VERSION ""

NS_ :

BS_:

BU_: WCM VPM VLM VKM UVM TIM TEST_TOOL_2 TEST_TOOL_1 TCP TCM TCCM3 TCCM STC SRR_SRR SRR_SLR SRR_RR SRR_RF SRR_LR_CR SRR_LF SIB SDM SCL SBZA_R SBZA_L SBM SADS RadioLow RSC RDCM PTM PDR PA NVM MTCM_R MTCM_L MSM_RR MSM_P MSM_LR MSM_D MSB2 MSB1 MRCM_R MRCM_L MFC LRR_HC LRR LIB1 IPC ICS_Info ICCM HVAC_FP_R HVAC_FP_F HUD_CAN HDLM FCM_LC FCM EPS EOCM_HCP2 EOCM_HCP1 EOCM ELM ECP_X1 ECP_MC ECP_E ECM EBCM DMS DEFC DCM CSM CMMb CMMa CGM BSM_MH BSM BCM ARS ARB APA AOS AMP ALC AHS AHL_AFL AGC

BO_ 1208 GWCGM_31_PDU: 8 CGM
 SG_ TkModeDrvlineVisDispVal : 1|3@0+ (1,0) [0|7] "" CSM,RadioLow
 SG_ TkModeBrkPedVisDispVal : 4|3@0+ (1,0) [0|7] "" CSM,RadioLow
 SG_ TkModeActvAeroVisDispVal : 7|3@0+ (1,0) [0|7] "" CSM,RadioLow
 SG_ TkModeRideHghtVisDispVal : 8|3@0+ (1,0) [0|7] "" CSM,RadioLow
 SG_ TkModePwrtrnVisDispVal : 11|3@0+ (1,0) [0|7] "" CSM,RadioLow
 SG_ TkModeESCVisDispVal : 14|3@0+ (1,0) [0|7] "" CSM,RadioLow
 SG_ TkModeSpnsnVisDispVal : 18|3@0+ (1,0) [0|7] "" CSM,RadioLow
 SG_ TkModeSndVisDispVal : 21|3@0+ (1,0) [0|7] "" CSM,RadioLow
 SG_ WthrSnwModeBrkPedVisDispVal : 25|3@0+ (1,0) [0|7] "" CSM,RadioLow
 SG_ WthrSnwModeActvAeroVisDispVal : 28|3@0+ (1,0) [0|7] "" CSM,RadioLow
 SG_ TkModeStrgVisDispVal : 31|3@0+ (1,0) [0|7] "" CSM,RadioLow
 SG_ WthrSnwModePwrtrnVisDispVal : 32|3@0+ (1,0) [0|7] "" CSM,RadioLow
 SG_ WthrSnwModeESCVisDispVal : 35|3@0+ (1,0) [0|7] "" CSM,RadioLow
 SG_ WthrSnwModeDrvlineVisDispVal : 38|3@0+ (1,0) [0|7] "" CSM,RadioLow
 SG_ WthrSnwModeSndVisDispVal : 42|3@0+ (1,0) [0|7] "" CSM,RadioLow
 SG_ WthrSnwModeRideHghtVisDispVal : 45|3@0+ (1,0) [0|7] "" CSM,RadioLow
 SG_ TrcStbScrConfig : 49|2@0+ (1,0) [0|3] "" IPC
 SG_ WthrSnwModeStrgVisDispVal : 52|3@0+ (1,0) [0|7] "" CSM,RadioLow
 SG_ WthrSnwModeSpnsnVisDispVal : 55|3@0+ (1,0) [0|7] "" CSM,RadioLow
 SG_ TrcCntrlSysTmpDisReqIO : 59|1@0+ (1,0) [0|1] "" IPC
 SG_ TrcCntrlOnIO : 60|1@0+ (1,0) [0|1] "" CSM,IPC,TCP
 SG_ TrcCntrlOffIO : 61|1@0+ (1,0) [0|1] "" CSM,IPC,TCP
 SG_ TCSCustAv : 62|1@0+ (1,0) [0|1] "" IPC
 SG_ TCSCurStat : 63|1@0+ (1,0) [0|1] "" CSM,IPC,PDR,TCP

BO_ 1209 GWCGM_32_PDU: 8 CGM
 SG_ SprtModeBrkPedVisDispVal : 1|3@0+ (1,0) [0|7] "" CSM,RadioLow
 SG_ SprtModeActvAeroVisDispVal : 4|3@0+ (1,0) [0|7] "" CSM,RadioLow
 SG_ PerfTracMgmtMode : 7|3@0+ (1,0) [0|6] "" IPC,PDR
 SG_ SprtModePwrtrnVisDispVal : 8|3@0+ (1,0) [0|7] "" CSM,RadioLow
 SG_ SprtModeESCVisDispVal : 11|3@0+ (1,0) [0|7] "" CSM,RadioLow
 SG_ SprtModeDrvlineVisDispVal : 14|3@0+ (1,0) [0|7] "" CSM,RadioLow
 SG_ SprtModeSndVisDispVal : 18|3@0+ (1,0) [0|7] "" CSM,RadioLow
 SG_ SprtModeRideHghtVisDispVal : 21|3@0+ (1,0) [0|7] "" CSM,RadioLow
 SG_ TireTrdTempSts : 25|3@0+ (1,0) [0|5] "" CSM,IPC
 SG_ SprtModeStrgVisDispVal : 28|3@0+ (1,0) [0|7] "" CSM,RadioLow
 SG_ SprtModeSpnsnVisDispVal : 31|3@0+ (1,0) [0|7] "" CSM,RadioLow
 SG_ TourModeDrvlineVisDispVal : 32|3@0+ (1,0) [0|7] "" CSM,RadioLow
 SG_ TourModeBrkPedVisDispVal : 35|3@0+ (1,0) [0|7] "" CSM,RadioLow
 SG_ TourModeActvAeroVisDispVal : 38|3@0+ (1,0) [0|7] "" CSM,RadioLow
 SG_ TourModePwrtrnVisDispVal : 42|3@0+ (1,0) [0|7] "" CSM,RadioLow
 SG_ TourModeESCVisDispVal : 45|3@0+ (1,0) [0|7] "" CSM,RadioLow
 SG_ TourModeSpnsnVisDispVal : 49|3@0+ (1,0) [0|7] "" CSM,RadioLow
 SG_ TourModeSndVisDispVal : 52|3@0+ (1,0) [0|7] "" CSM,RadioLow
 SG_ TourModeRideHghtVisDispVal : 55|3@0+ (1,0) [0|7] "" CSM,RadioLow
 SG_ TnDrvTrCtrlOffUnvIndOn : 57|1@0+ (1,0) [0|1] "" IPC
 SG_ SrBkLwBkFlDrVisMsgRqOn : 58|1@0+ (1,0) [0|1] "" IPC,TCP
 SG_ ShfToPrkBfrExtIndOn : 59|1@0+ (1,0) [0|1] "" IPC
 SG_ TourModeStrgVisDispVal : 62|3@0+ (1,0) [0|7] "" CSM,RadioLow

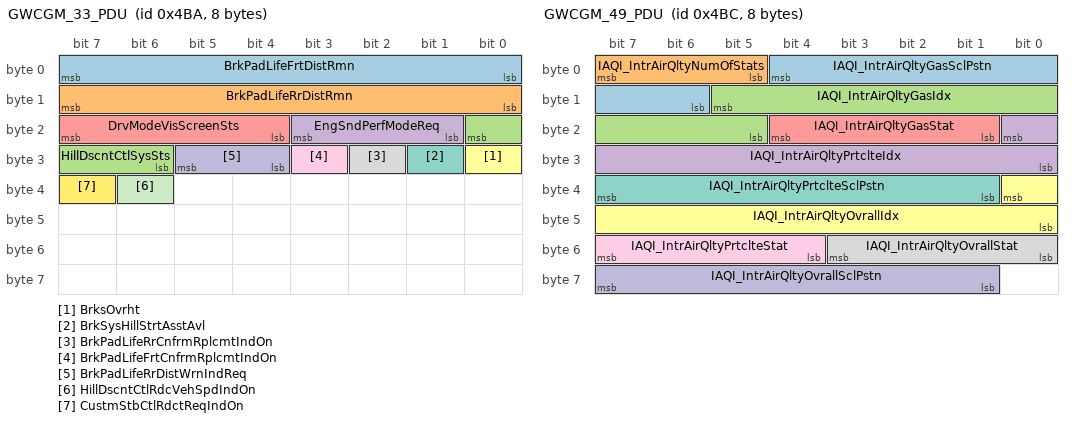
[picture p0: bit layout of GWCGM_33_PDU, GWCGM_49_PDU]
BO_ 1210 GWCGM_33_PDU: 8 CGM
 SG_ BrkPadLifeFrtDistRmn : 7|8@0+ (100,0) [0|25500] "counts" CSM,IPC
 SG_ BrkPadLifeRrDistRmn : 15|8@0+ (100,0) [0|25500] "counts" CSM,IPC
 SG_ HillDscntCtlSysSts : 16|3@0+ (1,0) [0|4] "" CSM,IPC
 SG_ EngSndPerfModeReq : 19|3@0+ (1,0) [0|7] "" AMP
 SG_ DrvModeVisScreenSts : 23|4@0+ (1,0) [0|10] "" CSM,RadioLow
 SG_ BrksOvrht : 24|1@0+ (1,0) [0|1] "" CSM,TCP
 SG_ BrkSysHillStrtAsstAvl : 25|1@0+ (1,0) [0|1] "" CSM
 SG_ BrkPadLifeRrCnfrmRplcmtIndOn : 26|1@0+ (1,0) [0|1] "" IPC
 SG_ BrkPadLifeFrtCnfrmRplcmtIndOn : 27|1@0+ (1,0) [0|1] "" IPC
 SG_ BrkPadLifeRrDistWrnIndReq : 29|2@0+ (1,0) [0|2] "" IPC
 SG_ HillDscntCtlRdcVehSpdIndOn : 38|1@0+ (1,0) [0|1] "" IPC
 SG_ CustmStbCtlRdctReqIndOn : 39|1@0+ (1,0) [0|1] "" IPC

BO_ 1236 GWCGM_34_PDU: 8 CGM
 SG_ AutMirFldCstCurSetVal : 1|3@0+ (1,0) [0|7] "" CSM,RadioLow
 SG_ AutDrvLckCstCurSetVal : 4|3@0+ (1,0) [0|7] "" CSM,RadioLow
 SG_ AirQltySnsCstCrStVal : 7|3@0+ (1,0) [0|7] "" CSM,RadioLow
 SG_ AutoCoolStCstCrStVal : 8|3@0+ (1,0) [0|7] "" CSM,RadioLow
 SG_ AutoAirDstCstCrStVal : 11|3@0+ (1,0) [0|7] "" CSM,RadioLow
 SG_ AutUnlckCstCurSetVal : 14|3@0+ (1,0) [0|7] "" CSM,RadioLow
 SG_ AutoFanCstCrStVal : 18|3@0+ (1,0) [0|7] "" CSM,RadioLow
 SG_ AutoDfgCstCrStVal : 21|3@0+ (1,0) [0|7] "" CSM,RadioLow
 SG_ DaytimeTlLghtsCstCurSetVal : 25|3@0+ (1,0) [0|7] "" CSM,RadioLow
 SG_ AutoRrWpCstCurSetVal : 28|3@0+ (1,0) [0|7] "" CSM,RadioLow
 SG_ AutoHtdStCstCrStVal : 31|3@0+ (1,0) [0|7] "" CSM,RadioLow
 SG_ AutoAirDstCstStAvl : 32|1@0+ (1,0) [0|1] "" CSM,RadioLow
 SG_ AutUnlckCstStAvl : 33|1@0+ (1,0) [0|1] "" CSM,RadioLow
 SG_ AutMirFldCstStAvl : 34|1@0+ (1,0) [0|1] "" CSM,RadioLow
 SG_ AutDrvLckCstStAvl : 35|1@0+ (1,0) [0|1] "" CSM,RadioLow
 SG_ AirQltySnsCstStAvl : 36|1@0+ (1,0) [0|1] "" CSM,RadioLow
 SG_ CurbVwFtrActvReq : 38|2@0+ (1,0) [0|2] "" CSM
 SG_ DM1Unavailable : 40|1@0+ (1,0) [0|1] "" CSM,IPC
 SG_ DM1Pending : 41|1@0+ (1,0) [0|1] "" CSM,IPC
 SG_ CrsCntCncRq : 42|1@0+ (1,0) [0|1] "" CSM
 SG_ AutoRrWpCstStAvl : 43|1@0+ (1,0) [0|1] "" CSM,RadioLow
 SG_ AutoHtdStCstStAvl : 44|1@0+ (1,0) [0|1] "" CSM,RadioLow
 SG_ AutoFanCstStAvl : 45|1@0+ (1,0) [0|1] "" CSM,RadioLow
 SG_ AutoDfgCstStAvl : 46|1@0+ (1,0) [0|1] "" CSM,RadioLow
 SG_ AutoCoolStCstStAvl : 47|1@0+ (1,0) [0|1] "" CSM,RadioLow
 SG_ DM5Unavailable : 48|1@0+ (1,0) [0|1] "" CSM,IPC
 SG_ DM5Pending : 49|1@0+ (1,0) [0|1] "" CSM,IPC
 SG_ DM4Unavailable : 50|1@0+ (1,0) [0|1] "" CSM,IPC
 SG_ DM4Pending : 51|1@0+ (1,0) [0|1] "" CSM,IPC
 SG_ DM3Unavailable : 52|1@0+ (1,0) [0|1] "" CSM,IPC
 SG_ DM3Pending : 53|1@0+ (1,0) [0|1] "" CSM,IPC
 SG_ DM2Unavailable : 54|1@0+ (1,0) [0|1] "" CSM,IPC
 SG_ DM2Pending : 55|1@0+ (1,0) [0|1] "" CSM,IPC
 SG_ DaytimeTlLghtsCstStAvl : 57|1@0+ (1,0) [0|1] "" CSM,RadioLow
 SG_ DM8Unavailable : 58|1@0+ (1,0) [0|1] "" CSM,IPC
 SG_ DM8Pending : 59|1@0+ (1,0) [0|1] "" CSM,IPC
 SG_ DM7Unavailable : 60|1@0+ (1,0) [0|1] "" CSM,IPC
 SG_ DM7Pending : 61|1@0+ (1,0) [0|1] "" CSM,IPC
 SG_ DM6Unavailable : 62|1@0+ (1,0) [0|1] "" CSM,IPC
 SG_ DM6Pending : 63|1@0+ (1,0) [0|1] "" CSM,IPC

BO_ 1237 GWCGM_35_PDU: 8 CGM
 SG_ IntDimSeldAnmTypStVal : 2|4@0+ (1,0) [0|15] "" CSM,RadioLow
 SG_ IntDimSeldClrTypStVal : 7|5@0+ (1,0) [0|31] "" CSM,RadioLow
 SG_ IonzrCtrlCstCrStVal : 8|3@0+ (1,0) [0|7] "" CSM,RadioLow
 SG_ HFRCCstCurSetVal : 11|3@0+ (1,0) [0|7] "" CSM,RadioLow
 SG_ ExtLghtCstCurSetVal : 14|3@0+ (1,0) [0|7] "" CSM,RadioLow
 SG_ OpDrAtLOCstCurSetVal : 18|3@0+ (1,0) [0|7] "" CSM,RadioLow
 SG_ LDCLCstCurSetVal : 21|3@0+ (1,0) [0|7] "" CSM,RadioLow
 SG_ RlkRtUlkDrCstCrSetVal : 25|3@0+ (1,0) [0|7] "" CSM,RadioLow
 SG_ PsvUnlckCstCurSetVal : 28|3@0+ (1,0) [0|7] "" CSM,RadioLow
 SG_ PlltnCtrlCstCrStVal : 31|3@0+ (1,0) [0|7] "" CSM,RadioLow
 SG_ RrStRmndrEnblDsblCstCurrSetVal : 32|3@0+ (1,0) [0|7] "" CSM,RadioLow
 SG_ RrDfgStUpCstCrStVal : 35|3@0+ (1,0) [0|7] "" CSM,RadioLow
 SG_ RnSnsCstCurSetVal : 38|3@0+ (1,0) [0|7] "" CSM,RadioLow
 SG_ ExtLghtCstStAvl : 40|1@0+ (1,0) [0|1] "" CSM,RadioLow
 SG_ RrAirHandlingDrActrPwrReq : 42|2@0+ (1,0) [0|2] "" HVAC_FP_R
 SG_ RrZnStUpCstCrStVal : 45|3@0+ (1,0) [0|7] "" CSM,RadioLow
 SG_ RnSnsCstStAvl : 48|1@0+ (1,0) [0|1] "" CSM,RadioLow
 SG_ RlkRtUlkDrCstStAvl : 49|1@0+ (1,0) [0|1] "" CSM,RadioLow
 SG_ PsvUnlckCstStAvl : 50|1@0+ (1,0) [0|1] "" CSM,RadioLow
 SG_ PlltnCtrlCstStAvl : 51|1@0+ (1,0) [0|1] "" CSM,RadioLow
 SG_ OpDrAtLOCstStAvl : 52|1@0+ (1,0) [0|1] "" CSM,RadioLow
 SG_ LDCLCstStAvl : 53|1@0+ (1,0) [0|1] "" CSM,RadioLow
 SG_ IonzrCtrlCstStAvl : 54|1@0+ (1,0) [0|1] "" CSM,RadioLow
 SG_ HFRCCstStAvl : 55|1@0+ (1,0) [0|1] "" CSM,RadioLow
 SG_ RrZnStUpCstStAvl : 61|1@0+ (1,0) [0|1] "" CSM,RadioLow
 SG_ RrStRmndrEnblDsblCstSetAval : 62|1@0+ (1,0) [0|1] "" CSM,RadioLow
 SG_ RrDfgStUpCstStAvl : 63|1@0+ (1,0) [0|1] "" CSM,RadioLow

BO_ 1238 GWCGM_36_PDU: 8 CGM
 SG_ RmtReFlshElecPwrRdnes : 7|8@0+ (0.025,0) [0|6.375] "AmpHr" CSM,RadioLow,TCP
 SG_ RevTltMirCstCurSetVal : 9|3@0+ (1,0) [0|7] "" CSM,RadioLow
 SG_ RemLftVehRmndrCstCurSetVal : 12|3@0+ (1,0) [0|7] "" CSM,RadioLow
 SG_ RemInVehRmndrCstCurSetVal : 15|3@0+ (1,0) [0|7] "" CSM,RadioLow
 SG_ RmtStrtHtdStCstCrStVal : 16|3@0+ (1,0) [0|7] "" CSM,RadioLow
 SG_ RmtStrtCoolStCstCrStVal : 19|3@0+ (1,0) [0|7] "" CSM,RadioLow
 SG_ RmtSnrfOpCstCurrSetVal : 22|3@0+ (1,0) [0|7] "" CSM,RadioLow
 SG_ RtLkFdbkCstCurSetVal : 26|3@0+ (1,0) [0|7] "" CSM,RadioLow
 SG_ RmtWndOpCstCurSetVal : 29|3@0+ (1,0) [0|7] "" CSM,RadioLow
 SG_ VehLctrLghtsCstCurSetVal : 33|3@0+ (1,0) [0|7] "" CSM,RadioLow
 SG_ SelUlkCstCurSetVal : 36|3@0+ (1,0) [0|7] "" CSM,RadioLow
 SG_ RtUlkLtFbCstCurSetVal : 39|3@0+ (1,0) [0|7] "" CSM,RadioLow
 SG_ RemLftVehRmndrCstStAvl : 40|1@0+ (1,0) [0|1] "" CSM,RadioLow
 SG_ RemInVehRmndrCstStAvl : 41|1@0+ (1,0) [0|1] "" CSM,RadioLow
 SG_ TrnSwAct : 43|2@0+ (1,0) [0|2] "" CSM,IPC
 SG_ WlkAwyLckCstCurSetVal : 46|3@0+ (1,0) [0|7] "" CSM,RadioLow
 SG_ SelUlkCstStAvl : 48|1@0+ (1,0) [0|1] "" CSM,RadioLow
 SG_ RtUlkLtFbCstStAvl : 49|1@0+ (1,0) [0|1] "" CSM,RadioLow
 SG_ RtLkFdbkCstStAvl : 50|1@0+ (1,0) [0|1] "" CSM,RadioLow
 SG_ RmtWndOpCstStAvl : 51|1@0+ (1,0) [0|1] "" CSM,RadioLow
 SG_ RmtStrtHtdStCstStAvl : 52|1@0+ (1,0) [0|1] "" CSM,RadioLow
 SG_ RmtStrtCoolStCstStAvl : 53|1@0+ (1,0) [0|1] "" CSM,RadioLow
 SG_ RmtSnrfOpCstSetAval : 54|1@0+ (1,0) [0|1] "" CSM,RadioLow
 SG_ RevTltMirCstStAvl : 55|1@0+ (1,0) [0|1] "" CSM,RadioLow
 SG_ WprFrActFltdStat : 59|1@0+ (1,0) [0|1] "" CSM,TCP
 SG_ WlkAwyLckCstStAvl : 60|1@0+ (1,0) [0|1] "" CSM,RadioLow
 SG_ VehLctrLghtsCstStAvl : 61|1@0+ (1,0) [0|1] "" CSM,RadioLow
 SG_ TnDrvSpdLmtCstStAvl : 62|1@0+ (1,0) [0|1] "" CSM,RadioLow,TCP
 SG_ TnDrvOvSpdWrnCstStAvl : 63|1@0+ (1,0) [0|1] "" CSM,RadioLow,TCP

BO_ 1239 GWCGM_37_PDU: 8 CGM
 SG_ IHVSLF_HtdBckLvl1 : 0|1@0+ (1,0) [0|1] "" HVAC_FP_F,IPC
 SG_ IHVSLF_HtdCushBckMd : 1|1@0+ (1,0) [0|1] "" HVAC_FP_F,IPC
 SG_ IHVSLF_HtdBckLvl3 : 2|1@0+ (1,0) [0|1] "" HVAC_FP_F,IPC
 SG_ IHVSLF_HtdCushBckLvl3 : 3|1@0+ (1,0) [0|1] "" HVAC_FP_F,IPC
 SG_ IHVSLF_HtdCushBckAuto : 4|1@0+ (1,0) [0|1] "" HVAC_FP_F,IPC
 SG_ IHVSLF_VntLvl1 : 5|1@0+ (1,0) [0|1] "" HVAC_FP_F,IPC
 SG_ IHVSLF_HtdBckAuto : 6|1@0+ (1,0) [0|1] "" HVAC_FP_F,IPC
 SG_ IHVSLF_VntLvl2 : 7|1@0+ (1,0) [0|1] "" HVAC_FP_F,IPC
 SG_ IHVSRF_HtdBckMd : 8|1@0+ (1,0) [0|1] "" HVAC_FP_F,IPC
 SG_ IHVSLF_VntLvl3 : 9|1@0+ (1,0) [0|1] "" HVAC_FP_F,IPC
 SG_ IHVSLF_HtdBckLvl2 : 10|1@0+ (1,0) [0|1] "" HVAC_FP_F,IPC
 SG_ IHVSLF_HtdBckMd : 11|1@0+ (1,0) [0|1] "" HVAC_FP_F,IPC
 SG_ IHVSLF_HtdCushBckLvl1 : 12|1@0+ (1,0) [0|1] "" HVAC_FP_F,IPC
 SG_ IHVSLF_VntAuto : 13|1@0+ (1,0) [0|1] "" HVAC_FP_F,IPC
 SG_ IHVSLF_HtdCushBckLvl2 : 14|1@0+ (1,0) [0|1] "" HVAC_FP_F,IPC
 SG_ IHVSLF_VntMd : 15|1@0+ (1,0) [0|1] "" HVAC_FP_F,IPC
 SG_ IHVSRF_VntLvl2 : 16|1@0+ (1,0) [0|1] "" HVAC_FP_F,IPC
 SG_ IHVSRF_HtdCushBckMd : 17|1@0+ (1,0) [0|1] "" HVAC_FP_F,IPC
 SG_ IHVSRF_HtdBckLvl3 : 18|1@0+ (1,0) [0|1] "" HVAC_FP_F,IPC
 SG_ IHVSRF_HtdCushBckAuto : 19|1@0+ (1,0) [0|1] "" HVAC_FP_F,IPC
 SG_ IHVSRF_HtdCushBckLvl3 : 20|1@0+ (1,0) [0|1] "" HVAC_FP_F,IPC
 SG_ IHVSRF_HtdBckAuto : 21|1@0+ (1,0) [0|1] "" HVAC_FP_F,IPC
 SG_ IHVSRF_HtdCushBckLvl1 : 22|1@0+ (1,0) [0|1] "" HVAC_FP_F,IPC
 SG_ IHVSRF_VntLvl1 : 23|1@0+ (1,0) [0|1] "" HVAC_FP_F,IPC
 SG_ TDOSWCCSV_CrSetVal : 25|3@0+ (1,0) [0|7] "" CSM,IPC,RadioLow,TCP
 SG_ IHVSRF_VntAuto : 26|1@0+ (1,0) [0|1] "" HVAC_FP_F,IPC
 SG_ IHVSRF_HtdBckLvl1 : 27|1@0+ (1,0) [0|1] "" HVAC_FP_F,IPC
 SG_ IHVSRF_HtdBckLvl2 : 28|1@0+ (1,0) [0|1] "" HVAC_FP_F,IPC
 SG_ IHVSRF_VntLvl3 : 29|1@0+ (1,0) [0|1] "" HVAC_FP_F,IPC
 SG_ IHVSRF_HtdCushBckLvl2 : 30|1@0+ (1,0) [0|1] "" HVAC_FP_F,IPC
 SG_ IHVSRF_VntMd : 31|1@0+ (1,0) [0|1] "" HVAC_FP_F,IPC
 SG_ TDOSWCCSV_DspVal : 38|12@0+ (0.0625,0) [0|255.938] "km/h" CSM,RadioLow,TCP
 SG_ TDSLCCSV_DspVal : 42|8@0+ (2,0) [0|510] "km/h" CSM,RadioLow,TCP
 SG_ TDSLCCSV_CrSetVal : 50|3@0+ (1,0) [0|7] "" CSM,RadioLow,TCP

BO_ 1211 GWCGM_46_PDU: 8 CGM
 SG_ ClmCtlFrtBlwFanSpdFdbkRtlzd : 6|8@0+ (0.392157,0) [0|100] "%" CSM,IPC
 SG_ AmbtLgtMnMenuTyp : 9|3@0+ (1,0) [0|7] "" CSM,RadioLow
 SG_ ConThftAlrmTrg : 14|5@0+ (1,0) [0|19] "" TCP,VKM
 SG_ BattVltIRq : 17|2@0+ (1,0) [0|3] "" CSM,IPC,TCP
 SG_ AlrmClckMgrAlrmCmdFtr6 : 19|2@0+ (1,0) [0|2] "" CSM,RadioLow
 SG_ BdyCtlTopSpdLimSrc : 22|3@0+ (1,0) [0|7] "" IPC
 SG_ BdyCtlTopSpdLimIndOn : 24|1@0+ (1,0) [0|1] "" IPC
 SG_ BdyCtlAccelLimIndOn : 25|1@0+ (1,0) [0|1] "" IPC
 SG_ BatLoStrtVehIndOn : 26|1@0+ (1,0) [0|1] "" IPC,TCP
 SG_ AutoLgtsInActvIndOn : 27|1@0+ (1,0) [0|1] "" CSM,IPC
 SG_ AutoLgtsActvIndOn : 28|1@0+ (1,0) [0|1] "" CSM,IPC
 SG_ ACCmpsrOprtng : 29|1@0+ (1,0) [0|1] "" TCP
 SG_ HtdFrntWSSt : 31|2@0+ (1,0) [0|2] "" IPC
 SG_ ConThftAttmpdIO : 32|1@0+ (1,0) [0|1] "" CSM,IPC,TCP
 SG_ CnvtBkWndNotNormzIO : 33|1@0+ (1,0) [0|1] "" IPC
 SG_ CmpSftTopMotBfrOpTrnkIO : 34|1@0+ (1,0) [0|1] "" CSM,IPC
 SG_ CmbdDrHndlActvRF : 35|1@0+ (1,0) [0|1] "" CSM
 SG_ CmbdDrHndlActvLF : 36|1@0+ (1,0) [0|1] "" CSM
 SG_ ClmSysDfgRdcdIndOn : 37|1@0+ (1,0) [0|1] "" IPC
 SG_ ClmSysDfgActvIndOn : 38|1@0+ (1,0) [0|1] "" IPC
 SG_ ClmCtlBatSvrIndOn : 39|1@0+ (1,0) [0|1] "" IPC
 SG_ FobProgMdStatCmplt : 40|1@0+ (1,0) [0|1] "" IPC
 SG_ FobPrevLrndIndOn : 41|1@0+ (1,0) [0|1] "" IPC
 SG_ FobPogLimRchdIndOn : 42|1@0+ (1,0) [0|1] "" IPC
 SG_ EntrFobProgIndOn : 43|1@0+ (1,0) [0|1] "" IPC
 SG_ DlydAccTmrActv : 44|1@0+ (1,0) [0|1] "" WCM
 SG_ CrgLghtEnbldIO : 45|1@0+ (1,0) [0|1] "" IPC
 SG_ CrgLghtDsbldIO : 46|1@0+ (1,0) [0|1] "" IPC
 SG_ ConThftSrvcIO : 47|1@0+ (1,0) [0|1] "" CSM,IPC,TCP
 SG_ HiVltgHtrFaildIndOn : 48|1@0+ (1,0) [0|1] "" IPC
 SG_ HiBmIO : 49|1@0+ (1,0) [0|1] "" CSM,IPC
 SG_ HazSwAtvIO : 50|1@0+ (1,0) [0|1] "" CSM,IPC
 SG_ HVAC_StngsCtrlAvlbl : 51|1@0+ (1,0) [0|1] "" CSM,HVAC_FP_F,HVAC_FP_R,RadioLow
 SG_ FrtSnshdNormzRqrdIO : 52|1@0+ (1,0) [0|1] "" IPC
 SG_ FrtCmptServIndOn : 53|1@0+ (1,0) [0|1] "" IPC
 SG_ FrtClmAppFltDtnActv : 54|1@0+ (1,0) [0|1] "" CSM,RadioLow
 SG_ FuelOprtdHtrOprtgMode : 61|3@0+ (1,0) [0|4] "" VKM
 SG_ HtdFrtWshldUnvIndOn : 62|1@0+ (1,0) [0|1] "" IPC
 SG_ HiVltgHtrOvrTempIndOn : 63|1@0+ (1,0) [0|1] "" IPC

BO_ 1212 GWCGM_49_PDU: 8 CGM
 SG_ IAQI_IntrAirQltyGasSclPstn : 4|7@0+ (1,0) [0|127] "" CSM,RadioLow
 SG_ IAQI_IntrAirQltyNumOfStats : 7|3@0+ (1,2) [2|9] "" CSM,RadioLow
 SG_ IAQI_IntrAirQltyGasIdx : 13|9@0+ (1,0) [0|511] "" CSM,RadioLow
 SG_ IAQI_IntrAirQltyPrtclteIdx : 16|9@0+ (1,0) [0|511] "" CSM,RadioLow
 SG_ IAQI_IntrAirQltyGasStat : 20|4@0+ (1,0) [0|9] "" CSM,RadioLow
 SG_ IAQI_IntrAirQltyOvrallIdx : 32|9@0+ (1,0) [0|511] "" CSM,RadioLow
 SG_ IAQI_IntrAirQltyPrtclteSclPstn : 39|7@0+ (1,0) [0|127] "" CSM,RadioLow
 SG_ IAQI_IntrAirQltyOvrallStat : 51|4@0+ (1,0) [0|9] "" CSM,RadioLow
 SG_ IAQI_IntrAirQltyPrtclteStat : 55|4@0+ (1,0) [0|9] "" CSM,RadioLow
 SG_ IAQI_IntrAirQltyOvrallSclPstn : 63|7@0+ (1,0) [0|127] "" CSM,RadioLow

BO_ 1213 GWCGM_50_PDU: 6 CGM
 SG_ TDRCADD_WOTEvnts : 0|1@0+ (1,0) [0|1] "" CSM,RadioLow,TCP
 SG_ TDRCADD_StCtrlEvnts : 1|1@0+ (1,0) [0|1] "" CSM,RadioLow,TCP
 SG_ TDRCADD_OvrSpdDistDrvn : 2|1@0+ (1,0) [0|1] "" CSM,RadioLow,TCP
 SG_ TDRCADD_ABSAtvEvt : 3|1@0+ (1,0) [0|1] "" CSM,RadioLow,TCP
 SG_ TDRCADD_DistDrvn : 4|1@0+ (1,0) [0|1] "" CSM,RadioLow,TCP
 SG_ TDRCADD_FCHdwyAlrt : 5|1@0+ (1,0) [0|1] "" CSM,RadioLow,TCP
 SG_ TDRCADD_LKAstAlrtsEvnts : 6|1@0+ (1,0) [0|1] "" CSM,RadioLow,TCP
 SG_ TDRCADD_MaxSpd : 7|1@0+ (1,0) [0|1] "" CSM,RadioLow,TCP
 SG_ TDRCADD_TrCtrlEvnts : 8|1@0+ (1,0) [0|1] "" CSM,RadioLow,TCP
 SG_ TDRCADD_FCMBrEvts : 9|1@0+ (1,0) [0|1] "" CSM,RadioLow,TCP
 SG_ TDRCADD_LDWEvnts : 10|1@0+ (1,0) [0|1] "" CSM,RadioLow,TCP
 SG_ TDRCADD_RCMBrEvts : 11|1@0+ (1,0) [0|1] "" CSM,RadioLow,TCP
 SG_ TDRCADD_OvSpdEvnt : 12|1@0+ (1,0) [0|1] "" CSM,RadioLow,TCP
 SG_ TDRCADD_DrwDrvAlrt : 13|1@0+ (1,0) [0|1] "" CSM,RadioLow,TCP
 SG_ TDRCADD_FCImntAlrts : 14|1@0+ (1,0) [0|1] "" CSM,RadioLow,TCP
 SG_ TDRCADD_UnbckldDistDrvn : 15|1@0+ (1,0) [0|1] "" CSM,RadioLow,TCP
 SG_ WndNormzRR : 16|1@0+ (1,0) [0|1] "" CSM
 SG_ WndNormzRF : 17|1@0+ (1,0) [0|1] "" CSM
 SG_ WndNormzLR : 18|1@0+ (1,0) [0|1] "" CSM
 SG_ WndNormzLF : 19|1@0+ (1,0) [0|1] "" CSM
 SG_ VTDDrvMsgIO : 20|1@0+ (1,0) [0|1] "" IPC
 SG_ VTDDrvIndReq : 23|3@0+ (1,0) [0|6] "" IPC
 SG_ WndNtNrmzdIORR : 28|1@0+ (1,0) [0|1] "" IPC
 SG_ WndNtNrmzdIOLR : 29|1@0+ (1,0) [0|1] "" IPC
 SG_ WndNtNrmzdIODrv : 30|1@0+ (1,0) [0|1] "" IPC
 SG_ WndNtNrmzdIOCoDrv : 31|1@0+ (1,0) [0|1] "" IPC

BO_ 1214 GWCGM_51_PDU: 8 CGM
 SG_ TnDrvUnbckldDistDrvn : 7|16@0+ (1,0) [0|65535] "km" CSM,RadioLow,TCP
 SG_ TeenDrvWOTEvntsRpt : 23|10@0+ (1,0) [0|1023] "Counts" CSM,RadioLow,TCP
 SG_ TirePrsStatLR : 24|3@0+ (1,0) [0|5] "" CSM,IPC,PDR,RadioLow,TCP,VKM
 SG_ TirePrsStatLR_Inv : 25|1@0+ (1,0) [0|1] "" IPC,RadioLow,VKM
 SG_ TirePrsStatLF : 28|3@0+ (1,0) [0|5] "" CSM,IPC,PDR,RadioLow,TCP,VKM
 SG_ TirePrsStatLF_Inv : 29|1@0+ (1,0) [0|1] "" IPC,RadioLow,VKM
 SG_ TirePrsStatRR : 32|3@0+ (1,0) [0|5] "" CSM,IPC,PDR,RadioLow,TCP,VKM
 SG_ TirePrsStatRR_Inv : 33|1@0+ (1,0) [0|1] "" IPC,RadioLow,VKM
 SG_ TirePrsStatRF : 36|3@0+ (1,0) [0|5] "" CSM,IPC,PDR,RadioLow,TCP,VKM
 SG_ TirePrsStatRF_Inv : 37|1@0+ (1,0) [0|1] "" IPC,RadioLow,VKM
 SG_ TrPrsMntrTrLdStat : 43|2@0+ (1,0) [0|3] "" CSM,IPC,RadioLow
 SG_ TrlrLtngSeqStat : 48|1@0+ (1,0) [0|1] "" CSM,RadioLow,TCP
 SG_ TrPrsMntrSysFld : 49|1@0+ (1,0) [0|1] "" CSM,IPC,RadioLow
 SG_ TlmtcsImmbAtv : 50|1@0+ (1,0) [0|1] "" TCP
 SG_ TirePrsLrnActIO : 51|1@0+ (1,0) [0|1] "" CSM,IPC
 SG_ TireLocatnWarnEn : 52|1@0+ (1,0) [0|1] "" CSM,IPC,RadioLow
 SG_ TPMTrLrnMdCmplt : 53|1@0+ (1,0) [0|1] "" CSM,IPC,RadioLow
 SG_ ValetMdResponse : 55|2@0+ (1,0) [0|3] "" CSM,RadioLow,TCP
 SG_ XmtrSecurConfRqrdIO : 57|1@0+ (1,0) [0|1] "" CSM,IPC
 SG_ VehLoBatIndOn : 58|1@0+ (1,0) [0|1] "" IPC
 SG_ UIDInStatusSD : 59|1@0+ (1,0) [0|1] "" CSM,RadioLow,TCP
 SG_ TxLrnFldIO : 60|1@0+ (1,0) [0|1] "" IPC
 SG_ TxBkUpLctIO : 61|1@0+ (1,0) [0|1] "" IPC
 SG_ TurnWprIntIO : 62|1@0+ (1,0) [0|1] "" CSM,IPC
 SG_ TrnstStrgLogisticsMdActivation : 63|1@0+ (1,0) [0|1] "" CSM,RadioLow

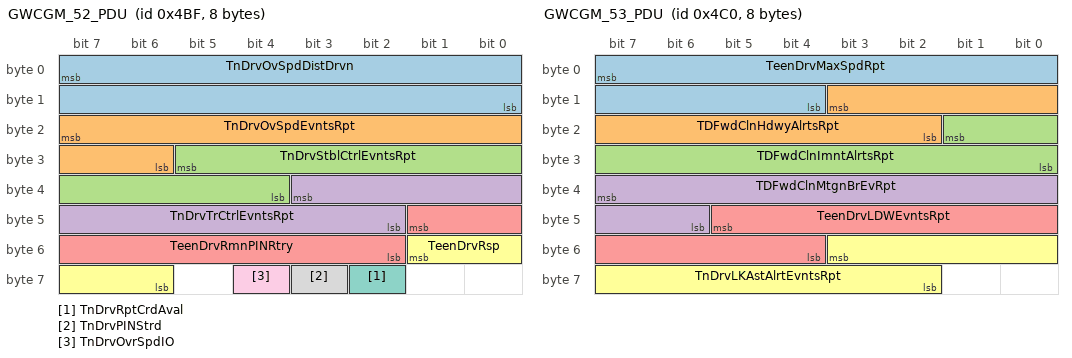
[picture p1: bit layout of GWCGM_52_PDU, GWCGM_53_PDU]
BO_ 1215 GWCGM_52_PDU: 8 CGM
 SG_ TnDrvOvSpdDistDrvn : 7|16@0+ (1,0) [0|65535] "km" CSM,RadioLow,TCP
 SG_ TnDrvOvSpdEvntsRpt : 23|10@0+ (1,0) [0|1023] "Counts" CSM,RadioLow,TCP
 SG_ TnDrvStblCtrlEvntsRpt : 29|10@0+ (1,0) [0|1023] "Counts" CSM,RadioLow,TCP
 SG_ TnDrvTrCtrlEvntsRpt : 35|10@0+ (1,0) [0|1023] "Counts" CSM,RadioLow,TCP
 SG_ TeenDrvRmnPINRtry : 41|8@0+ (1,0) [0|255] "msec" CSM,RadioLow
 SG_ TeenDrvRsp : 49|4@0+ (1,0) [0|9] "" CSM,RadioLow,TCP
 SG_ TnDrvRptCrdAval : 58|1@0+ (1,0) [0|1] "" CSM,RadioLow
 SG_ TnDrvPINStrd : 59|1@0+ (1,0) [0|1] "" CSM,RadioLow,TCP
 SG_ TnDrvOvrSpdIO : 60|1@0+ (1,0) [0|1] "" IPC,TCP

BO_ 1216 GWCGM_53_PDU: 8 CGM
 SG_ TeenDrvMaxSpdRpt : 7|12@0+ (0.0625,0) [0|255.938] "km/h" CSM,RadioLow,TCP
 SG_ TDFwdClnHdwyAlrtsRpt : 11|10@0+ (1,0) [0|1023] "Counts" CSM,RadioLow,TCP
 SG_ TDFwdClnImntAlrtsRpt : 17|10@0+ (1,0) [0|1023] "Counts" CSM,RadioLow,TCP
 SG_ TDFwdClnMtgnBrEvRpt : 39|10@0+ (1,0) [0|1023] "Counts" CSM,RadioLow,TCP
 SG_ TeenDrvLDWEvntsRpt : 45|10@0+ (1,0) [0|1023] "Counts" CSM,RadioLow,TCP
 SG_ TnDrvLKAstAlrtEvntsRpt : 51|10@0+ (1,0) [0|1023] "" CSM,RadioLow,TCP

BO_ 1217 GWCGM_54_PDU: 8 CGM
 SG_ TnDrvDistDrvnRpt : 7|16@0+ (1,0) [0|65535] "km" CSM,RadioLow,TCP
 SG_ TnDrvABSAtvEvntsRpt : 23|10@0+ (1,0) [0|1023] "Counts" CSM,RadioLow,TCP
 SG_ TnDrvDrowDrvAlrtsRpt : 29|10@0+ (1,0) [0|1023] "Counts" CSM,RadioLow,TCP
 SG_ RemCtrlFobNumForProg : 35|4@0+ (1,0) [0|15] "" CSM,IPC
 SG_ DrExtHndlActnStatRR : 40|1@0+ (1,0) [0|1] "" CSM,RadioLow
 SG_ DrExtHndlActnStatRF : 41|1@0+ (1,0) [0|1] "" CSM,RadioLow
 SG_ SnrfPstnSts : 44|3@0+ (1,0) [0|4] "" AMP,TCP,VKM
 SG_ ServPwrLftgtIndOn : 48|1@0+ (1,0) [0|1] "" IPC
 SG_ ServKylsStSysIO : 49|1@0+ (1,0) [0|1] "" IPC,TCP
 SG_ ServHtdStrgWhlIndOn : 50|1@0+ (1,0) [0|1] "" IPC
 SG_ ServDrLtchSysIO : 51|1@0+ (1,0) [0|1] "" IPC
 SG_ ServBatChrgSysIndOn : 52|1@0+ (1,0) [0|1] "" IPC,TCP
 SG_ RmtCtlFobBatLoIndOn : 53|1@0+ (1,0) [0|1] "" IPC,VKM
 SG_ DrIntHndlActnStatRR : 54|1@0+ (1,0) [0|1] "" CSM,RadioLow
 SG_ DrIntHndlActnStatRF : 55|1@0+ (1,0) [0|1] "" CSM,RadioLow
 SG_ TnDrvDRLOffUnbIO : 57|1@0+ (1,0) [0|1] "" IPC,TCP
 SG_ TnDrvALCOffUnbIO : 58|1@0+ (1,0) [0|1] "" IPC,TCP
 SG_ TeenDrvFtrAvl : 59|1@0+ (1,0) [0|1] "" CSM,RadioLow,TCP
 SG_ StlthModeActv : 60|1@0+ (1,0) [0|1] "" IPC
 SG_ StNtLtchdThrdRowIO : 61|1@0+ (1,0) [0|1] "" IPC
 SG_ SnrfNormzRqrdIO : 62|1@0+ (1,0) [0|1] "" IPC,TCP
 SG_ ShftoNeutIndOn : 63|1@0+ (1,0) [0|1] "" IPC

BO_ 1218 GWCGM_55_PDU: 8 CGM
 SG_ RrBlwCmd : 7|10@0+ (0.09765,0) [0|99.8959] "%" HVAC_FP_R
 SG_ DrExtHndlActnStatLF : 8|1@0+ (1,0) [0|1] "" CSM,RadioLow
 SG_ LstKyFbFnctnReq : 13|5@0+ (1,0) [0|20] "" CSM,RadioLow
 SG_ IndLowSpdPlltnTkngRecircActMsg : 16|1@0+ (1,0) [0|1] "" CSM,RadioLow
 SG_ IndIntrAirQltyDispActv : 17|1@0+ (1,0) [0|1] "" CSM,RadioLow
 SG_ IndFogPrtcTkngFrshAirActMsg : 18|1@0+ (1,0) [0|1] "" CSM,RadioLow
 SG_ IndAirQltSysTkngRecircActMsg : 19|1@0+ (1,0) [0|1] "" CSM,RadioLow
 SG_ IndAC_OnBatCoolMsg : 20|1@0+ (1,0) [0|1] "" CSM,RadioLow,TCP
 SG_ DrIntHndlActnStatLR : 21|1@0+ (1,0) [0|1] "" CSM,RadioLow
 SG_ DrIntHndlActnStatLF : 22|1@0+ (1,0) [0|1] "" CSM,RadioLow
 SG_ DrExtHndlActnStatLR : 23|1@0+ (1,0) [0|1] "" CSM,RadioLow
 SG_ PwrLftgtOffIndOn : 24|1@0+ (1,0) [0|1] "" IPC
 SG_ PrkLmpIO : 25|1@0+ (1,0) [0|1] "" CSM,IPC
 SG_ NghtSchmAtv : 26|1@0+ (1,0) [0|1] "" CSM,IPC,MFC,RadioLow,TCP
 SG_ LdShedRdcdFtrsIndOn : 27|1@0+ (1,0) [0|1] "" IPC
 SG_ KyIdDevNotPrIO : 28|1@0+ (1,0) [0|1] "" IPC
 SG_ KeyInWrnIO : 29|1@0+ (1,0) [0|1] "" IPC
 SG_ IntrSnsDsbld : 30|1@0+ (1,0) [0|1] "" IPC
 SG_ IndTmpUnts : 31|1@0+ (1,0) [0|1] "" CSM,HVAC_FP_F,HVAC_FP_R,RadioLow
 SG_ IndInzrStat : 32|3@0+ (1,0) [0|4] "" CSM,HVAC_FP_F,RadioLow
 SG_ RrStRmndrIndOn : 33|1@0+ (1,0) [0|1] "" IPC
 SG_ RrSnshdNormzRqrdIO : 34|1@0+ (1,0) [0|1] "" IPC
 SG_ RrDrUnlckIO : 36|1@0+ (1,0) [0|1] "" IPC
 SG_ RnSnsOffIO : 37|1@0+ (1,0) [0|1] "" CSM,IPC
 SG_ RnSnsActIO : 38|1@0+ (1,0) [0|1] "" CSM,IPC
 SG_ PwrLftgtUnvIndOn : 39|1@0+ (1,0) [0|1] "" IPC

BO_ 1175 GWCGM_56_PDU: 8 CGM
 SG_ AutDrvLckCstAvlFlg1 : 0|1@0+ (1,0) [0|1] "" CSM,RadioLow
 SG_ AirQltySnsCstAvlFlg7 : 1|1@0+ (1,0) [0|1] "" CSM,RadioLow
 SG_ AirQltySnsCstAvlFlg6 : 2|1@0+ (1,0) [0|1] "" CSM,RadioLow
 SG_ AirQltySnsCstAvlFlg5 : 3|1@0+ (1,0) [0|1] "" CSM,RadioLow
 SG_ AirQltySnsCstAvlFlg4 : 4|1@0+ (1,0) [0|1] "" CSM,RadioLow
 SG_ AirQltySnsCstAvlFlg3 : 5|1@0+ (1,0) [0|1] "" CSM,RadioLow
 SG_ AirQltySnsCstAvlFlg2 : 6|1@0+ (1,0) [0|1] "" CSM,RadioLow
 SG_ AirQltySnsCstAvlFlg1 : 7|1@0+ (1,0) [0|1] "" CSM,RadioLow
 SG_ AutMirFldCstAvlFlg2 : 8|1@0+ (1,0) [0|1] "" CSM,RadioLow
 SG_ AutMirFldCstAvlFlg1 : 9|1@0+ (1,0) [0|1] "" CSM,RadioLow
 SG_ AutDrvLckCstAvlFlg7 : 10|1@0+ (1,0) [0|1] "" CSM,RadioLow
 SG_ AutDrvLckCstAvlFlg6 : 11|1@0+ (1,0) [0|1] "" CSM,RadioLow
 SG_ AutDrvLckCstAvlFlg5 : 12|1@0+ (1,0) [0|1] "" CSM,RadioLow
 SG_ AutDrvLckCstAvlFlg4 : 13|1@0+ (1,0) [0|1] "" CSM,RadioLow
 SG_ AutDrvLckCstAvlFlg3 : 14|1@0+ (1,0) [0|1] "" CSM,RadioLow
 SG_ AutDrvLckCstAvlFlg2 : 15|1@0+ (1,0) [0|1] "" CSM,RadioLow
 SG_ AutUnlckCstAvlFlg3 : 16|1@0+ (1,0) [0|1] "" CSM,RadioLow
 SG_ AutUnlckCstAvlFlg2 : 17|1@0+ (1,0) [0|1] "" CSM,RadioLow
 SG_ AutUnlckCstAvlFlg1 : 18|1@0+ (1,0) [0|1] "" CSM,RadioLow
 SG_ AutMirFldCstAvlFlg7 : 19|1@0+ (1,0) [0|1] "" CSM,RadioLow
 SG_ AutMirFldCstAvlFlg6 : 20|1@0+ (1,0) [0|1] "" CSM,RadioLow
 SG_ AutMirFldCstAvlFlg5 : 21|1@0+ (1,0) [0|1] "" CSM,RadioLow
 SG_ AutMirFldCstAvlFlg4 : 22|1@0+ (1,0) [0|1] "" CSM,RadioLow
 SG_ AutMirFldCstAvlFlg3 : 23|1@0+ (1,0) [0|1] "" CSM,RadioLow
 SG_ AutoAirDstCstAvlFlg4 : 24|1@0+ (1,0) [0|1] "" CSM,RadioLow,TCP
 SG_ AutoAirDstCstAvlFlg3 : 25|1@0+ (1,0) [0|1] "" CSM,RadioLow,TCP
 SG_ AutoAirDstCstAvlFlg2 : 26|1@0+ (1,0) [0|1] "" CSM,RadioLow,TCP
 SG_ AutoAirDstCstAvlFlg1 : 27|1@0+ (1,0) [0|1] "" CSM,RadioLow,TCP
 SG_ AutUnlckCstAvlFlg7 : 28|1@0+ (1,0) [0|1] "" CSM,RadioLow
 SG_ AutUnlckCstAvlFlg6 : 29|1@0+ (1,0) [0|1] "" CSM,RadioLow
 SG_ AutUnlckCstAvlFlg5 : 30|1@0+ (1,0) [0|1] "" CSM,RadioLow
 SG_ AutUnlckCstAvlFlg4 : 31|1@0+ (1,0) [0|1] "" CSM,RadioLow
 SG_ AutoCoolStCstAvlFlg5 : 32|1@0+ (1,0) [0|1] "" CSM,RadioLow
 SG_ AutoCoolStCstAvlFlg4 : 33|1@0+ (1,0) [0|1] "" CSM,RadioLow
 SG_ AutoCoolStCstAvlFlg3 : 34|1@0+ (1,0) [0|1] "" CSM,RadioLow
 SG_ AutoCoolStCstAvlFlg2 : 35|1@0+ (1,0) [0|1] "" CSM,RadioLow
 SG_ AutoCoolStCstAvlFlg1 : 36|1@0+ (1,0) [0|1] "" CSM,RadioLow
 SG_ AutoAirDstCstAvlFlg7 : 37|1@0+ (1,0) [0|1] "" CSM,RadioLow,TCP
 SG_ AutoAirDstCstAvlFlg6 : 38|1@0+ (1,0) [0|1] "" CSM,RadioLow,TCP
 SG_ AutoAirDstCstAvlFlg5 : 39|1@0+ (1,0) [0|1] "" CSM,RadioLow,TCP
 SG_ AutoDfgCstAvlFlg6 : 40|1@0+ (1,0) [0|1] "" CSM,RadioLow
 SG_ AutoDfgCstAvlFlg5 : 41|1@0+ (1,0) [0|1] "" CSM,RadioLow
 SG_ AutoDfgCstAvlFlg4 : 42|1@0+ (1,0) [0|1] "" CSM,RadioLow
 SG_ AutoDfgCstAvlFlg3 : 43|1@0+ (1,0) [0|1] "" CSM,RadioLow
 SG_ AutoDfgCstAvlFlg2 : 44|1@0+ (1,0) [0|1] "" CSM,RadioLow
 SG_ AutoDfgCstAvlFlg1 : 45|1@0+ (1,0) [0|1] "" CSM,RadioLow
 SG_ AutoCoolStCstAvlFlg7 : 46|1@0+ (1,0) [0|1] "" CSM,RadioLow
 SG_ AutoCoolStCstAvlFlg6 : 47|1@0+ (1,0) [0|1] "" CSM,RadioLow
 SG_ AutoFanCstAvlFlg7 : 48|1@0+ (1,0) [0|1] "" CSM,RadioLow
 SG_ AutoFanCstAvlFlg6 : 49|1@0+ (1,0) [0|1] "" CSM,RadioLow
 SG_ AutoFanCstAvlFlg5 : 50|1@0+ (1,0) [0|1] "" CSM,RadioLow
 SG_ AutoFanCstAvlFlg4 : 51|1@0+ (1,0) [0|1] "" CSM,RadioLow
 SG_ AutoFanCstAvlFlg3 : 52|1@0+ (1,0) [0|1] "" CSM,RadioLow
 SG_ AutoFanCstAvlFlg2 : 53|1@0+ (1,0) [0|1] "" CSM,RadioLow
 SG_ AutoFanCstAvlFlg1 : 54|1@0+ (1,0) [0|1] "" CSM,RadioLow
 SG_ AutoDfgCstAvlFlg7 : 55|1@0+ (1,0) [0|1] "" CSM,RadioLow
 SG_ AutoHtdStCstAvlFlg7 : 57|1@0+ (1,0) [0|1] "" CSM,RadioLow
 SG_ AutoHtdStCstAvlFlg6 : 58|1@0+ (1,0) [0|1] "" CSM,RadioLow
 SG_ AutoHtdStCstAvlFlg5 : 59|1@0+ (1,0) [0|1] "" CSM,RadioLow
 SG_ AutoHtdStCstAvlFlg4 : 60|1@0+ (1,0) [0|1] "" CSM,RadioLow
 SG_ AutoHtdStCstAvlFlg3 : 61|1@0+ (1,0) [0|1] "" CSM,RadioLow
 SG_ AutoHtdStCstAvlFlg2 : 62|1@0+ (1,0) [0|1] "" CSM,RadioLow
 SG_ AutoHtdStCstAvlFlg1 : 63|1@0+ (1,0) [0|1] "" CSM,RadioLow

BO_ 1176 GWCGM_57_PDU: 8 CGM
 SG_ HtrCoreInltClntTmpCalc : 22|8@0+ (1,-40) [-40|215] "deg C" CSM,TCP
 SG_ AutoRrWpCstAvlFlg7 : 24|1@0+ (1,0) [0|1] "" CSM,RadioLow
 SG_ AutoRrWpCstAvlFlg6 : 25|1@0+ (1,0) [0|1] "" CSM,RadioLow
 SG_ AutoRrWpCstAvlFlg5 : 26|1@0+ (1,0) [0|1] "" CSM,RadioLow
 SG_ AutoRrWpCstAvlFlg4 : 27|1@0+ (1,0) [0|1] "" CSM,RadioLow
 SG_ AutoRrWpCstAvlFlg3 : 28|1@0+ (1,0) [0|1] "" CSM,RadioLow
 SG_ AutoRrWpCstAvlFlg2 : 29|1@0+ (1,0) [0|1] "" CSM,RadioLow
 SG_ AutoRrWpCstAvlFlg1 : 30|1@0+ (1,0) [0|1] "" CSM,RadioLow
 SG_ ExtLghtCstAvlFlg1 : 32|1@0+ (1,0) [0|1] "" CSM,RadioLow
 SG_ DaytimeTlLghtsCstAvlFlg7 : 33|1@0+ (1,0) [0|1] "" CSM,RadioLow
 SG_ DaytimeTlLghtsCstAvlFlg6 : 34|1@0+ (1,0) [0|1] "" CSM,RadioLow
 SG_ DaytimeTlLghtsCstAvlFlg5 : 35|1@0+ (1,0) [0|1] "" CSM,RadioLow
 SG_ DaytimeTlLghtsCstAvlFlg4 : 36|1@0+ (1,0) [0|1] "" CSM,RadioLow
 SG_ DaytimeTlLghtsCstAvlFlg3 : 37|1@0+ (1,0) [0|1] "" CSM,RadioLow
 SG_ DaytimeTlLghtsCstAvlFlg2 : 38|1@0+ (1,0) [0|1] "" CSM,RadioLow
 SG_ DaytimeTlLghtsCstAvlFlg1 : 39|1@0+ (1,0) [0|1] "" CSM,RadioLow
 SG_ HFRCCstAvlFlg2 : 40|1@0+ (1,0) [0|1] "" CSM,RadioLow
 SG_ HFRCCstAvlFlg1 : 41|1@0+ (1,0) [0|1] "" CSM,RadioLow
 SG_ ExtLghtCstAvlFlg7 : 42|1@0+ (1,0) [0|1] "" CSM,RadioLow
 SG_ ExtLghtCstAvlFlg6 : 43|1@0+ (1,0) [0|1] "" CSM,RadioLow
 SG_ ExtLghtCstAvlFlg5 : 44|1@0+ (1,0) [0|1] "" CSM,RadioLow
 SG_ ExtLghtCstAvlFlg4 : 45|1@0+ (1,0) [0|1] "" CSM,RadioLow
 SG_ ExtLghtCstAvlFlg3 : 46|1@0+ (1,0) [0|1] "" CSM,RadioLow
 SG_ ExtLghtCstAvlFlg2 : 47|1@0+ (1,0) [0|1] "" CSM,RadioLow
 SG_ HFRCCstAvlFlg7 : 51|1@0+ (1,0) [0|1] "" CSM,RadioLow
 SG_ HFRCCstAvlFlg6 : 52|1@0+ (1,0) [0|1] "" CSM,RadioLow
 SG_ HFRCCstAvlFlg5 : 53|1@0+ (1,0) [0|1] "" CSM,RadioLow
 SG_ HFRCCstAvlFlg4 : 54|1@0+ (1,0) [0|1] "" CSM,RadioLow
 SG_ HFRCCstAvlFlg3 : 55|1@0+ (1,0) [0|1] "" CSM,RadioLow

BO_ 1177 GWCGM_58_PDU: 8 CGM
 SG_ HmdtySnsrGlssTemp : 7|10@0+ (0.146,-50) [-50|99.358] "deg C" CSM
 SG_ HmdtySnsrTemp : 13|10@0+ (0.146,-50) [-50|99.358] "deg C" CSM
 SG_ HmdtySnsrRltvHmdty : 19|8@0+ (0.392,0) [0|99.96] "%" CSM
 SG_ IonzrCtrlCstAvlFlg4 : 24|1@0+ (1,0) [0|1] "" CSM,RadioLow
 SG_ IonzrCtrlCstAvlFlg3 : 25|1@0+ (1,0) [0|1] "" CSM,RadioLow
 SG_ IonzrCtrlCstAvlFlg2 : 26|1@0+ (1,0) [0|1] "" CSM,RadioLow
 SG_ IonzrCtrlCstAvlFlg1 : 27|1@0+ (1,0) [0|1] "" CSM,RadioLow
 SG_ LDCLCstAvlFlg5 : 32|1@0+ (1,0) [0|1] "" CSM,RadioLow
 SG_ LDCLCstAvlFlg4 : 33|1@0+ (1,0) [0|1] "" CSM,RadioLow
 SG_ LDCLCstAvlFlg3 : 34|1@0+ (1,0) [0|1] "" CSM,RadioLow
 SG_ LDCLCstAvlFlg2 : 35|1@0+ (1,0) [0|1] "" CSM,RadioLow
 SG_ LDCLCstAvlFlg1 : 36|1@0+ (1,0) [0|1] "" CSM,RadioLow
 SG_ IonzrCtrlCstAvlFlg7 : 37|1@0+ (1,0) [0|1] "" CSM,RadioLow
 SG_ IonzrCtrlCstAvlFlg6 : 38|1@0+ (1,0) [0|1] "" CSM,RadioLow
 SG_ IonzrCtrlCstAvlFlg5 : 39|1@0+ (1,0) [0|1] "" CSM,RadioLow
 SG_ OpDrAtLOCstAvlFlg6 : 40|1@0+ (1,0) [0|1] "" CSM,RadioLow
 SG_ OpDrAtLOCstAvlFlg5 : 41|1@0+ (1,0) [0|1] "" CSM,RadioLow
 SG_ OpDrAtLOCstAvlFlg4 : 42|1@0+ (1,0) [0|1] "" CSM,RadioLow
 SG_ OpDrAtLOCstAvlFlg3 : 43|1@0+ (1,0) [0|1] "" CSM,RadioLow
 SG_ OpDrAtLOCstAvlFlg2 : 44|1@0+ (1,0) [0|1] "" CSM,RadioLow
 SG_ OpDrAtLOCstAvlFlg1 : 45|1@0+ (1,0) [0|1] "" CSM,RadioLow
 SG_ LDCLCstAvlFlg7 : 46|1@0+ (1,0) [0|1] "" CSM,RadioLow
 SG_ LDCLCstAvlFlg6 : 47|1@0+ (1,0) [0|1] "" CSM,RadioLow
 SG_ PlltnCtrlCstAvlFlg7 : 48|1@0+ (1,0) [0|1] "" CSM,RadioLow
 SG_ PlltnCtrlCstAvlFlg6 : 49|1@0+ (1,0) [0|1] "" CSM,RadioLow
 SG_ PlltnCtrlCstAvlFlg5 : 50|1@0+ (1,0) [0|1] "" CSM,RadioLow
 SG_ PlltnCtrlCstAvlFlg4 : 51|1@0+ (1,0) [0|1] "" CSM,RadioLow
 SG_ PlltnCtrlCstAvlFlg3 : 52|1@0+ (1,0) [0|1] "" CSM,RadioLow
 SG_ PlltnCtrlCstAvlFlg2 : 53|1@0+ (1,0) [0|1] "" CSM,RadioLow
 SG_ PlltnCtrlCstAvlFlg1 : 54|1@0+ (1,0) [0|1] "" CSM,RadioLow
 SG_ OpDrAtLOCstAvlFlg7 : 55|1@0+ (1,0) [0|1] "" CSM,RadioLow
 SG_ PsvUnlckCstAvlFlg7 : 57|1@0+ (1,0) [0|1] "" CSM,RadioLow
 SG_ PsvUnlckCstAvlFlg6 : 58|1@0+ (1,0) [0|1] "" CSM,RadioLow
 SG_ PsvUnlckCstAvlFlg5 : 59|1@0+ (1,0) [0|1] "" CSM,RadioLow
 SG_ PsvUnlckCstAvlFlg4 : 60|1@0+ (1,0) [0|1] "" CSM,RadioLow
 SG_ PsvUnlckCstAvlFlg3 : 61|1@0+ (1,0) [0|1] "" CSM,RadioLow
 SG_ PsvUnlckCstAvlFlg2 : 62|1@0+ (1,0) [0|1] "" CSM,RadioLow
 SG_ PsvUnlckCstAvlFlg1 : 63|1@0+ (1,0) [0|1] "" CSM,RadioLow

BO_ 1178 GWCGM_59_PDU: 8 CGM
 SG_ RlkRtUlkDrCstAvlFlg1 : 0|1@0+ (1,0) [0|1] "" CSM,RadioLow
 SG_ RemInVehRmndrCstAvlFlg7 : 1|1@0+ (1,0) [0|1] "" CSM,RadioLow
 SG_ RemInVehRmndrCstAvlFlg6 : 2|1@0+ (1,0) [0|1] "" CSM,RadioLow
 SG_ RemInVehRmndrCstAvlFlg5 : 3|1@0+ (1,0) [0|1] "" CSM,RadioLow
 SG_ RemInVehRmndrCstAvlFlg4 : 4|1@0+ (1,0) [0|1] "" CSM,RadioLow
 SG_ RemInVehRmndrCstAvlFlg3 : 5|1@0+ (1,0) [0|1] "" CSM,RadioLow
 SG_ RemInVehRmndrCstAvlFlg2 : 6|1@0+ (1,0) [0|1] "" CSM,RadioLow
 SG_ RemInVehRmndrCstAvlFlg1 : 7|1@0+ (1,0) [0|1] "" CSM,RadioLow
 SG_ RmtSnrfOpCstAvlFlg2 : 8|1@0+ (1,0) [0|1] "" CSM,RadioLow
 SG_ RmtSnrfOpCstAvlFlg1 : 9|1@0+ (1,0) [0|1] "" CSM,RadioLow
 SG_ RlkRtUlkDrCstAvlFlg7 : 10|1@0+ (1,0) [0|1] "" CSM,RadioLow
 SG_ RlkRtUlkDrCstAvlFlg6 : 11|1@0+ (1,0) [0|1] "" CSM,RadioLow
 SG_ RlkRtUlkDrCstAvlFlg5 : 12|1@0+ (1,0) [0|1] "" CSM,RadioLow
 SG_ RlkRtUlkDrCstAvlFlg4 : 13|1@0+ (1,0) [0|1] "" CSM,RadioLow
 SG_ RlkRtUlkDrCstAvlFlg3 : 14|1@0+ (1,0) [0|1] "" CSM,RadioLow
 SG_ RlkRtUlkDrCstAvlFlg2 : 15|1@0+ (1,0) [0|1] "" CSM,RadioLow
 SG_ RmtStrtCoolStCstAvlFlg3 : 16|1@0+ (1,0) [0|1] "" CSM,RadioLow
 SG_ RmtStrtCoolStCstAvlFlg2 : 17|1@0+ (1,0) [0|1] "" CSM,RadioLow
 SG_ RmtStrtCoolStCstAvlFlg1 : 18|1@0+ (1,0) [0|1] "" CSM,RadioLow
 SG_ RmtSnrfOpCstAvlFlg7 : 19|1@0+ (1,0) [0|1] "" CSM,RadioLow
 SG_ RmtSnrfOpCstAvlFlg6 : 20|1@0+ (1,0) [0|1] "" CSM,RadioLow
 SG_ RmtSnrfOpCstAvlFlg5 : 21|1@0+ (1,0) [0|1] "" CSM,RadioLow
 SG_ RmtSnrfOpCstAvlFlg4 : 22|1@0+ (1,0) [0|1] "" CSM,RadioLow
 SG_ RmtSnrfOpCstAvlFlg3 : 23|1@0+ (1,0) [0|1] "" CSM,RadioLow
 SG_ RmtStrtHtdStCstAvlFlg4 : 24|1@0+ (1,0) [0|1] "" CSM,RadioLow
 SG_ RmtStrtHtdStCstAvlFlg3 : 25|1@0+ (1,0) [0|1] "" CSM,RadioLow
 SG_ RmtStrtHtdStCstAvlFlg2 : 26|1@0+ (1,0) [0|1] "" CSM,RadioLow
 SG_ RmtStrtHtdStCstAvlFlg1 : 27|1@0+ (1,0) [0|1] "" CSM,RadioLow
 SG_ RmtStrtCoolStCstAvlFlg7 : 28|1@0+ (1,0) [0|1] "" CSM,RadioLow
 SG_ RmtStrtCoolStCstAvlFlg6 : 29|1@0+ (1,0) [0|1] "" CSM,RadioLow
 SG_ RmtStrtCoolStCstAvlFlg5 : 30|1@0+ (1,0) [0|1] "" CSM,RadioLow
 SG_ RmtStrtCoolStCstAvlFlg4 : 31|1@0+ (1,0) [0|1] "" CSM,RadioLow
 SG_ RnSnsCstAvlFlg5 : 32|1@0+ (1,0) [0|1] "" CSM,RadioLow
 SG_ RnSnsCstAvlFlg4 : 33|1@0+ (1,0) [0|1] "" CSM,RadioLow
 SG_ RnSnsCstAvlFlg3 : 34|1@0+ (1,0) [0|1] "" CSM,RadioLow
 SG_ RnSnsCstAvlFlg2 : 35|1@0+ (1,0) [0|1] "" CSM,RadioLow
 SG_ RnSnsCstAvlFlg1 : 36|1@0+ (1,0) [0|1] "" CSM,RadioLow
 SG_ RmtStrtHtdStCstAvlFlg7 : 37|1@0+ (1,0) [0|1] "" CSM,RadioLow
 SG_ RmtStrtHtdStCstAvlFlg6 : 38|1@0+ (1,0) [0|1] "" CSM,RadioLow
 SG_ RmtStrtHtdStCstAvlFlg5 : 39|1@0+ (1,0) [0|1] "" CSM,RadioLow
 SG_ RrDfgStUpCstAvlFlg6 : 40|1@0+ (1,0) [0|1] "" CSM,RadioLow
 SG_ RrDfgStUpCstAvlFlg5 : 41|1@0+ (1,0) [0|1] "" CSM,RadioLow
 SG_ RrDfgStUpCstAvlFlg4 : 42|1@0+ (1,0) [0|1] "" CSM,RadioLow
 SG_ RrDfgStUpCstAvlFlg3 : 43|1@0+ (1,0) [0|1] "" CSM,RadioLow
 SG_ RrDfgStUpCstAvlFlg2 : 44|1@0+ (1,0) [0|1] "" CSM,RadioLow
 SG_ RrDfgStUpCstAvlFlg1 : 45|1@0+ (1,0) [0|1] "" CSM,RadioLow
 SG_ RnSnsCstAvlFlg7 : 46|1@0+ (1,0) [0|1] "" CSM,RadioLow
 SG_ RnSnsCstAvlFlg6 : 47|1@0+ (1,0) [0|1] "" CSM,RadioLow
 SG_ RrStRmndrEnblDsblCstAvlFlg7 : 48|1@0+ (1,0) [0|1] "" CSM,RadioLow
 SG_ RrStRmndrEnblDsblCstAvlFlg6 : 49|1@0+ (1,0) [0|1] "" CSM,RadioLow
 SG_ RrStRmndrEnblDsblCstAvlFlg5 : 50|1@0+ (1,0) [0|1] "" CSM,RadioLow
 SG_ RrStRmndrEnblDsblCstAvlFlg4 : 51|1@0+ (1,0) [0|1] "" CSM,RadioLow
 SG_ RrStRmndrEnblDsblCstAvlFlg3 : 52|1@0+ (1,0) [0|1] "" CSM,RadioLow
 SG_ RrStRmndrEnblDsblCstAvlFlg2 : 53|1@0+ (1,0) [0|1] "" CSM,RadioLow
 SG_ RrStRmndrEnblDsblCstAvlFlg1 : 54|1@0+ (1,0) [0|1] "" CSM,RadioLow
 SG_ RrDfgStUpCstAvlFlg7 : 55|1@0+ (1,0) [0|1] "" CSM,RadioLow
 SG_ RrZnStUpCstAvlFlg7 : 57|1@0+ (1,0) [0|1] "" CSM,RadioLow
 SG_ RrZnStUpCstAvlFlg6 : 58|1@0+ (1,0) [0|1] "" CSM,RadioLow
 SG_ RrZnStUpCstAvlFlg5 : 59|1@0+ (1,0) [0|1] "" CSM,RadioLow
 SG_ RrZnStUpCstAvlFlg4 : 60|1@0+ (1,0) [0|1] "" CSM,RadioLow
 SG_ RrZnStUpCstAvlFlg3 : 61|1@0+ (1,0) [0|1] "" CSM,RadioLow
 SG_ RrZnStUpCstAvlFlg2 : 62|1@0+ (1,0) [0|1] "" CSM,RadioLow
 SG_ RrZnStUpCstAvlFlg1 : 63|1@0+ (1,0) [0|1] "" CSM,RadioLow

BO_ 1179 GWCGM_60_PDU: 8 CGM
 SG_ BatSOCStrtUp : 7|8@0+ (0.5,0) [0|127.5] "%" CSM,TCP
 SG_ RemLftVehRmndrCstAvlFlg6 : 16|1@0+ (1,0) [0|1] "" CSM,RadioLow
 SG_ RemLftVehRmndrCstAvlFlg5 : 17|1@0+ (1,0) [0|1] "" CSM,RadioLow
 SG_ RemLftVehRmndrCstAvlFlg4 : 18|1@0+ (1,0) [0|1] "" CSM,RadioLow
 SG_ RemLftVehRmndrCstAvlFlg3 : 19|1@0+ (1,0) [0|1] "" CSM,RadioLow
 SG_ RemLftVehRmndrCstAvlFlg2 : 20|1@0+ (1,0) [0|1] "" CSM,RadioLow
 SG_ RemLftVehRmndrCstAvlFlg1 : 21|1@0+ (1,0) [0|1] "" CSM,RadioLow
 SG_ RVCBatSOCOver : 23|2@0+ (1,0) [0|3] "" CSM
 SG_ RevTltMirCstAvlFlg7 : 24|1@0+ (1,0) [0|1] "" CSM,RadioLow
 SG_ RevTltMirCstAvlFlg6 : 25|1@0+ (1,0) [0|1] "" CSM,RadioLow
 SG_ RevTltMirCstAvlFlg5 : 26|1@0+ (1,0) [0|1] "" CSM,RadioLow
 SG_ RevTltMirCstAvlFlg4 : 27|1@0+ (1,0) [0|1] "" CSM,RadioLow
 SG_ RevTltMirCstAvlFlg3 : 28|1@0+ (1,0) [0|1] "" CSM,RadioLow
 SG_ RevTltMirCstAvlFlg2 : 29|1@0+ (1,0) [0|1] "" CSM,RadioLow
 SG_ RevTltMirCstAvlFlg1 : 30|1@0+ (1,0) [0|1] "" CSM,RadioLow
 SG_ RemLftVehRmndrCstAvlFlg7 : 31|1@0+ (1,0) [0|1] "" CSM,RadioLow
 SG_ RtLkFdbkCstAvlFlg1 : 32|1@0+ (1,0) [0|1] "" CSM,RadioLow
 SG_ RmtWndOpCstAvlFlg7 : 33|1@0+ (1,0) [0|1] "" CSM,RadioLow
 SG_ RmtWndOpCstAvlFlg6 : 34|1@0+ (1,0) [0|1] "" CSM,RadioLow
 SG_ RmtWndOpCstAvlFlg5 : 35|1@0+ (1,0) [0|1] "" CSM,RadioLow
 SG_ RmtWndOpCstAvlFlg4 : 36|1@0+ (1,0) [0|1] "" CSM,RadioLow
 SG_ RmtWndOpCstAvlFlg3 : 37|1@0+ (1,0) [0|1] "" CSM,RadioLow
 SG_ RmtWndOpCstAvlFlg2 : 38|1@0+ (1,0) [0|1] "" CSM,RadioLow
 SG_ RmtWndOpCstAvlFlg1 : 39|1@0+ (1,0) [0|1] "" CSM,RadioLow
 SG_ RtUlkLtFbCstAvlFlg2 : 40|1@0+ (1,0) [0|1] "" CSM,RadioLow
 SG_ RtUlkLtFbCstAvlFlg1 : 41|1@0+ (1,0) [0|1] "" CSM,RadioLow
 SG_ RtLkFdbkCstAvlFlg7 : 42|1@0+ (1,0) [0|1] "" CSM,RadioLow
 SG_ RtLkFdbkCstAvlFlg6 : 43|1@0+ (1,0) [0|1] "" CSM,RadioLow
 SG_ RtLkFdbkCstAvlFlg5 : 44|1@0+ (1,0) [0|1] "" CSM,RadioLow
 SG_ RtLkFdbkCstAvlFlg4 : 45|1@0+ (1,0) [0|1] "" CSM,RadioLow
 SG_ RtLkFdbkCstAvlFlg3 : 46|1@0+ (1,0) [0|1] "" CSM,RadioLow
 SG_ RtLkFdbkCstAvlFlg2 : 47|1@0+ (1,0) [0|1] "" CSM,RadioLow
 SG_ SelUlkCstAvlFlg3 : 48|1@0+ (1,0) [0|1] "" CSM,RadioLow
 SG_ SelUlkCstAvlFlg2 : 49|1@0+ (1,0) [0|1] "" CSM,RadioLow
 SG_ SelUlkCstAvlFlg1 : 50|1@0+ (1,0) [0|1] "" CSM,RadioLow
 SG_ RtUlkLtFbCstAvlFlg7 : 51|1@0+ (1,0) [0|1] "" CSM,RadioLow
 SG_ RtUlkLtFbCstAvlFlg6 : 52|1@0+ (1,0) [0|1] "" CSM,RadioLow
 SG_ RtUlkLtFbCstAvlFlg5 : 53|1@0+ (1,0) [0|1] "" CSM,RadioLow
 SG_ RtUlkLtFbCstAvlFlg4 : 54|1@0+ (1,0) [0|1] "" CSM,RadioLow
 SG_ RtUlkLtFbCstAvlFlg3 : 55|1@0+ (1,0) [0|1] "" CSM,RadioLow
 SG_ SelUlkCstAvlFlg7 : 60|1@0+ (1,0) [0|1] "" CSM,RadioLow
 SG_ SelUlkCstAvlFlg6 : 61|1@0+ (1,0) [0|1] "" CSM,RadioLow
 SG_ SelUlkCstAvlFlg5 : 62|1@0+ (1,0) [0|1] "" CSM,RadioLow
 SG_ SelUlkCstAvlFlg4 : 63|1@0+ (1,0) [0|1] "" CSM,RadioLow

BO_ 1180 GWCGM_61_PDU: 8 CGM
 SG_ IDCTA_ClrTyp20Avl : 0|1@0+ (1,0) [0|1] "" CSM,RadioLow
 SG_ IDCTA_ClrTyp28Avl : 1|1@0+ (1,0) [0|1] "" CSM,RadioLow
 SG_ IDCTA_ClrTyp15Avl : 2|1@0+ (1,0) [0|1] "" CSM,RadioLow
 SG_ IDCTA_ClrTyp30Avl : 3|1@0+ (1,0) [0|1] "" CSM,RadioLow
 SG_ IDCTA_ClrTyp13Avl : 4|1@0+ (1,0) [0|1] "" CSM,RadioLow
 SG_ IDCTA_ClrTyp22Avl : 5|1@0+ (1,0) [0|1] "" CSM,RadioLow
 SG_ IDCTA_ClrTyp17Avl : 6|1@0+ (1,0) [0|1] "" CSM,RadioLow
 SG_ IDCTA_OffAvl : 7|1@0+ (1,0) [0|1] "" CSM,RadioLow
 SG_ IDCTA_ClrTyp29Avl : 8|1@0+ (1,0) [0|1] "" CSM,RadioLow
 SG_ IDCTA_ClrTyp8Avl : 9|1@0+ (1,0) [0|1] "" CSM,RadioLow
 SG_ IDCTA_ClrTyp27Avl : 10|1@0+ (1,0) [0|1] "" CSM,RadioLow
 SG_ IDCTA_ClrTyp1Avl : 11|1@0+ (1,0) [0|1] "" CSM,RadioLow
 SG_ IDCTA_ClrTyp14Avl : 12|1@0+ (1,0) [0|1] "" CSM,RadioLow
 SG_ IDCTA_ClrTyp25Avl : 13|1@0+ (1,0) [0|1] "" CSM,RadioLow
 SG_ IDCTA_ClrTyp3Avl : 14|1@0+ (1,0) [0|1] "" CSM,RadioLow
 SG_ IDCTA_ClrTyp12Avl : 15|1@0+ (1,0) [0|1] "" CSM,RadioLow
 SG_ IDCTA_ClrTyp18Avl : 16|1@0+ (1,0) [0|1] "" CSM,RadioLow
 SG_ IDCTA_ClrTyp9Avl : 17|1@0+ (1,0) [0|1] "" CSM,RadioLow
 SG_ IDCTA_ClrTyp16Avl : 18|1@0+ (1,0) [0|1] "" CSM,RadioLow
 SG_ IDCTA_ClrTyp21Avl : 19|1@0+ (1,0) [0|1] "" CSM,RadioLow
 SG_ IDCTA_ClrTyp11Avl : 20|1@0+ (1,0) [0|1] "" CSM,RadioLow
 SG_ IDCTA_ClrTyp5Avl : 21|1@0+ (1,0) [0|1] "" CSM,RadioLow
 SG_ IDCTA_ClrTyp24Avl : 22|1@0+ (1,0) [0|1] "" CSM,RadioLow
 SG_ IDCTA_ClrTyp7Avl : 23|1@0+ (1,0) [0|1] "" CSM,RadioLow
 SG_ IDATA_AnmTyp10Avl : 24|1@0+ (1,0) [0|1] "" CSM,RadioLow
 SG_ IDCTA_ClrTyp23Avl : 25|1@0+ (1,0) [0|1] "" CSM,RadioLow
 SG_ IDCTA_ClrTyp19Avl : 26|1@0+ (1,0) [0|1] "" CSM,RadioLow
 SG_ IDCTA_ClrTyp26Avl : 27|1@0+ (1,0) [0|1] "" CSM,RadioLow
 SG_ IDCTA_ClrTyp2Avl : 28|1@0+ (1,0) [0|1] "" CSM,RadioLow
 SG_ IDCTA_ClrTyp6Avl : 29|1@0+ (1,0) [0|1] "" CSM,RadioLow
 SG_ IDCTA_ClrTyp4Avl : 30|1@0+ (1,0) [0|1] "" CSM,RadioLow
 SG_ IDCTA_ClrTyp10Avl : 31|1@0+ (1,0) [0|1] "" CSM,RadioLow
 SG_ IDATA_AnmTyp7Avl : 32|1@0+ (1,0) [0|1] "" CSM,RadioLow
 SG_ IDATA_AnmTyp9Avl : 33|1@0+ (1,0) [0|1] "" CSM,RadioLow
 SG_ IDATA_AnmTyp3Avl : 34|1@0+ (1,0) [0|1] "" CSM,RadioLow
 SG_ IDATA_AnmTyp14Avl : 35|1@0+ (1,0) [0|1] "" CSM,RadioLow
 SG_ IDATA_AnmTyp12Avl : 36|1@0+ (1,0) [0|1] "" CSM,RadioLow
 SG_ IDATA_OffAvl : 37|1@0+ (1,0) [0|1] "" CSM,RadioLow
 SG_ IDATA_AnmTyp8Avl : 38|1@0+ (1,0) [0|1] "" CSM,RadioLow
 SG_ IDATA_AnmTyp13Avl : 39|1@0+ (1,0) [0|1] "" CSM,RadioLow
 SG_ WlkAwyLckCstAvlFlg2 : 40|1@0+ (1,0) [0|1] "" CSM,RadioLow
 SG_ WlkAwyLckCstAvlFlg1 : 41|1@0+ (1,0) [0|1] "" CSM,RadioLow
 SG_ IDATA_AnmTyp2Avl : 42|1@0+ (1,0) [0|1] "" CSM,RadioLow
 SG_ IDATA_AnmTyp4Avl : 43|1@0+ (1,0) [0|1] "" CSM,RadioLow
 SG_ IDATA_AnmTyp5Avl : 44|1@0+ (1,0) [0|1] "" CSM,RadioLow
 SG_ IDATA_AnmTyp1Avl : 45|1@0+ (1,0) [0|1] "" CSM,RadioLow
 SG_ IDATA_AnmTyp6Avl : 46|1@0+ (1,0) [0|1] "" CSM,RadioLow
 SG_ IDATA_AnmTyp11Avl : 47|1@0+ (1,0) [0|1] "" CSM,RadioLow
 SG_ WlkAwyLckCstAvlFlg7 : 51|1@0+ (1,0) [0|1] "" CSM,RadioLow
 SG_ WlkAwyLckCstAvlFlg6 : 52|1@0+ (1,0) [0|1] "" CSM,RadioLow
 SG_ WlkAwyLckCstAvlFlg5 : 53|1@0+ (1,0) [0|1] "" CSM,RadioLow
 SG_ WlkAwyLckCstAvlFlg4 : 54|1@0+ (1,0) [0|1] "" CSM,RadioLow
 SG_ WlkAwyLckCstAvlFlg3 : 55|1@0+ (1,0) [0|1] "" CSM,RadioLow

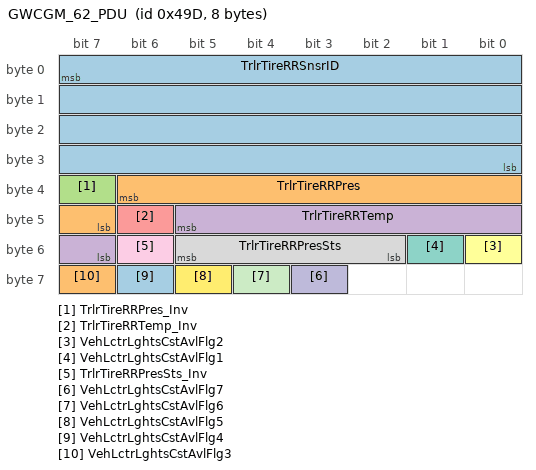
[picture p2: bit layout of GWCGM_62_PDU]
BO_ 1181 GWCGM_62_PDU: 8 CGM
 SG_ TrlrTireRRSnsrID : 7|32@0+ (1,0) [0|4.29497e+009] "" CSM
 SG_ TrlrTireRRPres : 38|8@0+ (4,0) [0|1020] "kPaG" CSM,VKM
 SG_ TrlrTireRRPres_Inv : 39|1@0+ (1,0) [0|1] "" CSM,VKM
 SG_ TrlrTireRRTemp : 45|7@0+ (1,-20) [-20|107] "degC" CSM
 SG_ TrlrTireRRTemp_Inv : 46|1@0+ (1,0) [0|1] "" CSM
 SG_ VehLctrLghtsCstAvlFlg2 : 48|1@0+ (1,0) [0|1] "" CSM,RadioLow
 SG_ VehLctrLghtsCstAvlFlg1 : 49|1@0+ (1,0) [0|1] "" CSM,RadioLow
 SG_ TrlrTireRRPresSts : 53|4@0+ (1,0) [0|8] "" CSM,VKM
 SG_ TrlrTireRRPresSts_Inv : 54|1@0+ (1,0) [0|1] "" CSM,VKM
 SG_ VehLctrLghtsCstAvlFlg7 : 59|1@0+ (1,0) [0|1] "" CSM,RadioLow
 SG_ VehLctrLghtsCstAvlFlg6 : 60|1@0+ (1,0) [0|1] "" CSM,RadioLow
 SG_ VehLctrLghtsCstAvlFlg5 : 61|1@0+ (1,0) [0|1] "" CSM,RadioLow
 SG_ VehLctrLghtsCstAvlFlg4 : 62|1@0+ (1,0) [0|1] "" CSM,RadioLow
 SG_ VehLctrLghtsCstAvlFlg3 : 63|1@0+ (1,0) [0|1] "" CSM,RadioLow

BA_DEF_ SG_  "SignalType" STRING ;
BA_DEF_ SG_  "SignalLongName" STRING ;
BA_DEF_ BO_  "GenMsgCycleTime" INT 0 10000;
BA_DEF_ BO_  "GenMsgSendType" ENUM "cyclicX","spontanX","cyclicIfActiveX","spontanWithDelay","cyclicAndSpontanX","cyclicAndSpontanWithDelay","spontanWithRepetition","cyclicIfActiveAndSpontanWD";
BA_DEF_DEF_  "SignalType" "";
BA_DEF_DEF_  "SignalLongName" "";
BA_DEF_DEF_  "GenMsgCycleTime" 0;
BA_DEF_DEF_  "GenMsgSendType" "cyclicX";
BA_ "GenMsgCycleTime" BO_ 1208 1000;
BA_ "GenMsgCycleTime" BO_ 1209 1000;
BA_ "GenMsgCycleTime" BO_ 1210 1000;
BA_ "GenMsgCycleTime" BO_ 1236 1000;
BA_ "GenMsgCycleTime" BO_ 1237 1000;
BA_ "GenMsgCycleTime" BO_ 1238 1000;
BA_ "GenMsgCycleTime" BO_ 1239 1000;
BA_ "GenMsgCycleTime" BO_ 1211 1000;
BA_ "GenMsgCycleTime" BO_ 1212 1000;
BA_ "GenMsgCycleTime" BO_ 1213 1000;
BA_ "GenMsgCycleTime" BO_ 1214 1000;
BA_ "GenMsgCycleTime" BO_ 1215 1000;
BA_ "GenMsgCycleTime" BO_ 1216 1000;
BA_ "GenMsgCycleTime" BO_ 1217 1000;
BA_ "GenMsgCycleTime" BO_ 1218 1000;
BA_ "GenMsgCycleTime" BO_ 1175 1000;
BA_ "GenMsgCycleTime" BO_ 1176 1000;
BA_ "GenMsgCycleTime" BO_ 1177 1000;
BA_ "GenMsgCycleTime" BO_ 1178 1000;
BA_ "GenMsgCycleTime" BO_ 1179 1000;
BA_ "GenMsgCycleTime" BO_ 1180 1000;
BA_ "GenMsgCycleTime" BO_ 1181 1000;
BA_ "SignalType" SG_ 1208 TkModeDrvlineVisDispVal "ENM";
BA_ "SignalLongName" SG_ 1208 TkModeDrvlineVisDispVal "Track Mode Driveline Visualization Display Value";
BA_ "SignalType" SG_ 1208 TkModeBrkPedVisDispVal "ENM";
BA_ "SignalLongName" SG_ 1208 TkModeBrkPedVisDispVal "Track Mode Brake Pedal Visualization Display Value";
BA_ "SignalType" SG_ 1208 TkModeActvAeroVisDispVal "ENM";
BA_ "SignalLongName" SG_ 1208 TkModeActvAeroVisDispVal "Track Mode Active Aerodynamics Visualization Display Value";
BA_ "SignalType" SG_ 1208 TkModeRideHghtVisDispVal "ENM";
BA_ "SignalLongName" SG_ 1208 TkModeRideHghtVisDispVal "Track Mode Ride Height Visualization Display Value";
BA_ "SignalType" SG_ 1208 TkModePwrtrnVisDispVal "ENM";
BA_ "SignalLongName" SG_ 1208 TkModePwrtrnVisDispVal "Track Mode Powertrain Visualization Display Value";
BA_ "SignalType" SG_ 1208 TkModeESCVisDispVal "ENM";
BA_ "SignalLongName" SG_ 1208 TkModeESCVisDispVal "Track Mode ESC Visualization Display Value";
BA_ "SignalType" SG_ 1208 TkModeSpnsnVisDispVal "ENM";
BA_ "SignalLongName" SG_ 1208 TkModeSpnsnVisDispVal "Track Mode Suspension Visualization Display Value";
BA_ "SignalType" SG_ 1208 TkModeSndVisDispVal "ENM";
BA_ "SignalLongName" SG_ 1208 TkModeSndVisDispVal "Track Mode Sound Visualization Display Value";
BA_ "SignalType" SG_ 1208 WthrSnwModeBrkPedVisDispVal "ENM";
BA_ "SignalLongName" SG_ 1208 WthrSnwModeBrkPedVisDispVal "Weather Snow Mode Brake Pedal Visualization Display Value";
BA_ "SignalType" SG_ 1208 WthrSnwModeActvAeroVisDispVal "ENM";
BA_ "SignalLongName" SG_ 1208 WthrSnwModeActvAeroVisDispVal "Weather Snow Mode Active Aerodynamics Visualization Display Value";
BA_ "SignalType" SG_ 1208 TkModeStrgVisDispVal "ENM";
BA_ "SignalLongName" SG_ 1208 TkModeStrgVisDispVal "Track Mode Steering Visualization Display Value";
BA_ "SignalType" SG_ 1208 WthrSnwModePwrtrnVisDispVal "ENM";
BA_ "SignalLongName" SG_ 1208 WthrSnwModePwrtrnVisDispVal "Weather Snow Mode Powertrain Visualization Display Value";
BA_ "SignalType" SG_ 1208 WthrSnwModeESCVisDispVal "ENM";
BA_ "SignalLongName" SG_ 1208 WthrSnwModeESCVisDispVal "Weather Snow Mode ESC Visualization Display Value";
BA_ "SignalType" SG_ 1208 WthrSnwModeDrvlineVisDispVal "ENM";
BA_ "SignalLongName" SG_ 1208 WthrSnwModeDrvlineVisDispVal "Weather Snow Mode Driveline Visualization Display Value";
BA_ "SignalType" SG_ 1208 WthrSnwModeSndVisDispVal "ENM";
BA_ "SignalLongName" SG_ 1208 WthrSnwModeSndVisDispVal "Weather Snow Mode Sound Visualization Display Value";
BA_ "SignalType" SG_ 1208 WthrSnwModeRideHghtVisDispVal "ENM";
BA_ "SignalLongName" SG_ 1208 WthrSnwModeRideHghtVisDispVal "Weather Snow Mode Ride Height Visualization Display Value";
BA_ "SignalType" SG_ 1208 TrcStbScrConfig "ENM";
BA_ "SignalLongName" SG_ 1208 TrcStbScrConfig "Traction and Stability Screen Configuration";
BA_ "SignalType" SG_ 1208 WthrSnwModeStrgVisDispVal "ENM";
BA_ "SignalLongName" SG_ 1208 WthrSnwModeStrgVisDispVal "Weather Snow Mode Steering Visualization Display Value";
BA_ "SignalType" SG_ 1208 WthrSnwModeSpnsnVisDispVal "ENM";
BA_ "SignalLongName" SG_ 1208 WthrSnwModeSpnsnVisDispVal "Weather Snow Mode Suspension Visualization Display Value";
BA_ "SignalType" SG_ 1208 TrcCntrlSysTmpDisReqIO "ENM";
BA_ "SignalLongName" SG_ 1208 TrcCntrlSysTmpDisReqIO "Traction Control System Temporary Disable Request Indication On";
BA_ "SignalType" SG_ 1208 TrcCntrlOnIO "ENM";
BA_ "SignalLongName" SG_ 1208 TrcCntrlOnIO "Traction Control On Indication On";
BA_ "SignalType" SG_ 1208 TrcCntrlOffIO "ENM";
BA_ "SignalLongName" SG_ 1208 TrcCntrlOffIO "Traction Control Off Indication On";
BA_ "SignalType" SG_ 1208 TCSCustAv "ENM";
BA_ "SignalLongName" SG_ 1208 TCSCustAv "Traction Control System Customization Available";
BA_ "SignalType" SG_ 1208 TCSCurStat "ENM";
BA_ "SignalLongName" SG_ 1208 TCSCurStat "Traction Control System Current State";
BA_ "SignalType" SG_ 1209 SprtModeBrkPedVisDispVal "ENM";
BA_ "SignalLongName" SG_ 1209 SprtModeBrkPedVisDispVal "Sport Mode Brake Pedal Visualization Display Value";
BA_ "SignalType" SG_ 1209 SprtModeActvAeroVisDispVal "ENM";
BA_ "SignalLongName" SG_ 1209 SprtModeActvAeroVisDispVal "Sport Mode Active Aerodynamics Visualization Display Value";
BA_ "SignalType" SG_ 1209 PerfTracMgmtMode "ENM";
BA_ "SignalLongName" SG_ 1209 PerfTracMgmtMode "Performance Traction Management Mode";
BA_ "SignalType" SG_ 1209 SprtModePwrtrnVisDispVal "ENM";
BA_ "SignalLongName" SG_ 1209 SprtModePwrtrnVisDispVal "Sport Mode Powertrain Visualization Display Value";
BA_ "SignalType" SG_ 1209 SprtModeESCVisDispVal "ENM";
BA_ "SignalLongName" SG_ 1209 SprtModeESCVisDispVal "Sport Mode ESC Visualization Display Value";
BA_ "SignalType" SG_ 1209 SprtModeDrvlineVisDispVal "ENM";
BA_ "SignalLongName" SG_ 1209 SprtModeDrvlineVisDispVal "Sport Mode Driveline Visualization Display Value";
BA_ "SignalType" SG_ 1209 SprtModeSndVisDispVal "ENM";
BA_ "SignalLongName" SG_ 1209 SprtModeSndVisDispVal "Sport Mode Sound Visualization Display Value";
BA_ "SignalType" SG_ 1209 SprtModeRideHghtVisDispVal "ENM";
BA_ "SignalLongName" SG_ 1209 SprtModeRideHghtVisDispVal "Sport Mode Ride Height Visualization Display Value";
BA_ "SignalType" SG_ 1209 TireTrdTempSts "ENM";
BA_ "SignalLongName" SG_ 1209 TireTrdTempSts "Tire Tread Temperature Status";
BA_ "SignalType" SG_ 1209 SprtModeStrgVisDispVal "ENM";
BA_ "SignalLongName" SG_ 1209 SprtModeStrgVisDispVal "Sport Mode Steering Visualization Display Value";
BA_ "SignalType" SG_ 1209 SprtModeSpnsnVisDispVal "ENM";
BA_ "SignalLongName" SG_ 1209 SprtModeSpnsnVisDispVal "Sport Mode Suspension Visualization Display Value";
BA_ "SignalType" SG_ 1209 TourModeDrvlineVisDispVal "ENM";
BA_ "SignalLongName" SG_ 1209 TourModeDrvlineVisDispVal "Tour Mode Driveline Visualization Display Value";
BA_ "SignalType" SG_ 1209 TourModeBrkPedVisDispVal "ENM";
BA_ "SignalLongName" SG_ 1209 TourModeBrkPedVisDispVal "Tour Mode Brake Pedal Visualization Display Value";
BA_ "SignalType" SG_ 1209 TourModeActvAeroVisDispVal "ENM";
BA_ "SignalLongName" SG_ 1209 TourModeActvAeroVisDispVal "Tour Mode Active Aerodynamics Visualization Display Value";
BA_ "SignalType" SG_ 1209 TourModePwrtrnVisDispVal "ENM";
BA_ "SignalLongName" SG_ 1209 TourModePwrtrnVisDispVal "Tour Mode Powertrain Visualization Display Value";
BA_ "SignalType" SG_ 1209 TourModeESCVisDispVal "ENM";
BA_ "SignalLongName" SG_ 1209 TourModeESCVisDispVal "Tour Mode ESC Visualization Display Value";
BA_ "SignalType" SG_ 1209 TourModeSpnsnVisDispVal "ENM";
BA_ "SignalLongName" SG_ 1209 TourModeSpnsnVisDispVal "Tour Mode Suspension Visualization Display Value";
BA_ "SignalType" SG_ 1209 TourModeSndVisDispVal "ENM";
BA_ "SignalLongName" SG_ 1209 TourModeSndVisDispVal "Tour Mode Sound Visualization Display Value";
BA_ "SignalType" SG_ 1209 TourModeRideHghtVisDispVal "ENM";
BA_ "SignalLongName" SG_ 1209 TourModeRideHghtVisDispVal "Tour Mode Ride Height Visualization Display Value";
BA_ "SignalType" SG_ 1209 TnDrvTrCtrlOffUnvIndOn "ENM";
BA_ "SignalLongName" SG_ 1209 TnDrvTrCtrlOffUnvIndOn "Teen Driver Traction Control Off Unavailable Indication On";
BA_ "SignalType" SG_ 1209 SrBkLwBkFlDrVisMsgRqOn "ENM";
BA_ "SignalLongName" SG_ 1209 SrBkLwBkFlDrVisMsgRqOn "Service Brakes Low Brake Fluid Driver Visual Message Request On";
BA_ "SignalType" SG_ 1209 ShfToPrkBfrExtIndOn "ENM";
BA_ "SignalLongName" SG_ 1209 ShfToPrkBfrExtIndOn "Shift To Park Before Exiting Indication On";
BA_ "SignalType" SG_ 1209 TourModeStrgVisDispVal "ENM";
BA_ "SignalLongName" SG_ 1209 TourModeStrgVisDispVal "Tour Mode Steering Visualization Display Value";
BA_ "SignalLongName" SG_ 1210 BrkPadLifeFrtDistRmn "Brake Pad Life Front Distance Remaining";
BA_ "SignalLongName" SG_ 1210 BrkPadLifeRrDistRmn "Brake Pad Life Rear Distance Remaining";
BA_ "SignalType" SG_ 1210 HillDscntCtlSysSts "ENM";
BA_ "SignalLongName" SG_ 1210 HillDscntCtlSysSts "Hill Descent Control System Status";
BA_ "SignalType" SG_ 1210 EngSndPerfModeReq "ENM";
BA_ "SignalLongName" SG_ 1210 EngSndPerfModeReq "Engine Sound Performance Mode Request";
BA_ "SignalType" SG_ 1210 DrvModeVisScreenSts "ENM";
BA_ "SignalLongName" SG_ 1210 DrvModeVisScreenSts "Driving Mode Visualization Screen Status";
BA_ "SignalType" SG_ 1210 BrksOvrht "ENM";
BA_ "SignalLongName" SG_ 1210 BrksOvrht "Brakes Overheated";
BA_ "SignalType" SG_ 1210 BrkSysHillStrtAsstAvl "ENM";
BA_ "SignalLongName" SG_ 1210 BrkSysHillStrtAsstAvl "Brake System Hill Start Assist Available";
BA_ "SignalType" SG_ 1210 BrkPadLifeRrCnfrmRplcmtIndOn "ENM";
BA_ "SignalLongName" SG_ 1210 BrkPadLifeRrCnfrmRplcmtIndOn "Brake Pad Life Rear Confirm Replacement Indication On";
BA_ "SignalType" SG_ 1210 BrkPadLifeFrtCnfrmRplcmtIndOn "ENM";
BA_ "SignalLongName" SG_ 1210 BrkPadLifeFrtCnfrmRplcmtIndOn "Brake Pad Life Front Confirm Replacement Indication On";
BA_ "SignalType" SG_ 1210 BrkPadLifeRrDistWrnIndReq "ENM";
BA_ "SignalLongName" SG_ 1210 BrkPadLifeRrDistWrnIndReq "Brake Pad Life Rear Distance Warning Indication Request";
BA_ "SignalType" SG_ 1210 HillDscntCtlRdcVehSpdIndOn "ENM";
BA_ "SignalLongName" SG_ 1210 HillDscntCtlRdcVehSpdIndOn "Hill Descent Control Reduce Vehicle Speed Indication On";
BA_ "SignalType" SG_ 1210 CustmStbCtlRdctReqIndOn "ENM";
BA_ "SignalLongName" SG_ 1210 CustmStbCtlRdctReqIndOn "Custom Stability Control Reduction Request Indication On";
BA_ "SignalType" SG_ 1236 AutMirFldCstCurSetVal "ENM";
BA_ "SignalLongName" SG_ 1236 AutMirFldCstCurSetVal "AutoMirrorFoldCustomizationCurrentSettingValue";
BA_ "SignalType" SG_ 1236 AutDrvLckCstCurSetVal "ENM";
BA_ "SignalLongName" SG_ 1236 AutDrvLckCstCurSetVal "AutomaticDriveLockingCustomizationCurrentSettingValue";
BA_ "SignalType" SG_ 1236 AirQltySnsCstCrStVal "ENM";
BA_ "SignalLongName" SG_ 1236 AirQltySnsCstCrStVal "Air Quality Sensor Customization Current Setting Value";
BA_ "SignalType" SG_ 1236 AutoCoolStCstCrStVal "ENM";
BA_ "SignalLongName" SG_ 1236 AutoCoolStCstCrStVal "Automatic Cooled Seat Customization Current Setting Value";
BA_ "SignalType" SG_ 1236 AutoAirDstCstCrStVal "ENM";
BA_ "SignalLongName" SG_ 1236 AutoAirDstCstCrStVal "Automatic Air Distribution Customization Current Setting Value";
BA_ "SignalType" SG_ 1236 AutUnlckCstCurSetVal "ENM";
BA_ "SignalLongName" SG_ 1236 AutUnlckCstCurSetVal "AutomaticUnlockingCustomizationCurrentSettingValue";
BA_ "SignalType" SG_ 1236 AutoFanCstCrStVal "ENM";
BA_ "SignalLongName" SG_ 1236 AutoFanCstCrStVal "Automatic Fan Customization Current Setting Value";
BA_ "SignalType" SG_ 1236 AutoDfgCstCrStVal "ENM";
BA_ "SignalLongName" SG_ 1236 AutoDfgCstCrStVal "Automatic Defog Customization Current Setting Value";
BA_ "SignalType" SG_ 1236 DaytimeTlLghtsCstCurSetVal "ENM";
BA_ "SignalLongName" SG_ 1236 DaytimeTlLghtsCstCurSetVal "DaytimeTailLightsCustomizationCurrentSettingValue";
BA_ "SignalType" SG_ 1236 AutoRrWpCstCurSetVal "ENM";
BA_ "SignalLongName" SG_ 1236 AutoRrWpCstCurSetVal "AutoRearWipeCustomizationCurrentSettingValue";
BA_ "SignalType" SG_ 1236 AutoHtdStCstCrStVal "ENM";
BA_ "SignalLongName" SG_ 1236 AutoHtdStCstCrStVal "Automatic Heated Seat Customization Current Setting Value";
BA_ "SignalType" SG_ 1236 AutoAirDstCstStAvl "ENM";
BA_ "SignalLongName" SG_ 1236 AutoAirDstCstStAvl "Automatic Air Distribution Customization Setting Available";
BA_ "SignalType" SG_ 1236 AutUnlckCstStAvl "ENM";
BA_ "SignalLongName" SG_ 1236 AutUnlckCstStAvl "AutomaticUnlockingCustomizationSettingAvailable";
BA_ "SignalType" SG_ 1236 AutMirFldCstStAvl "ENM";
BA_ "SignalLongName" SG_ 1236 AutMirFldCstStAvl "AutoMirrorFoldCustomizationSettingAvailable";
BA_ "SignalType" SG_ 1236 AutDrvLckCstStAvl "ENM";
BA_ "SignalLongName" SG_ 1236 AutDrvLckCstStAvl "AutomaticDriveLockingCustomizationSettingAvailable";
BA_ "SignalType" SG_ 1236 AirQltySnsCstStAvl "ENM";
BA_ "SignalLongName" SG_ 1236 AirQltySnsCstStAvl "Air Quality Sensor Customization Setting Available";
BA_ "SignalType" SG_ 1236 CurbVwFtrActvReq "ENM";
BA_ "SignalLongName" SG_ 1236 CurbVwFtrActvReq "Curb View Feature Active Request";
BA_ "SignalType" SG_ 1236 DM1Unavailable "ENM";
BA_ "SignalLongName" SG_ 1236 DM1Unavailable "Drive Mode 1 Unavailable";
BA_ "SignalType" SG_ 1236 DM1Pending "ENM";
BA_ "SignalLongName" SG_ 1236 DM1Pending "Drive Mode 1 Pending";
BA_ "SignalType" SG_ 1236 CrsCntCncRq "ENM";
BA_ "SignalLongName" SG_ 1236 CrsCntCncRq "Cruise Control Cancel Request";
BA_ "SignalType" SG_ 1236 AutoRrWpCstStAvl "ENM";
BA_ "SignalLongName" SG_ 1236 AutoRrWpCstStAvl "AutoRearWipeCustomizationSettingAvailable";
BA_ "SignalType" SG_ 1236 AutoHtdStCstStAvl "ENM";
BA_ "SignalLongName" SG_ 1236 AutoHtdStCstStAvl "Automatic Heated Seat Customization Setting Available";
BA_ "SignalType" SG_ 1236 AutoFanCstStAvl "ENM";
BA_ "SignalLongName" SG_ 1236 AutoFanCstStAvl "Automatic Fan Customization Setting Available";
BA_ "SignalType" SG_ 1236 AutoDfgCstStAvl "ENM";
BA_ "SignalLongName" SG_ 1236 AutoDfgCstStAvl "Automatic Defog Customization Setting Available";
BA_ "SignalType" SG_ 1236 AutoCoolStCstStAvl "ENM";
BA_ "SignalLongName" SG_ 1236 AutoCoolStCstStAvl "Automatic Cooled Seat Customization Setting Available";
BA_ "SignalType" SG_ 1236 DM5Unavailable "ENM";
BA_ "SignalLongName" SG_ 1236 DM5Unavailable "Drive Mode 5 Unavailable";
BA_ "SignalType" SG_ 1236 DM5Pending "ENM";
BA_ "SignalLongName" SG_ 1236 DM5Pending "Drive Mode 5 Pending";
BA_ "SignalType" SG_ 1236 DM4Unavailable "ENM";
BA_ "SignalLongName" SG_ 1236 DM4Unavailable "Drive Mode 4 Unavailable";
BA_ "SignalType" SG_ 1236 DM4Pending "ENM";
BA_ "SignalLongName" SG_ 1236 DM4Pending "Drive Mode 4 Pending";
BA_ "SignalType" SG_ 1236 DM3Unavailable "ENM";
BA_ "SignalLongName" SG_ 1236 DM3Unavailable "Drive Mode 3 Unavailable";
BA_ "SignalType" SG_ 1236 DM3Pending "ENM";
BA_ "SignalLongName" SG_ 1236 DM3Pending "Drive Mode 3 Pending";
BA_ "SignalType" SG_ 1236 DM2Unavailable "ENM";
BA_ "SignalLongName" SG_ 1236 DM2Unavailable "Drive Mode 2 Unavailable";
BA_ "SignalType" SG_ 1236 DM2Pending "ENM";
BA_ "SignalLongName" SG_ 1236 DM2Pending "Drive Mode 2 Pending";
BA_ "SignalType" SG_ 1236 DaytimeTlLghtsCstStAvl "ENM";
BA_ "SignalLongName" SG_ 1236 DaytimeTlLghtsCstStAvl "DaytimeTailLightsCustomizationSettingAvailable";
BA_ "SignalType" SG_ 1236 DM8Unavailable "ENM";
BA_ "SignalLongName" SG_ 1236 DM8Unavailable "Drive Mode 8 Unavailable";
BA_ "SignalType" SG_ 1236 DM8Pending "ENM";
BA_ "SignalLongName" SG_ 1236 DM8Pending "Drive Mode 8 Pending";
BA_ "SignalType" SG_ 1236 DM7Unavailable "ENM";
BA_ "SignalLongName" SG_ 1236 DM7Unavailable "Drive Mode 7 Unavailable";
BA_ "SignalType" SG_ 1236 DM7Pending "ENM";
BA_ "SignalLongName" SG_ 1236 DM7Pending "Drive Mode 7 Pending";
BA_ "SignalType" SG_ 1236 DM6Unavailable "ENM";
BA_ "SignalLongName" SG_ 1236 DM6Unavailable "Drive Mode 6 Unavailable";
BA_ "SignalType" SG_ 1236 DM6Pending "ENM";
BA_ "SignalLongName" SG_ 1236 DM6Pending "Drive Mode 6 Pending";
BA_ "SignalType" SG_ 1237 IntDimSeldAnmTypStVal "ENM";
BA_ "SignalLongName" SG_ 1237 IntDimSeldAnmTypStVal "Interior Dimming Selected Animation Type Setting Value";
BA_ "SignalType" SG_ 1237 IntDimSeldClrTypStVal "ENM";
BA_ "SignalLongName" SG_ 1237 IntDimSeldClrTypStVal "Interior Dimming Selected Color Type Setting Value";
BA_ "SignalType" SG_ 1237 IonzrCtrlCstCrStVal "ENM";
BA_ "SignalLongName" SG_ 1237 IonzrCtrlCstCrStVal "Ionizer Control Customization Current Setting Value";
BA_ "SignalType" SG_ 1237 HFRCCstCurSetVal "ENM";
BA_ "SignalLongName" SG_ 1237 HFRCCstCurSetVal "HandsFreeRearClosureCustomizationCurrentSettingValue";
BA_ "SignalType" SG_ 1237 ExtLghtCstCurSetVal "ENM";
BA_ "SignalLongName" SG_ 1237 ExtLghtCstCurSetVal "Exit Lighting CustomizationCurrentSettingValue";
BA_ "SignalType" SG_ 1237 OpDrAtLOCstCurSetVal "ENM";
BA_ "SignalLongName" SG_ 1237 OpDrAtLOCstCurSetVal "OpenDoorAntiLockOutCustomizationCurrentSettingValue";
BA_ "SignalType" SG_ 1237 LDCLCstCurSetVal "ENM";
BA_ "SignalLongName" SG_ 1237 LDCLCstCurSetVal "LastDoorClosedLockingCustomizationCurrentSettingValue";
BA_ "SignalType" SG_ 1237 RlkRtUlkDrCstCrSetVal "ENM";
BA_ "SignalLongName" SG_ 1237 RlkRtUlkDrCstCrSetVal "RelockRemoteUnlockedDoorCustomizationCurrentSettingValue";
BA_ "SignalType" SG_ 1237 PsvUnlckCstCurSetVal "ENM";
BA_ "SignalLongName" SG_ 1237 PsvUnlckCstCurSetVal "PassiveUnlockingCustomizationCurrentSettingValue";
BA_ "SignalType" SG_ 1237 PlltnCtrlCstCrStVal "ENM";
BA_ "SignalLongName" SG_ 1237 PlltnCtrlCstCrStVal "Pollution Control Customization Current Setting Value";
BA_ "SignalType" SG_ 1237 RrStRmndrEnblDsblCstCurrSetVal "ENM";
BA_ "SignalLongName" SG_ 1237 RrStRmndrEnblDsblCstCurrSetVal "Rear Seat Reminder Enable Disable Customization Current Setting Value";
BA_ "SignalType" SG_ 1237 RrDfgStUpCstCrStVal "ENM";
BA_ "SignalLongName" SG_ 1237 RrDfgStUpCstCrStVal "Rear Defog Startup Customization Current Setting Value";
BA_ "SignalType" SG_ 1237 RnSnsCstCurSetVal "ENM";
BA_ "SignalLongName" SG_ 1237 RnSnsCstCurSetVal "RainSenseCustomizationCurrentSettingValue";
BA_ "SignalType" SG_ 1237 ExtLghtCstStAvl "ENM";
BA_ "SignalLongName" SG_ 1237 ExtLghtCstStAvl "Exit Lighting CustomizationSettingAvailable";
BA_ "SignalType" SG_ 1237 RrAirHandlingDrActrPwrReq "ENM";
BA_ "SignalLongName" SG_ 1237 RrAirHandlingDrActrPwrReq "Rear Air Handling Door Actuator Power Request";
BA_ "SignalType" SG_ 1237 RrZnStUpCstCrStVal "ENM";
BA_ "SignalLongName" SG_ 1237 RrZnStUpCstCrStVal "Rear Zone Startup Customization Current Setting Value";
BA_ "SignalType" SG_ 1237 RnSnsCstStAvl "ENM";
BA_ "SignalLongName" SG_ 1237 RnSnsCstStAvl "RainSenseCustomizationSettingAvailable";
BA_ "SignalType" SG_ 1237 RlkRtUlkDrCstStAvl "ENM";
BA_ "SignalLongName" SG_ 1237 RlkRtUlkDrCstStAvl "RelockRemoteUnlockedDoorCustomizationSettingAvailable";
BA_ "SignalType" SG_ 1237 PsvUnlckCstStAvl "ENM";
BA_ "SignalLongName" SG_ 1237 PsvUnlckCstStAvl "PassiveUnlockingCustomizationSettingAvailable";
BA_ "SignalType" SG_ 1237 PlltnCtrlCstStAvl "ENM";
BA_ "SignalLongName" SG_ 1237 PlltnCtrlCstStAvl "Pollution Control Customization Setting Available";
BA_ "SignalType" SG_ 1237 OpDrAtLOCstStAvl "ENM";
BA_ "SignalLongName" SG_ 1237 OpDrAtLOCstStAvl "OpenDoorAntiLockOutCustomizationSettingAvailable";
BA_ "SignalType" SG_ 1237 LDCLCstStAvl "ENM";
BA_ "SignalLongName" SG_ 1237 LDCLCstStAvl "LastDoorClosedLockingCustomizationSettingAvailable";
BA_ "SignalType" SG_ 1237 IonzrCtrlCstStAvl "ENM";
BA_ "SignalLongName" SG_ 1237 IonzrCtrlCstStAvl "Ionizer Control Customization Setting Available";
BA_ "SignalType" SG_ 1237 HFRCCstStAvl "ENM";
BA_ "SignalLongName" SG_ 1237 HFRCCstStAvl "HandsFreeRearClosureCustomizationSettingAvailable";
BA_ "SignalType" SG_ 1237 RrZnStUpCstStAvl "ENM";
BA_ "SignalLongName" SG_ 1237 RrZnStUpCstStAvl "Rear Zone Startup Customization Setting Available";
BA_ "SignalType" SG_ 1237 RrStRmndrEnblDsblCstSetAval "ENM";
BA_ "SignalLongName" SG_ 1237 RrStRmndrEnblDsblCstSetAval "Rear Seat Reminder Enable Disable Customization Setting Available";
BA_ "SignalType" SG_ 1237 RrDfgStUpCstStAvl "ENM";
BA_ "SignalLongName" SG_ 1237 RrDfgStUpCstStAvl "Rear Defog Startup Customization Setting Available";
BA_ "SignalLongName" SG_ 1238 RmtReFlshElecPwrRdnes "Remote ReFlash Electic Power Readiness";
BA_ "SignalType" SG_ 1238 RevTltMirCstCurSetVal "ENM";
BA_ "SignalLongName" SG_ 1238 RevTltMirCstCurSetVal "ReverseTiltMirrorCustomizationCurrentSettingValue";
BA_ "SignalType" SG_ 1238 RemLftVehRmndrCstCurSetVal "ENM";
BA_ "SignalLongName" SG_ 1238 RemLftVehRmndrCstCurSetVal "RemoteLeftVehicleReminderCustomizationCurrentSettingValue";
BA_ "SignalType" SG_ 1238 RemInVehRmndrCstCurSetVal "ENM";
BA_ "SignalLongName" SG_ 1238 RemInVehRmndrCstCurSetVal "RemoteInVehicleReminderCustomizationCurrentSettingValue";
BA_ "SignalType" SG_ 1238 RmtStrtHtdStCstCrStVal "ENM";
BA_ "SignalLongName" SG_ 1238 RmtStrtHtdStCstCrStVal "Remote Start Heated Seat Customization Current Setting Value";
BA_ "SignalType" SG_ 1238 RmtStrtCoolStCstCrStVal "ENM";
BA_ "SignalLongName" SG_ 1238 RmtStrtCoolStCstCrStVal "Remote Start Cooled Seat Customization Current Setting Value";
BA_ "SignalType" SG_ 1238 RmtSnrfOpCstCurrSetVal "ENM";
BA_ "SignalLongName" SG_ 1238 RmtSnrfOpCstCurrSetVal "Remote Sunroof Operation Customization Current Setting Value";
BA_ "SignalType" SG_ 1238 RtLkFdbkCstCurSetVal "ENM";
BA_ "SignalLongName" SG_ 1238 RtLkFdbkCstCurSetVal "RemoteLockingFeedbackCustomizationCurrentSettingValue";
BA_ "SignalType" SG_ 1238 RmtWndOpCstCurSetVal "ENM";
BA_ "SignalLongName" SG_ 1238 RmtWndOpCstCurSetVal "RemoteWindowOperationCustomizationCurrentSettingValue";
BA_ "SignalType" SG_ 1238 VehLctrLghtsCstCurSetVal "ENM";
BA_ "SignalLongName" SG_ 1238 VehLctrLghtsCstCurSetVal "VehicleLocatorLightsCustomizationCurrentSettingValue";
BA_ "SignalType" SG_ 1238 SelUlkCstCurSetVal "ENM";
BA_ "SignalLongName" SG_ 1238 SelUlkCstCurSetVal "SelectiveUnlockingCustomizationCurrentSettingValue";
BA_ "SignalType" SG_ 1238 RtUlkLtFbCstCurSetVal "ENM";
BA_ "SignalLongName" SG_ 1238 RtUlkLtFbCstCurSetVal "RemoteUnlockLightingFeedbackCustomizationCurrentSettingValue";
BA_ "SignalType" SG_ 1238 RemLftVehRmndrCstStAvl "ENM";
BA_ "SignalLongName" SG_ 1238 RemLftVehRmndrCstStAvl "RemoteLeftVehicleReminderCustomizationSettingAvailable";
BA_ "SignalType" SG_ 1238 RemInVehRmndrCstStAvl "ENM";
BA_ "SignalLongName" SG_ 1238 RemInVehRmndrCstStAvl "RemoteInVehicleReminderCustomizationSettingAvailable";
BA_ "SignalType" SG_ 1238 TrnSwAct "ENM";
BA_ "SignalLongName" SG_ 1238 TrnSwAct "Turn Switch Activation";
BA_ "SignalType" SG_ 1238 WlkAwyLckCstCurSetVal "ENM";
BA_ "SignalLongName" SG_ 1238 WlkAwyLckCstCurSetVal "WalkAwayLockingCustomizationCurrentSettingValue";
BA_ "SignalType" SG_ 1238 SelUlkCstStAvl "ENM";
BA_ "SignalLongName" SG_ 1238 SelUlkCstStAvl "SelectiveUnlockingCustomizationSettingAvailable";
BA_ "SignalType" SG_ 1238 RtUlkLtFbCstStAvl "ENM";
BA_ "SignalLongName" SG_ 1238 RtUlkLtFbCstStAvl "RemoteUnlockLightingFeedbackCustomizationSettingAvailable";
BA_ "SignalType" SG_ 1238 RtLkFdbkCstStAvl "ENM";
BA_ "SignalLongName" SG_ 1238 RtLkFdbkCstStAvl "RemoteLockingFeedbackCustomizationSettingAvailable";
BA_ "SignalType" SG_ 1238 RmtWndOpCstStAvl "ENM";
BA_ "SignalLongName" SG_ 1238 RmtWndOpCstStAvl "RemoteWindowOperationCustomizationSettingAvailable";
BA_ "SignalType" SG_ 1238 RmtStrtHtdStCstStAvl "ENM";
BA_ "SignalLongName" SG_ 1238 RmtStrtHtdStCstStAvl "Remote Start Heated Seat Customization Setting Available";
BA_ "SignalType" SG_ 1238 RmtStrtCoolStCstStAvl "ENM";
BA_ "SignalLongName" SG_ 1238 RmtStrtCoolStCstStAvl "Remote Start Cooled Seat Customization Setting Available";
BA_ "SignalType" SG_ 1238 RmtSnrfOpCstSetAval "ENM";
BA_ "SignalLongName" SG_ 1238 RmtSnrfOpCstSetAval "Remote Sunroof Operation Customization Setting Available";
BA_ "SignalType" SG_ 1238 RevTltMirCstStAvl "ENM";
BA_ "SignalLongName" SG_ 1238 RevTltMirCstStAvl "ReverseTiltMirrorCustomizationSettingAvailable";
BA_ "SignalType" SG_ 1238 WprFrActFltdStat "ENM";
BA_ "SignalLongName" SG_ 1238 WprFrActFltdStat "Wiper Front Active Filtered Status";
BA_ "SignalType" SG_ 1238 WlkAwyLckCstStAvl "ENM";
BA_ "SignalLongName" SG_ 1238 WlkAwyLckCstStAvl "WalkAwayLockingCustomizationSettingAvailable";
BA_ "SignalType" SG_ 1238 VehLctrLghtsCstStAvl "ENM";
BA_ "SignalLongName" SG_ 1238 VehLctrLghtsCstStAvl "VehicleLocatorLightsCustomizationSettingAvailable";
BA_ "SignalType" SG_ 1238 TnDrvSpdLmtCstStAvl "ENM";
BA_ "SignalLongName" SG_ 1238 TnDrvSpdLmtCstStAvl "Teen Driver Speed Limit Customization Setting Available";
BA_ "SignalType" SG_ 1238 TnDrvOvSpdWrnCstStAvl "ENM";
BA_ "SignalLongName" SG_ 1238 TnDrvOvSpdWrnCstStAvl "Teen Driver Overspeed Warning Customization Setting Available";
BA_ "SignalType" SG_ 1239 IHVSLF_HtdBckLvl1 "ENM";
BA_ "SignalLongName" SG_ 1239 IHVSLF_HtdBckLvl1 "Indication Heated Vented Seat Left Front : Heated Back Level 1";
BA_ "SignalType" SG_ 1239 IHVSLF_HtdCushBckMd "ENM";
BA_ "SignalLongName" SG_ 1239 IHVSLF_HtdCushBckMd "Indication Heated Vented Seat Left Front : Heated Cushion and Back Mode";
BA_ "SignalType" SG_ 1239 IHVSLF_HtdBckLvl3 "ENM";
BA_ "SignalLongName" SG_ 1239 IHVSLF_HtdBckLvl3 "Indication Heated Vented Seat Left Front : Heated Back Level 3";
BA_ "SignalType" SG_ 1239 IHVSLF_HtdCushBckLvl3 "ENM";
BA_ "SignalLongName" SG_ 1239 IHVSLF_HtdCushBckLvl3 "Indication Heated Vented Seat Left Front : Heated Cushion and Back Level 3";
BA_ "SignalType" SG_ 1239 IHVSLF_HtdCushBckAuto "ENM";
BA_ "SignalLongName" SG_ 1239 IHVSLF_HtdCushBckAuto "Indication Heated Vented Seat Left Front : Heated Cushion and Back Auto";
BA_ "SignalType" SG_ 1239 IHVSLF_VntLvl1 "ENM";
BA_ "SignalLongName" SG_ 1239 IHVSLF_VntLvl1 "Indication Heated Vented Seat Left Front : Vented Level 1";
BA_ "SignalType" SG_ 1239 IHVSLF_HtdBckAuto "ENM";
BA_ "SignalLongName" SG_ 1239 IHVSLF_HtdBckAuto "Indication Heated Vented Seat Left Front : Heated Back Auto";
BA_ "SignalType" SG_ 1239 IHVSLF_VntLvl2 "ENM";
BA_ "SignalLongName" SG_ 1239 IHVSLF_VntLvl2 "Indication Heated Vented Seat Left Front : Vented Level 2";
BA_ "SignalType" SG_ 1239 IHVSRF_HtdBckMd "ENM";
BA_ "SignalLongName" SG_ 1239 IHVSRF_HtdBckMd "Indication Heated Vented Seat Right Front : Heated Back Mode";
BA_ "SignalType" SG_ 1239 IHVSLF_VntLvl3 "ENM";
BA_ "SignalLongName" SG_ 1239 IHVSLF_VntLvl3 "Indication Heated Vented Seat Left Front : Vented Level 3";
BA_ "SignalType" SG_ 1239 IHVSLF_HtdBckLvl2 "ENM";
BA_ "SignalLongName" SG_ 1239 IHVSLF_HtdBckLvl2 "Indication Heated Vented Seat Left Front : Heated Back Level 2";
BA_ "SignalType" SG_ 1239 IHVSLF_HtdBckMd "ENM";
BA_ "SignalLongName" SG_ 1239 IHVSLF_HtdBckMd "Indication Heated Vented Seat Left Front : Heated Back Mode";
BA_ "SignalType" SG_ 1239 IHVSLF_HtdCushBckLvl1 "ENM";
BA_ "SignalLongName" SG_ 1239 IHVSLF_HtdCushBckLvl1 "Indication Heated Vented Seat Left Front : Heated Cushion and Back Level 1";
BA_ "SignalType" SG_ 1239 IHVSLF_VntAuto "ENM";
BA_ "SignalLongName" SG_ 1239 IHVSLF_VntAuto "Indication Heated Vented Seat Left Front : Vented Auto";
BA_ "SignalType" SG_ 1239 IHVSLF_HtdCushBckLvl2 "ENM";
BA_ "SignalLongName" SG_ 1239 IHVSLF_HtdCushBckLvl2 "Indication Heated Vented Seat Left Front : Heated Cushion and Back Level 2";
BA_ "SignalType" SG_ 1239 IHVSLF_VntMd "ENM";
BA_ "SignalLongName" SG_ 1239 IHVSLF_VntMd "Indication Heated Vented Seat Left Front : Vented Mode";
BA_ "SignalType" SG_ 1239 IHVSRF_VntLvl2 "ENM";
BA_ "SignalLongName" SG_ 1239 IHVSRF_VntLvl2 "Indication Heated Vented Seat Right Front : Vented Level 2";
BA_ "SignalType" SG_ 1239 IHVSRF_HtdCushBckMd "ENM";
BA_ "SignalLongName" SG_ 1239 IHVSRF_HtdCushBckMd "Indication Heated Vented Seat Right Front : Heated Cushion and Back Mode";
BA_ "SignalType" SG_ 1239 IHVSRF_HtdBckLvl3 "ENM";
BA_ "SignalLongName" SG_ 1239 IHVSRF_HtdBckLvl3 "Indication Heated Vented Seat Right Front : Heated Back Level 3";
BA_ "SignalType" SG_ 1239 IHVSRF_HtdCushBckAuto "ENM";
BA_ "SignalLongName" SG_ 1239 IHVSRF_HtdCushBckAuto "Indication Heated Vented Seat Right Front : Heated Cushion and Back Auto";
BA_ "SignalType" SG_ 1239 IHVSRF_HtdCushBckLvl3 "ENM";
BA_ "SignalLongName" SG_ 1239 IHVSRF_HtdCushBckLvl3 "Indication Heated Vented Seat Right Front : Heated Cushion and Back Level 3";
BA_ "SignalType" SG_ 1239 IHVSRF_HtdBckAuto "ENM";
BA_ "SignalLongName" SG_ 1239 IHVSRF_HtdBckAuto "Indication Heated Vented Seat Right Front : Heated Back Auto";
BA_ "SignalType" SG_ 1239 IHVSRF_HtdCushBckLvl1 "ENM";
BA_ "SignalLongName" SG_ 1239 IHVSRF_HtdCushBckLvl1 "Indication Heated Vented Seat Right Front : Heated Cushion and Back Level 1";
BA_ "SignalType" SG_ 1239 IHVSRF_VntLvl1 "ENM";
BA_ "SignalLongName" SG_ 1239 IHVSRF_VntLvl1 "Indication Heated Vented Seat Right Front : Vented Level 1";
BA_ "SignalType" SG_ 1239 TDOSWCCSV_CrSetVal "ENM";
BA_ "SignalLongName" SG_ 1239 TDOSWCCSV_CrSetVal "Teen Driver Overspeed Warning Customization Current Setting Value : Current Setting Value";
BA_ "SignalType" SG_ 1239 IHVSRF_VntAuto "ENM";
BA_ "SignalLongName" SG_ 1239 IHVSRF_VntAuto "Indication Heated Vented Seat Right Front : Vented Auto";
BA_ "SignalType" SG_ 1239 IHVSRF_HtdBckLvl1 "ENM";
BA_ "SignalLongName" SG_ 1239 IHVSRF_HtdBckLvl1 "Indication Heated Vented Seat Right Front : Heated Back Level 1";
BA_ "SignalType" SG_ 1239 IHVSRF_HtdBckLvl2 "ENM";
BA_ "SignalLongName" SG_ 1239 IHVSRF_HtdBckLvl2 "Indication Heated Vented Seat Right Front : Heated Back Level 2";
BA_ "SignalType" SG_ 1239 IHVSRF_VntLvl3 "ENM";
BA_ "SignalLongName" SG_ 1239 IHVSRF_VntLvl3 "Indication Heated Vented Seat Right Front : Vented Level 3";
BA_ "SignalType" SG_ 1239 IHVSRF_HtdCushBckLvl2 "ENM";
BA_ "SignalLongName" SG_ 1239 IHVSRF_HtdCushBckLvl2 "Indication Heated Vented Seat Right Front : Heated Cushion and Back Level 2";
BA_ "SignalType" SG_ 1239 IHVSRF_VntMd "ENM";
BA_ "SignalLongName" SG_ 1239 IHVSRF_VntMd "Indication Heated Vented Seat Right Front : Vented Mode";
BA_ "SignalLongName" SG_ 1239 TDOSWCCSV_DspVal "Teen Driver Overspeed Warning Customization Current Setting Value : Display Value";
BA_ "SignalLongName" SG_ 1239 TDSLCCSV_DspVal "Teen Driver Speed Limit Customization Current Setting Value : Display Value";
BA_ "SignalType" SG_ 1239 TDSLCCSV_CrSetVal "ENM";
BA_ "SignalLongName" SG_ 1239 TDSLCCSV_CrSetVal "Teen Driver Speed Limit Customization Current Setting Value : Current Setting Value";
BA_ "SignalLongName" SG_ 1211 ClmCtlFrtBlwFanSpdFdbkRtlzd "Climate Control Front Blower Fan Speed Feedback Rationalized";
BA_ "SignalType" SG_ 1211 AmbtLgtMnMenuTyp "ENM";
BA_ "SignalLongName" SG_ 1211 AmbtLgtMnMenuTyp "Ambient Lighting Main Menu Type";
BA_ "SignalType" SG_ 1211 ConThftAlrmTrg "ENM";
BA_ "SignalLongName" SG_ 1211 ConThftAlrmTrg "Content Theft Alarm Trigger";
BA_ "SignalType" SG_ 1211 BattVltIRq "ENM";
BA_ "SignalLongName" SG_ 1211 BattVltIRq "Battery Voltage Indication Request";
BA_ "SignalType" SG_ 1211 AlrmClckMgrAlrmCmdFtr6 "ENM";
BA_ "SignalLongName" SG_ 1211 AlrmClckMgrAlrmCmdFtr6 "Alarm Clock Manager Alarm Command Feature 6";
BA_ "SignalType" SG_ 1211 BdyCtlTopSpdLimSrc "ENM";
BA_ "SignalLongName" SG_ 1211 BdyCtlTopSpdLimSrc "Body Control Top Speed Limit Source";
BA_ "SignalType" SG_ 1211 BdyCtlTopSpdLimIndOn "ENM";
BA_ "SignalLongName" SG_ 1211 BdyCtlTopSpdLimIndOn "Body Control Top Speed Limit Indication On";
BA_ "SignalType" SG_ 1211 BdyCtlAccelLimIndOn "ENM";
BA_ "SignalLongName" SG_ 1211 BdyCtlAccelLimIndOn "Body Control Acceleration Limit Indication On";
BA_ "SignalType" SG_ 1211 BatLoStrtVehIndOn "ENM";
BA_ "SignalLongName" SG_ 1211 BatLoStrtVehIndOn "Battery Low Start Vehicle Indication On";
BA_ "SignalType" SG_ 1211 AutoLgtsInActvIndOn "ENM";
BA_ "SignalLongName" SG_ 1211 AutoLgtsInActvIndOn "Automatic Lights Inactive Indication On";
BA_ "SignalType" SG_ 1211 AutoLgtsActvIndOn "ENM";
BA_ "SignalLongName" SG_ 1211 AutoLgtsActvIndOn "Automatic Lights Active Indication On";
BA_ "SignalType" SG_ 1211 ACCmpsrOprtng "ENM";
BA_ "SignalLongName" SG_ 1211 ACCmpsrOprtng "Air Conditioning Compressor Operating";
BA_ "SignalType" SG_ 1211 HtdFrntWSSt "ENM";
BA_ "SignalLongName" SG_ 1211 HtdFrntWSSt "Heated Front Windshield Status";
BA_ "SignalType" SG_ 1211 ConThftAttmpdIO "ENM";
BA_ "SignalLongName" SG_ 1211 ConThftAttmpdIO "Content Theft Attempted Indication On";
BA_ "SignalType" SG_ 1211 CnvtBkWndNotNormzIO "ENM";
BA_ "SignalLongName" SG_ 1211 CnvtBkWndNotNormzIO "Convertible Back Window Not Normalized Indication On";
BA_ "SignalType" SG_ 1211 CmpSftTopMotBfrOpTrnkIO "ENM";
BA_ "SignalLongName" SG_ 1211 CmpSftTopMotBfrOpTrnkIO "Complete Soft Top Motion Before Open Trunk Indication On";
BA_ "SignalType" SG_ 1211 CmbdDrHndlActvRF "ENM";
BA_ "SignalLongName" SG_ 1211 CmbdDrHndlActvRF "Combined Door Handle Active Right Front";
BA_ "SignalType" SG_ 1211 CmbdDrHndlActvLF "ENM";
BA_ "SignalLongName" SG_ 1211 CmbdDrHndlActvLF "Combined Door Handle Active Left Front";
BA_ "SignalType" SG_ 1211 ClmSysDfgRdcdIndOn "ENM";
BA_ "SignalLongName" SG_ 1211 ClmSysDfgRdcdIndOn "Climate System Defogging Reduced Indication On";
BA_ "SignalType" SG_ 1211 ClmSysDfgActvIndOn "ENM";
BA_ "SignalLongName" SG_ 1211 ClmSysDfgActvIndOn "Climate System Defogging Active Indication On";
BA_ "SignalType" SG_ 1211 ClmCtlBatSvrIndOn "ENM";
BA_ "SignalLongName" SG_ 1211 ClmCtlBatSvrIndOn "Climate Control Battery Saver Indication On";
BA_ "SignalType" SG_ 1211 FobProgMdStatCmplt "ENM";
BA_ "SignalLongName" SG_ 1211 FobProgMdStatCmplt "Exiting Fob Programming Indication On";
BA_ "SignalType" SG_ 1211 FobPrevLrndIndOn "ENM";
BA_ "SignalLongName" SG_ 1211 FobPrevLrndIndOn "Fob Previously Learned Indication On";
BA_ "SignalType" SG_ 1211 FobPogLimRchdIndOn "ENM";
BA_ "SignalLongName" SG_ 1211 FobPogLimRchdIndOn "Fob Programming Limit Reached Indication On";
BA_ "SignalType" SG_ 1211 EntrFobProgIndOn "ENM";
BA_ "SignalLongName" SG_ 1211 EntrFobProgIndOn "Entering Fob Programming Indication On";
BA_ "SignalType" SG_ 1211 DlydAccTmrActv "ENM";
BA_ "SignalLongName" SG_ 1211 DlydAccTmrActv "Delayed Accessory Timer Active";
BA_ "SignalType" SG_ 1211 CrgLghtEnbldIO "ENM";
BA_ "SignalLongName" SG_ 1211 CrgLghtEnbldIO "Cargo Light Enabled Indication On";
BA_ "SignalType" SG_ 1211 CrgLghtDsbldIO "ENM";
BA_ "SignalLongName" SG_ 1211 CrgLghtDsbldIO "Cargo Light Disabled Indication On";
BA_ "SignalType" SG_ 1211 ConThftSrvcIO "ENM";
BA_ "SignalLongName" SG_ 1211 ConThftSrvcIO "Content Theft Service Indication On";
BA_ "SignalType" SG_ 1211 HiVltgHtrFaildIndOn "ENM";
BA_ "SignalLongName" SG_ 1211 HiVltgHtrFaildIndOn "High Voltage Heater Failed Indication On";
BA_ "SignalType" SG_ 1211 HiBmIO "ENM";
BA_ "SignalLongName" SG_ 1211 HiBmIO "High Beam Indication On";
BA_ "SignalType" SG_ 1211 HazSwAtvIO "ENM";
BA_ "SignalLongName" SG_ 1211 HazSwAtvIO "Hazard Switch Active Indication On";
BA_ "SignalType" SG_ 1211 HVAC_StngsCtrlAvlbl "ENM";
BA_ "SignalLongName" SG_ 1211 HVAC_StngsCtrlAvlbl "HVAC Settings Controller Available";
BA_ "SignalType" SG_ 1211 FrtSnshdNormzRqrdIO "ENM";
BA_ "SignalLongName" SG_ 1211 FrtSnshdNormzRqrdIO "Front Sunshade Normalization Required Indication On";
BA_ "SignalType" SG_ 1211 FrtCmptServIndOn "ENM";
BA_ "SignalLongName" SG_ 1211 FrtCmptServIndOn "Front Compartment Service Indication On";
BA_ "SignalType" SG_ 1211 FrtClmAppFltDtnActv "ENM";
BA_ "SignalLongName" SG_ 1211 FrtClmAppFltDtnActv "Front Climate App Fault Detection Active";
BA_ "SignalType" SG_ 1211 FuelOprtdHtrOprtgMode "ENM";
BA_ "SignalLongName" SG_ 1211 FuelOprtdHtrOprtgMode "Fuel Operated Heater Operating Mode";
BA_ "SignalType" SG_ 1211 HtdFrtWshldUnvIndOn "ENM";
BA_ "SignalLongName" SG_ 1211 HtdFrtWshldUnvIndOn "Heated Front Windshield Unavailable Indication On";
BA_ "SignalType" SG_ 1211 HiVltgHtrOvrTempIndOn "ENM";
BA_ "SignalLongName" SG_ 1211 HiVltgHtrOvrTempIndOn "High Voltage Heater Over Temperature Indication On";
BA_ "SignalLongName" SG_ 1212 IAQI_IntrAirQltyGasSclPstn "Interior Air Quality Indications : Interior Air Quality Gas Scale Position";
BA_ "SignalLongName" SG_ 1212 IAQI_IntrAirQltyNumOfStats "Interior Air Quality Indications : Interior Air Quality Number Of States";
BA_ "SignalLongName" SG_ 1212 IAQI_IntrAirQltyGasIdx "Interior Air Quality Indications : Interior Air Quality Gas Index";
BA_ "SignalLongName" SG_ 1212 IAQI_IntrAirQltyPrtclteIdx "Interior Air Quality Indications : Interior Air Quality Particulate Index";
BA_ "SignalType" SG_ 1212 IAQI_IntrAirQltyGasStat "ENM";
BA_ "SignalLongName" SG_ 1212 IAQI_IntrAirQltyGasStat "Interior Air Quality Indications : Interior Air Quality Gas State";
BA_ "SignalLongName" SG_ 1212 IAQI_IntrAirQltyOvrallIdx "Interior Air Quality Indications : Interior Air Quality Overall Index";
BA_ "SignalLongName" SG_ 1212 IAQI_IntrAirQltyPrtclteSclPstn "Interior Air Quality Indications : Interior Air Quality Particulate Scale Position";
BA_ "SignalType" SG_ 1212 IAQI_IntrAirQltyOvrallStat "ENM";
BA_ "SignalLongName" SG_ 1212 IAQI_IntrAirQltyOvrallStat "Interior Air Quality Indications : Interior Air Quality Overall State";
BA_ "SignalType" SG_ 1212 IAQI_IntrAirQltyPrtclteStat "ENM";
BA_ "SignalLongName" SG_ 1212 IAQI_IntrAirQltyPrtclteStat "Interior Air Quality Indications : Interior Air Quality Particulate State";
BA_ "SignalLongName" SG_ 1212 IAQI_IntrAirQltyOvrallSclPstn "Interior Air Quality Indications : Interior Air Quality Overall Scale Position";
BA_ "SignalType" SG_ 1213 TDRCADD_WOTEvnts "ENM";
BA_ "SignalLongName" SG_ 1213 TDRCADD_WOTEvnts "Teen Driver Report Card Available Display Data : Wide Open Throttle Events";
BA_ "SignalType" SG_ 1213 TDRCADD_StCtrlEvnts "ENM";
BA_ "SignalLongName" SG_ 1213 TDRCADD_StCtrlEvnts "Teen Driver Report Card Available Display Data : Stability Control Events";
BA_ "SignalType" SG_ 1213 TDRCADD_OvrSpdDistDrvn "ENM";
BA_ "SignalLongName" SG_ 1213 TDRCADD_OvrSpdDistDrvn "Teen Driver Report Card Available Display Data : Overspeed Distance Driven";
BA_ "SignalType" SG_ 1213 TDRCADD_ABSAtvEvt "ENM";
BA_ "SignalLongName" SG_ 1213 TDRCADD_ABSAtvEvt "Teen Driver Report Card Available Display Data : Antilock Braking System Active Events";
BA_ "SignalType" SG_ 1213 TDRCADD_DistDrvn "ENM";
BA_ "SignalLongName" SG_ 1213 TDRCADD_DistDrvn "Teen Driver Report Card Available Display Data : Distance Driven";
BA_ "SignalType" SG_ 1213 TDRCADD_FCHdwyAlrt "ENM";
BA_ "SignalLongName" SG_ 1213 TDRCADD_FCHdwyAlrt "Teen Driver Report Card Available Display Data : Forward Collision Headway Alerts";
BA_ "SignalType" SG_ 1213 TDRCADD_LKAstAlrtsEvnts "ENM";
BA_ "SignalLongName" SG_ 1213 TDRCADD_LKAstAlrtsEvnts "Teen Driver Report Card Available Display Data : Lane Keep Assist Alerts Events";
BA_ "SignalType" SG_ 1213 TDRCADD_MaxSpd "ENM";
BA_ "SignalLongName" SG_ 1213 TDRCADD_MaxSpd "Teen Driver Report Card Available Display Data : Maximum Speed";
BA_ "SignalType" SG_ 1213 TDRCADD_TrCtrlEvnts "ENM";
BA_ "SignalLongName" SG_ 1213 TDRCADD_TrCtrlEvnts "Teen Driver Report Card Available Display Data : Traction Control Events";
BA_ "SignalType" SG_ 1213 TDRCADD_FCMBrEvts "ENM";
BA_ "SignalLongName" SG_ 1213 TDRCADD_FCMBrEvts "Teen Driver Report Card Available Display Data : Forward Collision Mitigation Braking Events";
BA_ "SignalType" SG_ 1213 TDRCADD_LDWEvnts "ENM";
BA_ "SignalLongName" SG_ 1213 TDRCADD_LDWEvnts "Teen Driver Report Card Available Display Data : Lane Departure Warning Events";
BA_ "SignalType" SG_ 1213 TDRCADD_RCMBrEvts "ENM";
BA_ "SignalLongName" SG_ 1213 TDRCADD_RCMBrEvts "Teen Driver Report Card Available Display Data : Reverse Collision Mitigation Braking Events";
BA_ "SignalType" SG_ 1213 TDRCADD_OvSpdEvnt "ENM";
BA_ "SignalLongName" SG_ 1213 TDRCADD_OvSpdEvnt "Teen Driver Report Card Available Display Data : Overspeed Events";
BA_ "SignalType" SG_ 1213 TDRCADD_DrwDrvAlrt "ENM";
BA_ "SignalLongName" SG_ 1213 TDRCADD_DrwDrvAlrt "Teen Driver Report Card Available Display Data : Drowsy Driver Alerts";
BA_ "SignalType" SG_ 1213 TDRCADD_FCImntAlrts "ENM";
BA_ "SignalLongName" SG_ 1213 TDRCADD_FCImntAlrts "Teen Driver Report Card Available Display Data : Forward Collision Imminent Alerts";
BA_ "SignalType" SG_ 1213 TDRCADD_UnbckldDistDrvn "ENM";
BA_ "SignalLongName" SG_ 1213 TDRCADD_UnbckldDistDrvn "Teen Driver Report Card Available Display Data : Unbuckled Distance Driven";
BA_ "SignalType" SG_ 1213 WndNormzRR "ENM";
BA_ "SignalLongName" SG_ 1213 WndNormzRR "Window Normalized Right Rear";
BA_ "SignalType" SG_ 1213 WndNormzRF "ENM";
BA_ "SignalLongName" SG_ 1213 WndNormzRF "Window Normalized Right Front";
BA_ "SignalType" SG_ 1213 WndNormzLR "ENM";
BA_ "SignalLongName" SG_ 1213 WndNormzLR "Window Normalized Left Rear";
BA_ "SignalType" SG_ 1213 WndNormzLF "ENM";
BA_ "SignalLongName" SG_ 1213 WndNormzLF "Window Normalized Left Front";
BA_ "SignalType" SG_ 1213 VTDDrvMsgIO "ENM";
BA_ "SignalLongName" SG_ 1213 VTDDrvMsgIO "VTD Driver Message Indication On";
BA_ "SignalType" SG_ 1213 VTDDrvIndReq "ENM";
BA_ "SignalLongName" SG_ 1213 VTDDrvIndReq "VTD Driver Indication Request";
BA_ "SignalType" SG_ 1213 WndNtNrmzdIORR "ENM";
BA_ "SignalLongName" SG_ 1213 WndNtNrmzdIORR "Window Not Normalized Indication On Right Rear";
BA_ "SignalType" SG_ 1213 WndNtNrmzdIOLR "ENM";
BA_ "SignalLongName" SG_ 1213 WndNtNrmzdIOLR "Window Not Normalized Indication On Left Rear";
BA_ "SignalType" SG_ 1213 WndNtNrmzdIODrv "ENM";
BA_ "SignalLongName" SG_ 1213 WndNtNrmzdIODrv "Window Not Normalized Indication On Driver";
BA_ "SignalType" SG_ 1213 WndNtNrmzdIOCoDrv "ENM";
BA_ "SignalLongName" SG_ 1213 WndNtNrmzdIOCoDrv "Window Not Normalized Indication On Co-Driver";
BA_ "SignalLongName" SG_ 1214 TnDrvUnbckldDistDrvn "Teen Driver Unbuckled Distance Driven";
BA_ "SignalLongName" SG_ 1214 TeenDrvWOTEvntsRpt "Teen Driver Wide Open Throttle Events Report";
BA_ "SignalType" SG_ 1214 TirePrsStatLR "ENM";
BA_ "SignalLongName" SG_ 1214 TirePrsStatLR "TPMS Status (LR)";
BA_ "SignalType" SG_ 1214 TirePrsStatLR_Inv "ENM";
BA_ "SignalLongName" SG_ 1214 TirePrsStatLR_Inv "TPMS Status (LR) Invalid";
BA_ "SignalType" SG_ 1214 TirePrsStatLF "ENM";
BA_ "SignalLongName" SG_ 1214 TirePrsStatLF "TPMS Status (LF)";
BA_ "SignalType" SG_ 1214 TirePrsStatLF_Inv "ENM";
BA_ "SignalLongName" SG_ 1214 TirePrsStatLF_Inv "TPMS Status (LF) Invalid";
BA_ "SignalType" SG_ 1214 TirePrsStatRR "ENM";
BA_ "SignalLongName" SG_ 1214 TirePrsStatRR "TPMS Status (RR)";
BA_ "SignalType" SG_ 1214 TirePrsStatRR_Inv "ENM";
BA_ "SignalLongName" SG_ 1214 TirePrsStatRR_Inv "TPMS Status (RR) Invalid";
BA_ "SignalType" SG_ 1214 TirePrsStatRF "ENM";
BA_ "SignalLongName" SG_ 1214 TirePrsStatRF "TPMS Status (RF)";
BA_ "SignalType" SG_ 1214 TirePrsStatRF_Inv "ENM";
BA_ "SignalLongName" SG_ 1214 TirePrsStatRF_Inv "TPMS Status (RF) Invalid";
BA_ "SignalType" SG_ 1214 TrPrsMntrTrLdStat "ENM";
BA_ "SignalLongName" SG_ 1214 TrPrsMntrTrLdStat "Tire Pressure Monitoring Tire Loading Status";
BA_ "SignalType" SG_ 1214 TrlrLtngSeqStat "ENM";
BA_ "SignalLongName" SG_ 1214 TrlrLtngSeqStat "Trailer Lighting Sequence Status";
BA_ "SignalType" SG_ 1214 TrPrsMntrSysFld "ENM";
BA_ "SignalLongName" SG_ 1214 TrPrsMntrSysFld "Tire Pressure Monitoring System Failed";
BA_ "SignalType" SG_ 1214 TlmtcsImmbAtv "ENM";
BA_ "SignalLongName" SG_ 1214 TlmtcsImmbAtv "Telematics Immobilization Active";
BA_ "SignalType" SG_ 1214 TirePrsLrnActIO "ENM";
BA_ "SignalLongName" SG_ 1214 TirePrsLrnActIO "TPMS Learn Mode Active Indication On";
BA_ "SignalType" SG_ 1214 TireLocatnWarnEn "ENM";
BA_ "SignalLongName" SG_ 1214 TireLocatnWarnEn "TPMS Tire Location Warnings Enabled";
BA_ "SignalType" SG_ 1214 TPMTrLrnMdCmplt "ENM";
BA_ "SignalLongName" SG_ 1214 TPMTrLrnMdCmplt "TPMS Learn Complete Status";
BA_ "SignalType" SG_ 1214 ValetMdResponse "ENM";
BA_ "SignalLongName" SG_ 1214 ValetMdResponse "Valet Mode Lock Response";
BA_ "SignalType" SG_ 1214 XmtrSecurConfRqrdIO "ENM";
BA_ "SignalLongName" SG_ 1214 XmtrSecurConfRqrdIO "Transmitter Security Confirmation Required Indication On";
BA_ "SignalType" SG_ 1214 VehLoBatIndOn "ENM";
BA_ "SignalLongName" SG_ 1214 VehLoBatIndOn "Vehicle Low Battery Indication On";
BA_ "SignalType" SG_ 1214 UIDInStatusSD "ENM";
BA_ "SignalLongName" SG_ 1214 UIDInStatusSD "UID in Status";
BA_ "SignalType" SG_ 1214 TxLrnFldIO "ENM";
BA_ "SignalLongName" SG_ 1214 TxLrnFldIO "Transmitter Learn Failed Indication On";
BA_ "SignalType" SG_ 1214 TxBkUpLctIO "ENM";
BA_ "SignalLongName" SG_ 1214 TxBkUpLctIO "Transmitter Backup Location Indication On";
BA_ "SignalType" SG_ 1214 TurnWprIntIO "ENM";
BA_ "SignalLongName" SG_ 1214 TurnWprIntIO "Turn Wiper Control To Intermittent First Indication On";
BA_ "SignalType" SG_ 1214 TrnstStrgLogisticsMdActivation "ENM";
BA_ "SignalLongName" SG_ 1214 TrnstStrgLogisticsMdActivation "Transport/Storage Logistics Mode Activation";
BA_ "SignalLongName" SG_ 1215 TnDrvOvSpdDistDrvn "Teen Driver Overspeed Distance Driven";
BA_ "SignalLongName" SG_ 1215 TnDrvOvSpdEvntsRpt "Teen Driver Over Speed Events Report";
BA_ "SignalLongName" SG_ 1215 TnDrvStblCtrlEvntsRpt "Teen Driver Stability Control Events Report";
BA_ "SignalLongName" SG_ 1215 TnDrvTrCtrlEvntsRpt "Teen Driver Traction Control Events Report";
BA_ "SignalLongName" SG_ 1215 TeenDrvRmnPINRtry "Teen Driver Remaining PIN Retry";
BA_ "SignalType" SG_ 1215 TeenDrvRsp "ENM";
BA_ "SignalLongName" SG_ 1215 TeenDrvRsp "Teen Driver Response";
BA_ "SignalType" SG_ 1215 TnDrvRptCrdAval "ENM";
BA_ "SignalLongName" SG_ 1215 TnDrvRptCrdAval "Teen Driver Report Card Available";
BA_ "SignalType" SG_ 1215 TnDrvPINStrd "ENM";
BA_ "SignalLongName" SG_ 1215 TnDrvPINStrd "Teen Driver PIN Stored";
BA_ "SignalType" SG_ 1215 TnDrvOvrSpdIO "ENM";
BA_ "SignalLongName" SG_ 1215 TnDrvOvrSpdIO "Teen Driver OverSpeed Indication On";
BA_ "SignalLongName" SG_ 1216 TeenDrvMaxSpdRpt "Teen Driver Maximum Speed Report";
BA_ "SignalLongName" SG_ 1216 TDFwdClnHdwyAlrtsRpt "Teen Driver Forward Collision Headway Alerts Report";
BA_ "SignalLongName" SG_ 1216 TDFwdClnImntAlrtsRpt "Teen Driver Forward Collision Imminent Alerts Report";
BA_ "SignalLongName" SG_ 1216 TDFwdClnMtgnBrEvRpt "Teen Driver Forward Collision Mitigation Braking Events Report";
BA_ "SignalLongName" SG_ 1216 TeenDrvLDWEvntsRpt "Teen Driver Lane Departure Warning Events Report";
BA_ "SignalLongName" SG_ 1216 TnDrvLKAstAlrtEvntsRpt "Teen Driver Lane Keep Assist Alerts Events Report";
BA_ "SignalLongName" SG_ 1217 TnDrvDistDrvnRpt "Teen Driver Distance Driven Report";
BA_ "SignalLongName" SG_ 1217 TnDrvABSAtvEvntsRpt "Teen Driver Antilock Brake System Active Events Report";
BA_ "SignalLongName" SG_ 1217 TnDrvDrowDrvAlrtsRpt "Teen Driver Drowsy Driver Alerts Report";
BA_ "SignalType" SG_ 1217 RemCtrlFobNumForProg "ENM";
BA_ "SignalLongName" SG_ 1217 RemCtrlFobNumForProg "Remote Control Fob Number For Programming";
BA_ "SignalType" SG_ 1217 DrExtHndlActnStatRR "ENM";
BA_ "SignalLongName" SG_ 1217 DrExtHndlActnStatRR "Right Rear Door Exterior Handle Actuation Status";
BA_ "SignalType" SG_ 1217 DrExtHndlActnStatRF "ENM";
BA_ "SignalLongName" SG_ 1217 DrExtHndlActnStatRF "Right Front Door Exterior Handle Actuation Status";
BA_ "SignalType" SG_ 1217 SnrfPstnSts "ENM";
BA_ "SignalLongName" SG_ 1217 SnrfPstnSts "Sunroof Position Status";
BA_ "SignalType" SG_ 1217 ServPwrLftgtIndOn "ENM";
BA_ "SignalLongName" SG_ 1217 ServPwrLftgtIndOn "Service Power Liftgate Indication On";
BA_ "SignalType" SG_ 1217 ServKylsStSysIO "ENM";
BA_ "SignalLongName" SG_ 1217 ServKylsStSysIO "Service Keyless Start System Indication On";
BA_ "SignalType" SG_ 1217 ServHtdStrgWhlIndOn "ENM";
BA_ "SignalLongName" SG_ 1217 ServHtdStrgWhlIndOn "Service Heated Steering Wheel Indication On";
BA_ "SignalType" SG_ 1217 ServDrLtchSysIO "ENM";
BA_ "SignalLongName" SG_ 1217 ServDrLtchSysIO "Service Door Latch System Indication On";
BA_ "SignalType" SG_ 1217 ServBatChrgSysIndOn "ENM";
BA_ "SignalLongName" SG_ 1217 ServBatChrgSysIndOn "Service Battery Charging System Indication On";
BA_ "SignalType" SG_ 1217 RmtCtlFobBatLoIndOn "ENM";
BA_ "SignalLongName" SG_ 1217 RmtCtlFobBatLoIndOn "Remote Control Fob Battery Low Indication On";
BA_ "SignalType" SG_ 1217 DrIntHndlActnStatRR "ENM";
BA_ "SignalLongName" SG_ 1217 DrIntHndlActnStatRR "Right Rear Door Interior Handle Actuation Status";
BA_ "SignalType" SG_ 1217 DrIntHndlActnStatRF "ENM";
BA_ "SignalLongName" SG_ 1217 DrIntHndlActnStatRF "Right Front Door Interior Handle Actuation Status";
BA_ "SignalType" SG_ 1217 TnDrvDRLOffUnbIO "ENM";
BA_ "SignalLongName" SG_ 1217 TnDrvDRLOffUnbIO "Teen Driver Daytime Running Lights Off Unavailable Indication On";
BA_ "SignalType" SG_ 1217 TnDrvALCOffUnbIO "ENM";
BA_ "SignalLongName" SG_ 1217 TnDrvALCOffUnbIO "Teen Driver Automatic Light Control Off Unavailable Indication On";
BA_ "SignalType" SG_ 1217 TeenDrvFtrAvl "ENM";
BA_ "SignalLongName" SG_ 1217 TeenDrvFtrAvl "Teen Driver Feature Available";
BA_ "SignalType" SG_ 1217 StlthModeActv "ENM";
BA_ "SignalLongName" SG_ 1217 StlthModeActv "Stealth Mode Active";
BA_ "SignalType" SG_ 1217 StNtLtchdThrdRowIO "ENM";
BA_ "SignalLongName" SG_ 1217 StNtLtchdThrdRowIO "Seat Not Latched Third Row Indication On";
BA_ "SignalType" SG_ 1217 SnrfNormzRqrdIO "ENM";
BA_ "SignalLongName" SG_ 1217 SnrfNormzRqrdIO "Sunroof Normalization Required Indication On";
BA_ "SignalType" SG_ 1217 ShftoNeutIndOn "ENM";
BA_ "SignalLongName" SG_ 1217 ShftoNeutIndOn "Shift to Neutral Indication On";
BA_ "SignalLongName" SG_ 1218 RrBlwCmd "Rear Blower Command";
BA_ "SignalType" SG_ 1218 DrExtHndlActnStatLF "ENM";
BA_ "SignalLongName" SG_ 1218 DrExtHndlActnStatLF "Left Front Door Exterior Handle Actuation Status";
BA_ "SignalType" SG_ 1218 LstKyFbFnctnReq "ENM";
BA_ "SignalLongName" SG_ 1218 LstKyFbFnctnReq "Last Key Fob Function Request";
BA_ "SignalType" SG_ 1218 IndLowSpdPlltnTkngRecircActMsg "ENM";
BA_ "SignalLongName" SG_ 1218 IndLowSpdPlltnTkngRecircActMsg "Indication Low Speed Pollution Taking Recirc Action Message";
BA_ "SignalType" SG_ 1218 IndIntrAirQltyDispActv "ENM";
BA_ "SignalLongName" SG_ 1218 IndIntrAirQltyDispActv "Indication Interior Air Quality Display Active";
BA_ "SignalType" SG_ 1218 IndFogPrtcTkngFrshAirActMsg "ENM";
BA_ "SignalLongName" SG_ 1218 IndFogPrtcTkngFrshAirActMsg "Indication Fog Protection Taking FreshAir Action Message";
BA_ "SignalType" SG_ 1218 IndAirQltSysTkngRecircActMsg "ENM";
BA_ "SignalLongName" SG_ 1218 IndAirQltSysTkngRecircActMsg "Indication Air Quality System Taking Recirc Action Message";
BA_ "SignalType" SG_ 1218 IndAC_OnBatCoolMsg "ENM";
BA_ "SignalLongName" SG_ 1218 IndAC_OnBatCoolMsg "Indication AC On for Battery Cooling Message";
BA_ "SignalType" SG_ 1218 DrIntHndlActnStatLR "ENM";
BA_ "SignalLongName" SG_ 1218 DrIntHndlActnStatLR "Left Rear Door Interior Handle Actuation Status";
BA_ "SignalType" SG_ 1218 DrIntHndlActnStatLF "ENM";
BA_ "SignalLongName" SG_ 1218 DrIntHndlActnStatLF "Left Front Door Interior Handle Actuation Status";
BA_ "SignalType" SG_ 1218 DrExtHndlActnStatLR "ENM";
BA_ "SignalLongName" SG_ 1218 DrExtHndlActnStatLR "Left Rear Door Exterior Handle Actuation Status";
BA_ "SignalType" SG_ 1218 PwrLftgtOffIndOn "ENM";
BA_ "SignalLongName" SG_ 1218 PwrLftgtOffIndOn "Power Liftgate Off Indication On";
BA_ "SignalType" SG_ 1218 PrkLmpIO "ENM";
BA_ "SignalLongName" SG_ 1218 PrkLmpIO "Park Lamp Indication On";
BA_ "SignalType" SG_ 1218 NghtSchmAtv "ENM";
BA_ "SignalLongName" SG_ 1218 NghtSchmAtv "Night Scheme Active";
BA_ "SignalType" SG_ 1218 LdShedRdcdFtrsIndOn "ENM";
BA_ "SignalLongName" SG_ 1218 LdShedRdcdFtrsIndOn "Load Shed Reduced Features Indication On";
BA_ "SignalType" SG_ 1218 KyIdDevNotPrIO "ENM";
BA_ "SignalLongName" SG_ 1218 KyIdDevNotPrIO "Key/Identification Device Not Present Indication On";
BA_ "SignalType" SG_ 1218 KeyInWrnIO "ENM";
BA_ "SignalLongName" SG_ 1218 KeyInWrnIO "Key In Warning Indication On";
BA_ "SignalType" SG_ 1218 IntrSnsDsbld "ENM";
BA_ "SignalLongName" SG_ 1218 IntrSnsDsbld "Intrusion Sensing Disabled";
BA_ "SignalType" SG_ 1218 IndTmpUnts "ENM";
BA_ "SignalLongName" SG_ 1218 IndTmpUnts "Indication Temperature Units";
BA_ "SignalType" SG_ 1218 IndInzrStat "ENM";
BA_ "SignalLongName" SG_ 1218 IndInzrStat "Indication Ionizer Status";
BA_ "SignalType" SG_ 1218 RrStRmndrIndOn "ENM";
BA_ "SignalLongName" SG_ 1218 RrStRmndrIndOn "Rear Seat Reminder Indication On";
BA_ "SignalType" SG_ 1218 RrSnshdNormzRqrdIO "ENM";
BA_ "SignalLongName" SG_ 1218 RrSnshdNormzRqrdIO "Rear Sunshade Normalization Required Indication On";
BA_ "SignalType" SG_ 1218 RrDrUnlckIO "ENM";
BA_ "SignalLongName" SG_ 1218 RrDrUnlckIO "Rear Door Unlock Indication On";
BA_ "SignalType" SG_ 1218 RnSnsOffIO "ENM";
BA_ "SignalLongName" SG_ 1218 RnSnsOffIO "Rain Sensor Off Indication On";
BA_ "SignalType" SG_ 1218 RnSnsActIO "ENM";
BA_ "SignalLongName" SG_ 1218 RnSnsActIO "Rain Sensor Active Indication On";
BA_ "SignalType" SG_ 1218 PwrLftgtUnvIndOn "ENM";
BA_ "SignalLongName" SG_ 1218 PwrLftgtUnvIndOn "Power Liftgate Unavailable Indication On";
BA_ "SignalType" SG_ 1175 AutDrvLckCstAvlFlg1 "ENM";
BA_ "SignalLongName" SG_ 1175 AutDrvLckCstAvlFlg1 "AutomaticDriveLockingCustomizationAvailabilityFlag1";
BA_ "SignalType" SG_ 1175 AirQltySnsCstAvlFlg7 "ENM";
BA_ "SignalLongName" SG_ 1175 AirQltySnsCstAvlFlg7 "Air Quality Sensor Customization Availability Flag 7";
BA_ "SignalType" SG_ 1175 AirQltySnsCstAvlFlg6 "ENM";
BA_ "SignalLongName" SG_ 1175 AirQltySnsCstAvlFlg6 "Air Quality Sensor Customization Availability Flag 6";
BA_ "SignalType" SG_ 1175 AirQltySnsCstAvlFlg5 "ENM";
BA_ "SignalLongName" SG_ 1175 AirQltySnsCstAvlFlg5 "Air Quality Sensor Customization Availability Flag 5";
BA_ "SignalType" SG_ 1175 AirQltySnsCstAvlFlg4 "ENM";
BA_ "SignalLongName" SG_ 1175 AirQltySnsCstAvlFlg4 "Air Quality Sensor Customization Availability Flag 4";
BA_ "SignalType" SG_ 1175 AirQltySnsCstAvlFlg3 "ENM";
BA_ "SignalLongName" SG_ 1175 AirQltySnsCstAvlFlg3 "Air Quality Sensor Customization Availability Flag 3";
BA_ "SignalType" SG_ 1175 AirQltySnsCstAvlFlg2 "ENM";
BA_ "SignalLongName" SG_ 1175 AirQltySnsCstAvlFlg2 "Air Quality Sensor Customization Availability Flag 2";
BA_ "SignalType" SG_ 1175 AirQltySnsCstAvlFlg1 "ENM";
BA_ "SignalLongName" SG_ 1175 AirQltySnsCstAvlFlg1 "Air Quality Sensor Customization Availability Flag 1";
BA_ "SignalType" SG_ 1175 AutMirFldCstAvlFlg2 "ENM";
BA_ "SignalLongName" SG_ 1175 AutMirFldCstAvlFlg2 "AutoMirrorFoldCustomizationAvailabilityFlag2";
BA_ "SignalType" SG_ 1175 AutMirFldCstAvlFlg1 "ENM";
BA_ "SignalLongName" SG_ 1175 AutMirFldCstAvlFlg1 "AutoMirrorFoldCustomizationAvailabilityFlag1";
BA_ "SignalType" SG_ 1175 AutDrvLckCstAvlFlg7 "ENM";
BA_ "SignalLongName" SG_ 1175 AutDrvLckCstAvlFlg7 "AutomaticDriveLockingCustomizationAvailabilityFlag7";
BA_ "SignalType" SG_ 1175 AutDrvLckCstAvlFlg6 "ENM";
BA_ "SignalLongName" SG_ 1175 AutDrvLckCstAvlFlg6 "AutomaticDriveLockingCustomizationAvailabilityFlag6";
BA_ "SignalType" SG_ 1175 AutDrvLckCstAvlFlg5 "ENM";
BA_ "SignalLongName" SG_ 1175 AutDrvLckCstAvlFlg5 "AutomaticDriveLockingCustomizationAvailabilityFlag5";
BA_ "SignalType" SG_ 1175 AutDrvLckCstAvlFlg4 "ENM";
BA_ "SignalLongName" SG_ 1175 AutDrvLckCstAvlFlg4 "AutomaticDriveLockingCustomizationAvailabilityFlag4";
BA_ "SignalType" SG_ 1175 AutDrvLckCstAvlFlg3 "ENM";
BA_ "SignalLongName" SG_ 1175 AutDrvLckCstAvlFlg3 "AutomaticDriveLockingCustomizationAvailabilityFlag3";
BA_ "SignalType" SG_ 1175 AutDrvLckCstAvlFlg2 "ENM";
BA_ "SignalLongName" SG_ 1175 AutDrvLckCstAvlFlg2 "AutomaticDriveLockingCustomizationAvailabilityFlag2";
BA_ "SignalType" SG_ 1175 AutUnlckCstAvlFlg3 "ENM";
BA_ "SignalLongName" SG_ 1175 AutUnlckCstAvlFlg3 "AutomaticUnlockingCustomizationAvailabilityFlag3";
BA_ "SignalType" SG_ 1175 AutUnlckCstAvlFlg2 "ENM";
BA_ "SignalLongName" SG_ 1175 AutUnlckCstAvlFlg2 "AutomaticUnlockingCustomizationAvailabilityFlag2";
BA_ "SignalType" SG_ 1175 AutUnlckCstAvlFlg1 "ENM";
BA_ "SignalLongName" SG_ 1175 AutUnlckCstAvlFlg1 "AutomaticUnlockingCustomizationAvailabilityFlag1";
BA_ "SignalType" SG_ 1175 AutMirFldCstAvlFlg7 "ENM";
BA_ "SignalLongName" SG_ 1175 AutMirFldCstAvlFlg7 "AutoMirrorFoldCustomizationAvailabilityFlag7";
BA_ "SignalType" SG_ 1175 AutMirFldCstAvlFlg6 "ENM";
BA_ "SignalLongName" SG_ 1175 AutMirFldCstAvlFlg6 "AutoMirrorFoldCustomizationAvailabilityFlag6";
BA_ "SignalType" SG_ 1175 AutMirFldCstAvlFlg5 "ENM";
BA_ "SignalLongName" SG_ 1175 AutMirFldCstAvlFlg5 "AutoMirrorFoldCustomizationAvailabilityFlag5";
BA_ "SignalType" SG_ 1175 AutMirFldCstAvlFlg4 "ENM";
BA_ "SignalLongName" SG_ 1175 AutMirFldCstAvlFlg4 "AutoMirrorFoldCustomizationAvailabilityFlag4";
BA_ "SignalType" SG_ 1175 AutMirFldCstAvlFlg3 "ENM";
BA_ "SignalLongName" SG_ 1175 AutMirFldCstAvlFlg3 "AutoMirrorFoldCustomizationAvailabilityFlag3";
BA_ "SignalType" SG_ 1175 AutoAirDstCstAvlFlg4 "ENM";
BA_ "SignalLongName" SG_ 1175 AutoAirDstCstAvlFlg4 "Automatic Air Distribution Customization Availability Flag 4";
BA_ "SignalType" SG_ 1175 AutoAirDstCstAvlFlg3 "ENM";
BA_ "SignalLongName" SG_ 1175 AutoAirDstCstAvlFlg3 "Automatic Air Distribution Customization Availability Flag 3";
BA_ "SignalType" SG_ 1175 AutoAirDstCstAvlFlg2 "ENM";
BA_ "SignalLongName" SG_ 1175 AutoAirDstCstAvlFlg2 "Automatic Air Distribution Customization Availability Flag 2";
BA_ "SignalType" SG_ 1175 AutoAirDstCstAvlFlg1 "ENM";
BA_ "SignalLongName" SG_ 1175 AutoAirDstCstAvlFlg1 "Automatic Air Distribution Customization Availability Flag 1";
BA_ "SignalType" SG_ 1175 AutUnlckCstAvlFlg7 "ENM";
BA_ "SignalLongName" SG_ 1175 AutUnlckCstAvlFlg7 "AutomaticUnlockingCustomizationAvailabilityFlag7";
BA_ "SignalType" SG_ 1175 AutUnlckCstAvlFlg6 "ENM";
BA_ "SignalLongName" SG_ 1175 AutUnlckCstAvlFlg6 "AutomaticUnlockingCustomizationAvailabilityFlag6";
BA_ "SignalType" SG_ 1175 AutUnlckCstAvlFlg5 "ENM";
BA_ "SignalLongName" SG_ 1175 AutUnlckCstAvlFlg5 "AutomaticUnlockingCustomizationAvailabilityFlag5";
BA_ "SignalType" SG_ 1175 AutUnlckCstAvlFlg4 "ENM";
BA_ "SignalLongName" SG_ 1175 AutUnlckCstAvlFlg4 "AutomaticUnlockingCustomizationAvailabilityFlag4";
BA_ "SignalType" SG_ 1175 AutoCoolStCstAvlFlg5 "ENM";
BA_ "SignalLongName" SG_ 1175 AutoCoolStCstAvlFlg5 "Automatic Cooled Seat Customization Availability Flag 5";
BA_ "SignalType" SG_ 1175 AutoCoolStCstAvlFlg4 "ENM";
BA_ "SignalLongName" SG_ 1175 AutoCoolStCstAvlFlg4 "Automatic Cooled Seat Customization Availability Flag 4";
BA_ "SignalType" SG_ 1175 AutoCoolStCstAvlFlg3 "ENM";
BA_ "SignalLongName" SG_ 1175 AutoCoolStCstAvlFlg3 "Automatic Cooled Seat Customization Availability Flag 3";
BA_ "SignalType" SG_ 1175 AutoCoolStCstAvlFlg2 "ENM";
BA_ "SignalLongName" SG_ 1175 AutoCoolStCstAvlFlg2 "Automatic Cooled Seat Customization Availability Flag 2";
BA_ "SignalType" SG_ 1175 AutoCoolStCstAvlFlg1 "ENM";
BA_ "SignalLongName" SG_ 1175 AutoCoolStCstAvlFlg1 "Automatic Cooled Seat Customization Availability Flag 1";
BA_ "SignalType" SG_ 1175 AutoAirDstCstAvlFlg7 "ENM";
BA_ "SignalLongName" SG_ 1175 AutoAirDstCstAvlFlg7 "Automatic Air Distribution Customization Availability Flag 7";
BA_ "SignalType" SG_ 1175 AutoAirDstCstAvlFlg6 "ENM";
BA_ "SignalLongName" SG_ 1175 AutoAirDstCstAvlFlg6 "Automatic Air Distribution Customization Availability Flag 6";
BA_ "SignalType" SG_ 1175 AutoAirDstCstAvlFlg5 "ENM";
BA_ "SignalLongName" SG_ 1175 AutoAirDstCstAvlFlg5 "Automatic Air Distribution Customization Availability Flag 5";
BA_ "SignalType" SG_ 1175 AutoDfgCstAvlFlg6 "ENM";
BA_ "SignalLongName" SG_ 1175 AutoDfgCstAvlFlg6 "Automatic Defog Customization Availability Flag 6";
BA_ "SignalType" SG_ 1175 AutoDfgCstAvlFlg5 "ENM";
BA_ "SignalLongName" SG_ 1175 AutoDfgCstAvlFlg5 "Automatic Defog Customization Availability Flag 5";
BA_ "SignalType" SG_ 1175 AutoDfgCstAvlFlg4 "ENM";
BA_ "SignalLongName" SG_ 1175 AutoDfgCstAvlFlg4 "Automatic Defog Customization Availability Flag 4";
BA_ "SignalType" SG_ 1175 AutoDfgCstAvlFlg3 "ENM";
BA_ "SignalLongName" SG_ 1175 AutoDfgCstAvlFlg3 "Automatic Defog Customization Availability Flag 3";
BA_ "SignalType" SG_ 1175 AutoDfgCstAvlFlg2 "ENM";
BA_ "SignalLongName" SG_ 1175 AutoDfgCstAvlFlg2 "Automatic Defog Customization Availability Flag 2";
BA_ "SignalType" SG_ 1175 AutoDfgCstAvlFlg1 "ENM";
BA_ "SignalLongName" SG_ 1175 AutoDfgCstAvlFlg1 "Automatic Defog Customization Availability Flag 1";
BA_ "SignalType" SG_ 1175 AutoCoolStCstAvlFlg7 "ENM";
BA_ "SignalLongName" SG_ 1175 AutoCoolStCstAvlFlg7 "Automatic Cooled Seat Customization Availability Flag 7";
BA_ "SignalType" SG_ 1175 AutoCoolStCstAvlFlg6 "ENM";
BA_ "SignalLongName" SG_ 1175 AutoCoolStCstAvlFlg6 "Automatic Cooled Seat Customization Availability Flag 6";
BA_ "SignalType" SG_ 1175 AutoFanCstAvlFlg7 "ENM";
BA_ "SignalLongName" SG_ 1175 AutoFanCstAvlFlg7 "Automatic Fan Customization Availability Flag 7";
BA_ "SignalType" SG_ 1175 AutoFanCstAvlFlg6 "ENM";
BA_ "SignalLongName" SG_ 1175 AutoFanCstAvlFlg6 "Automatic Fan Customization Availability Flag 6";
BA_ "SignalType" SG_ 1175 AutoFanCstAvlFlg5 "ENM";
BA_ "SignalLongName" SG_ 1175 AutoFanCstAvlFlg5 "Automatic Fan Customization Availability Flag 5";
BA_ "SignalType" SG_ 1175 AutoFanCstAvlFlg4 "ENM";
BA_ "SignalLongName" SG_ 1175 AutoFanCstAvlFlg4 "Automatic Fan Customization Availability Flag 4";
BA_ "SignalType" SG_ 1175 AutoFanCstAvlFlg3 "ENM";
BA_ "SignalLongName" SG_ 1175 AutoFanCstAvlFlg3 "Automatic Fan Customization Availability Flag 3";
BA_ "SignalType" SG_ 1175 AutoFanCstAvlFlg2 "ENM";
BA_ "SignalLongName" SG_ 1175 AutoFanCstAvlFlg2 "Automatic Fan Customization Availability Flag 2";
BA_ "SignalType" SG_ 1175 AutoFanCstAvlFlg1 "ENM";
BA_ "SignalLongName" SG_ 1175 AutoFanCstAvlFlg1 "Automatic Fan Customization Availability Flag 1";
BA_ "SignalType" SG_ 1175 AutoDfgCstAvlFlg7 "ENM";
BA_ "SignalLongName" SG_ 1175 AutoDfgCstAvlFlg7 "Automatic Defog Customization Availability Flag 7";
BA_ "SignalType" SG_ 1175 AutoHtdStCstAvlFlg7 "ENM";
BA_ "SignalLongName" SG_ 1175 AutoHtdStCstAvlFlg7 "Automatic Heated Seat Customization Availability Flag 7";
BA_ "SignalType" SG_ 1175 AutoHtdStCstAvlFlg6 "ENM";
BA_ "SignalLongName" SG_ 1175 AutoHtdStCstAvlFlg6 "Automatic Heated Seat Customization Availability Flag 6";
BA_ "SignalType" SG_ 1175 AutoHtdStCstAvlFlg5 "ENM";
BA_ "SignalLongName" SG_ 1175 AutoHtdStCstAvlFlg5 "Automatic Heated Seat Customization Availability Flag 5";
BA_ "SignalType" SG_ 1175 AutoHtdStCstAvlFlg4 "ENM";
BA_ "SignalLongName" SG_ 1175 AutoHtdStCstAvlFlg4 "Automatic Heated Seat Customization Availability Flag 4";
BA_ "SignalType" SG_ 1175 AutoHtdStCstAvlFlg3 "ENM";
BA_ "SignalLongName" SG_ 1175 AutoHtdStCstAvlFlg3 "Automatic Heated Seat Customization Availability Flag 3";
BA_ "SignalType" SG_ 1175 AutoHtdStCstAvlFlg2 "ENM";
BA_ "SignalLongName" SG_ 1175 AutoHtdStCstAvlFlg2 "Automatic Heated Seat Customization Availability Flag 2";
BA_ "SignalType" SG_ 1175 AutoHtdStCstAvlFlg1 "ENM";
BA_ "SignalLongName" SG_ 1175 AutoHtdStCstAvlFlg1 "Automatic Heated Seat Customization Availability Flag 1";
BA_ "SignalLongName" SG_ 1176 HtrCoreInltClntTmpCalc "Heater Core Inlet Coolant Temperature Calculated";
BA_ "SignalType" SG_ 1176 AutoRrWpCstAvlFlg7 "ENM";
BA_ "SignalLongName" SG_ 1176 AutoRrWpCstAvlFlg7 "AutoRearWipeCustomizationAvailabilityFlag7";
BA_ "SignalType" SG_ 1176 AutoRrWpCstAvlFlg6 "ENM";
BA_ "SignalLongName" SG_ 1176 AutoRrWpCstAvlFlg6 "AutoRearWipeCustomizationAvailabilityFlag6";
BA_ "SignalType" SG_ 1176 AutoRrWpCstAvlFlg5 "ENM";
BA_ "SignalLongName" SG_ 1176 AutoRrWpCstAvlFlg5 "AutoRearWipeCustomizationAvailabilityFlag5";
BA_ "SignalType" SG_ 1176 AutoRrWpCstAvlFlg4 "ENM";
BA_ "SignalLongName" SG_ 1176 AutoRrWpCstAvlFlg4 "AutoRearWipeCustomizationAvailabilityFlag4";
BA_ "SignalType" SG_ 1176 AutoRrWpCstAvlFlg3 "ENM";
BA_ "SignalLongName" SG_ 1176 AutoRrWpCstAvlFlg3 "AutoRearWipeCustomizationAvailabilityFlag3";
BA_ "SignalType" SG_ 1176 AutoRrWpCstAvlFlg2 "ENM";
BA_ "SignalLongName" SG_ 1176 AutoRrWpCstAvlFlg2 "AutoRearWipeCustomizationAvailabilityFlag2";
BA_ "SignalType" SG_ 1176 AutoRrWpCstAvlFlg1 "ENM";
BA_ "SignalLongName" SG_ 1176 AutoRrWpCstAvlFlg1 "AutoRearWipeCustomizationAvailabilityFlag1";
BA_ "SignalType" SG_ 1176 ExtLghtCstAvlFlg1 "ENM";
BA_ "SignalLongName" SG_ 1176 ExtLghtCstAvlFlg1 "Exit Lighting CustomizationAvailabilityFlag1";
BA_ "SignalType" SG_ 1176 DaytimeTlLghtsCstAvlFlg7 "ENM";
BA_ "SignalLongName" SG_ 1176 DaytimeTlLghtsCstAvlFlg7 "DaytimeTailLightsCustomizationAvailabilityFlag7";
BA_ "SignalType" SG_ 1176 DaytimeTlLghtsCstAvlFlg6 "ENM";
BA_ "SignalLongName" SG_ 1176 DaytimeTlLghtsCstAvlFlg6 "DaytimeTailLightsCustomizationAvailabilityFlag6";
BA_ "SignalType" SG_ 1176 DaytimeTlLghtsCstAvlFlg5 "ENM";
BA_ "SignalLongName" SG_ 1176 DaytimeTlLghtsCstAvlFlg5 "DaytimeTailLightsCustomizationAvailabilityFlag5";
BA_ "SignalType" SG_ 1176 DaytimeTlLghtsCstAvlFlg4 "ENM";
BA_ "SignalLongName" SG_ 1176 DaytimeTlLghtsCstAvlFlg4 "DaytimeTailLightsCustomizationAvailabilityFlag4";
BA_ "SignalType" SG_ 1176 DaytimeTlLghtsCstAvlFlg3 "ENM";
BA_ "SignalLongName" SG_ 1176 DaytimeTlLghtsCstAvlFlg3 "DaytimeTailLightsCustomizationAvailabilityFlag3";
BA_ "SignalType" SG_ 1176 DaytimeTlLghtsCstAvlFlg2 "ENM";
BA_ "SignalLongName" SG_ 1176 DaytimeTlLghtsCstAvlFlg2 "DaytimeTailLightsCustomizationAvailabilityFlag2";
BA_ "SignalType" SG_ 1176 DaytimeTlLghtsCstAvlFlg1 "ENM";
BA_ "SignalLongName" SG_ 1176 DaytimeTlLghtsCstAvlFlg1 "DaytimeTailLightsCustomizationAvailabilityFlag1";
BA_ "SignalType" SG_ 1176 HFRCCstAvlFlg2 "ENM";
BA_ "SignalLongName" SG_ 1176 HFRCCstAvlFlg2 "HandsFreeRearClosureCustomizationAvailabilityFlag2";
BA_ "SignalType" SG_ 1176 HFRCCstAvlFlg1 "ENM";
BA_ "SignalLongName" SG_ 1176 HFRCCstAvlFlg1 "HandsFreeRearClosureCustomizationAvailabilityFlag1";
BA_ "SignalType" SG_ 1176 ExtLghtCstAvlFlg7 "ENM";
BA_ "SignalLongName" SG_ 1176 ExtLghtCstAvlFlg7 "Exit Lighting CustomizationAvailabilityFlag7";
BA_ "SignalType" SG_ 1176 ExtLghtCstAvlFlg6 "ENM";
BA_ "SignalLongName" SG_ 1176 ExtLghtCstAvlFlg6 "Exit Lighting CustomizationAvailabilityFlag6";
BA_ "SignalType" SG_ 1176 ExtLghtCstAvlFlg5 "ENM";
BA_ "SignalLongName" SG_ 1176 ExtLghtCstAvlFlg5 "Exit Lighting CustomizationAvailabilityFlag5";
BA_ "SignalType" SG_ 1176 ExtLghtCstAvlFlg4 "ENM";
BA_ "SignalLongName" SG_ 1176 ExtLghtCstAvlFlg4 "Exit Lighting CustomizationAvailabilityFlag4";
BA_ "SignalType" SG_ 1176 ExtLghtCstAvlFlg3 "ENM";
BA_ "SignalLongName" SG_ 1176 ExtLghtCstAvlFlg3 "Exit Lighting CustomizationAvailabilityFlag3";
BA_ "SignalType" SG_ 1176 ExtLghtCstAvlFlg2 "ENM";
BA_ "SignalLongName" SG_ 1176 ExtLghtCstAvlFlg2 "Exit Lighting CustomizationAvailabilityFlag2";
BA_ "SignalType" SG_ 1176 HFRCCstAvlFlg7 "ENM";
BA_ "SignalLongName" SG_ 1176 HFRCCstAvlFlg7 "HandsFreeRearClosureCustomizationAvailabilityFlag7";
BA_ "SignalType" SG_ 1176 HFRCCstAvlFlg6 "ENM";
BA_ "SignalLongName" SG_ 1176 HFRCCstAvlFlg6 "HandsFreeRearClosureCustomizationAvailabilityFlag6";
BA_ "SignalType" SG_ 1176 HFRCCstAvlFlg5 "ENM";
BA_ "SignalLongName" SG_ 1176 HFRCCstAvlFlg5 "HandsFreeRearClosureCustomizationAvailabilityFlag5";
BA_ "SignalType" SG_ 1176 HFRCCstAvlFlg4 "ENM";
BA_ "SignalLongName" SG_ 1176 HFRCCstAvlFlg4 "HandsFreeRearClosureCustomizationAvailabilityFlag4";
BA_ "SignalType" SG_ 1176 HFRCCstAvlFlg3 "ENM";
BA_ "SignalLongName" SG_ 1176 HFRCCstAvlFlg3 "HandsFreeRearClosureCustomizationAvailabilityFlag3";
BA_ "SignalLongName" SG_ 1177 HmdtySnsrGlssTemp "Humidity Sensor Glass Temperature";
BA_ "SignalLongName" SG_ 1177 HmdtySnsrTemp "Humidity Sensor Temperature";
BA_ "SignalLongName" SG_ 1177 HmdtySnsrRltvHmdty "Humidity Sensor Relative Humidity";
BA_ "SignalType" SG_ 1177 IonzrCtrlCstAvlFlg4 "ENM";
BA_ "SignalLongName" SG_ 1177 IonzrCtrlCstAvlFlg4 "Ionizer Control Customization Availability Flag 4";
BA_ "SignalType" SG_ 1177 IonzrCtrlCstAvlFlg3 "ENM";
BA_ "SignalLongName" SG_ 1177 IonzrCtrlCstAvlFlg3 "Ionizer Control Customization Availability Flag 3";
BA_ "SignalType" SG_ 1177 IonzrCtrlCstAvlFlg2 "ENM";
BA_ "SignalLongName" SG_ 1177 IonzrCtrlCstAvlFlg2 "Ionizer Control Customization Availability Flag 2";
BA_ "SignalType" SG_ 1177 IonzrCtrlCstAvlFlg1 "ENM";
BA_ "SignalLongName" SG_ 1177 IonzrCtrlCstAvlFlg1 "Ionizer Control Customization Availability Flag 1";
BA_ "SignalType" SG_ 1177 LDCLCstAvlFlg5 "ENM";
BA_ "SignalLongName" SG_ 1177 LDCLCstAvlFlg5 "LastDoorClosedLockingCustomizationAvailabilityFlag5";
BA_ "SignalType" SG_ 1177 LDCLCstAvlFlg4 "ENM";
BA_ "SignalLongName" SG_ 1177 LDCLCstAvlFlg4 "LastDoorClosedLockingCustomizationAvailabilityFlag4";
BA_ "SignalType" SG_ 1177 LDCLCstAvlFlg3 "ENM";
BA_ "SignalLongName" SG_ 1177 LDCLCstAvlFlg3 "LastDoorClosedLockingCustomizationAvailabilityFlag3";
BA_ "SignalType" SG_ 1177 LDCLCstAvlFlg2 "ENM";
BA_ "SignalLongName" SG_ 1177 LDCLCstAvlFlg2 "LastDoorClosedLockingCustomizationAvailabilityFlag2";
BA_ "SignalType" SG_ 1177 LDCLCstAvlFlg1 "ENM";
BA_ "SignalLongName" SG_ 1177 LDCLCstAvlFlg1 "LastDoorClosedLockingCustomizationAvailabilityFlag1";
BA_ "SignalType" SG_ 1177 IonzrCtrlCstAvlFlg7 "ENM";
BA_ "SignalLongName" SG_ 1177 IonzrCtrlCstAvlFlg7 "Ionizer Control Customization Availability Flag 7";
BA_ "SignalType" SG_ 1177 IonzrCtrlCstAvlFlg6 "ENM";
BA_ "SignalLongName" SG_ 1177 IonzrCtrlCstAvlFlg6 "Ionizer Control Customization Availability Flag 6";
BA_ "SignalType" SG_ 1177 IonzrCtrlCstAvlFlg5 "ENM";
BA_ "SignalLongName" SG_ 1177 IonzrCtrlCstAvlFlg5 "Ionizer Control Customization Availability Flag 5";
BA_ "SignalType" SG_ 1177 OpDrAtLOCstAvlFlg6 "ENM";
BA_ "SignalLongName" SG_ 1177 OpDrAtLOCstAvlFlg6 "OpenDoorAntiLockOutCustomizationAvailabilityFlag6";
BA_ "SignalType" SG_ 1177 OpDrAtLOCstAvlFlg5 "ENM";
BA_ "SignalLongName" SG_ 1177 OpDrAtLOCstAvlFlg5 "OpenDoorAntiLockOutCustomizationAvailabilityFlag5";
BA_ "SignalType" SG_ 1177 OpDrAtLOCstAvlFlg4 "ENM";
BA_ "SignalLongName" SG_ 1177 OpDrAtLOCstAvlFlg4 "OpenDoorAntiLockOutCustomizationAvailabilityFlag4";
BA_ "SignalType" SG_ 1177 OpDrAtLOCstAvlFlg3 "ENM";
BA_ "SignalLongName" SG_ 1177 OpDrAtLOCstAvlFlg3 "OpenDoorAntiLockOutCustomizationAvailabilityFlag3";
BA_ "SignalType" SG_ 1177 OpDrAtLOCstAvlFlg2 "ENM";
BA_ "SignalLongName" SG_ 1177 OpDrAtLOCstAvlFlg2 "OpenDoorAntiLockOutCustomizationAvailabilityFlag2";
BA_ "SignalType" SG_ 1177 OpDrAtLOCstAvlFlg1 "ENM";
BA_ "SignalLongName" SG_ 1177 OpDrAtLOCstAvlFlg1 "OpenDoorAntiLockOutCustomizationAvailabilityFlag1";
BA_ "SignalType" SG_ 1177 LDCLCstAvlFlg7 "ENM";
BA_ "SignalLongName" SG_ 1177 LDCLCstAvlFlg7 "LastDoorClosedLockingCustomizationAvailabilityFlag7";
BA_ "SignalType" SG_ 1177 LDCLCstAvlFlg6 "ENM";
BA_ "SignalLongName" SG_ 1177 LDCLCstAvlFlg6 "LastDoorClosedLockingCustomizationAvailabilityFlag6";
BA_ "SignalType" SG_ 1177 PlltnCtrlCstAvlFlg7 "ENM";
BA_ "SignalLongName" SG_ 1177 PlltnCtrlCstAvlFlg7 "Pollution Control Customization Availability Flag 7";
BA_ "SignalType" SG_ 1177 PlltnCtrlCstAvlFlg6 "ENM";
BA_ "SignalLongName" SG_ 1177 PlltnCtrlCstAvlFlg6 "Pollution Control Customization Availability Flag 6";
BA_ "SignalType" SG_ 1177 PlltnCtrlCstAvlFlg5 "ENM";
BA_ "SignalLongName" SG_ 1177 PlltnCtrlCstAvlFlg5 "Pollution Control Customization Availability Flag 5";
BA_ "SignalType" SG_ 1177 PlltnCtrlCstAvlFlg4 "ENM";
BA_ "SignalLongName" SG_ 1177 PlltnCtrlCstAvlFlg4 "Pollution Control Customization Availability Flag 4";
BA_ "SignalType" SG_ 1177 PlltnCtrlCstAvlFlg3 "ENM";
BA_ "SignalLongName" SG_ 1177 PlltnCtrlCstAvlFlg3 "Pollution Control Customization Availability Flag 3";
BA_ "SignalType" SG_ 1177 PlltnCtrlCstAvlFlg2 "ENM";
BA_ "SignalLongName" SG_ 1177 PlltnCtrlCstAvlFlg2 "Pollution Control Customization Availability Flag 2";
BA_ "SignalType" SG_ 1177 PlltnCtrlCstAvlFlg1 "ENM";
BA_ "SignalLongName" SG_ 1177 PlltnCtrlCstAvlFlg1 "Pollution Control Customization Availability Flag 1";
BA_ "SignalType" SG_ 1177 OpDrAtLOCstAvlFlg7 "ENM";
BA_ "SignalLongName" SG_ 1177 OpDrAtLOCstAvlFlg7 "OpenDoorAntiLockOutCustomizationAvailabilityFlag7";
BA_ "SignalType" SG_ 1177 PsvUnlckCstAvlFlg7 "ENM";
BA_ "SignalLongName" SG_ 1177 PsvUnlckCstAvlFlg7 "PassiveUnlockingCustomizationAvailabilityFlag7";
BA_ "SignalType" SG_ 1177 PsvUnlckCstAvlFlg6 "ENM";
BA_ "SignalLongName" SG_ 1177 PsvUnlckCstAvlFlg6 "PassiveUnlockingCustomizationAvailabilityFlag6";
BA_ "SignalType" SG_ 1177 PsvUnlckCstAvlFlg5 "ENM";
BA_ "SignalLongName" SG_ 1177 PsvUnlckCstAvlFlg5 "PassiveUnlockingCustomizationAvailabilityFlag5";
BA_ "SignalType" SG_ 1177 PsvUnlckCstAvlFlg4 "ENM";
BA_ "SignalLongName" SG_ 1177 PsvUnlckCstAvlFlg4 "PassiveUnlockingCustomizationAvailabilityFlag4";
BA_ "SignalType" SG_ 1177 PsvUnlckCstAvlFlg3 "ENM";
BA_ "SignalLongName" SG_ 1177 PsvUnlckCstAvlFlg3 "PassiveUnlockingCustomizationAvailabilityFlag3";
BA_ "SignalType" SG_ 1177 PsvUnlckCstAvlFlg2 "ENM";
BA_ "SignalLongName" SG_ 1177 PsvUnlckCstAvlFlg2 "PassiveUnlockingCustomizationAvailabilityFlag2";
BA_ "SignalType" SG_ 1177 PsvUnlckCstAvlFlg1 "ENM";
BA_ "SignalLongName" SG_ 1177 PsvUnlckCstAvlFlg1 "PassiveUnlockingCustomizationAvailabilityFlag1";
BA_ "SignalType" SG_ 1178 RlkRtUlkDrCstAvlFlg1 "ENM";
BA_ "SignalLongName" SG_ 1178 RlkRtUlkDrCstAvlFlg1 "RelockRemoteUnlockedDoorCustomizationAvailabilityFlag1";
BA_ "SignalType" SG_ 1178 RemInVehRmndrCstAvlFlg7 "ENM";
BA_ "SignalLongName" SG_ 1178 RemInVehRmndrCstAvlFlg7 "RemoteInVehicleReminderCustomizationAvailabilityFlag7";
BA_ "SignalType" SG_ 1178 RemInVehRmndrCstAvlFlg6 "ENM";
BA_ "SignalLongName" SG_ 1178 RemInVehRmndrCstAvlFlg6 "RemoteInVehicleReminderCustomizationAvailabilityFlag6";
BA_ "SignalType" SG_ 1178 RemInVehRmndrCstAvlFlg5 "ENM";
BA_ "SignalLongName" SG_ 1178 RemInVehRmndrCstAvlFlg5 "RemoteInVehicleReminderCustomizationAvailabilityFlag5";
BA_ "SignalType" SG_ 1178 RemInVehRmndrCstAvlFlg4 "ENM";
BA_ "SignalLongName" SG_ 1178 RemInVehRmndrCstAvlFlg4 "RemoteInVehicleReminderCustomizationAvailabilityFlag4";
BA_ "SignalType" SG_ 1178 RemInVehRmndrCstAvlFlg3 "ENM";
BA_ "SignalLongName" SG_ 1178 RemInVehRmndrCstAvlFlg3 "RemoteInVehicleReminderCustomizationAvailabilityFlag3";
BA_ "SignalType" SG_ 1178 RemInVehRmndrCstAvlFlg2 "ENM";
BA_ "SignalLongName" SG_ 1178 RemInVehRmndrCstAvlFlg2 "RemoteInVehicleReminderCustomizationAvailabilityFlag2";
BA_ "SignalType" SG_ 1178 RemInVehRmndrCstAvlFlg1 "ENM";
BA_ "SignalLongName" SG_ 1178 RemInVehRmndrCstAvlFlg1 "RemoteInVehicleReminderCustomizationAvailabilityFlag1";
BA_ "SignalType" SG_ 1178 RmtSnrfOpCstAvlFlg2 "ENM";
BA_ "SignalLongName" SG_ 1178 RmtSnrfOpCstAvlFlg2 "Remote Sunroof Operation Customization Availability Flag 2";
BA_ "SignalType" SG_ 1178 RmtSnrfOpCstAvlFlg1 "ENM";
BA_ "SignalLongName" SG_ 1178 RmtSnrfOpCstAvlFlg1 "Remote Sunroof Operation Customization Availability Flag 1";
BA_ "SignalType" SG_ 1178 RlkRtUlkDrCstAvlFlg7 "ENM";
BA_ "SignalLongName" SG_ 1178 RlkRtUlkDrCstAvlFlg7 "RelockRemoteUnlockedDoorCustomizationAvailabilityFlag7";
BA_ "SignalType" SG_ 1178 RlkRtUlkDrCstAvlFlg6 "ENM";
BA_ "SignalLongName" SG_ 1178 RlkRtUlkDrCstAvlFlg6 "RelockRemoteUnlockedDoorCustomizationAvailabilityFlag6";
BA_ "SignalType" SG_ 1178 RlkRtUlkDrCstAvlFlg5 "ENM";
BA_ "SignalLongName" SG_ 1178 RlkRtUlkDrCstAvlFlg5 "RelockRemoteUnlockedDoorCustomizationAvailabilityFlag5";
BA_ "SignalType" SG_ 1178 RlkRtUlkDrCstAvlFlg4 "ENM";
BA_ "SignalLongName" SG_ 1178 RlkRtUlkDrCstAvlFlg4 "RelockRemoteUnlockedDoorCustomizationAvailabilityFlag4";
BA_ "SignalType" SG_ 1178 RlkRtUlkDrCstAvlFlg3 "ENM";
BA_ "SignalLongName" SG_ 1178 RlkRtUlkDrCstAvlFlg3 "RelockRemoteUnlockedDoorCustomizationAvailabilityFlag3";
BA_ "SignalType" SG_ 1178 RlkRtUlkDrCstAvlFlg2 "ENM";
BA_ "SignalLongName" SG_ 1178 RlkRtUlkDrCstAvlFlg2 "RelockRemoteUnlockedDoorCustomizationAvailabilityFlag2";
BA_ "SignalType" SG_ 1178 RmtStrtCoolStCstAvlFlg3 "ENM";
BA_ "SignalLongName" SG_ 1178 RmtStrtCoolStCstAvlFlg3 "Remote Start Cooled Seat Customization Availability Flag 3";
BA_ "SignalType" SG_ 1178 RmtStrtCoolStCstAvlFlg2 "ENM";
BA_ "SignalLongName" SG_ 1178 RmtStrtCoolStCstAvlFlg2 "Remote Start Cooled Seat Customization Availability Flag 2";
BA_ "SignalType" SG_ 1178 RmtStrtCoolStCstAvlFlg1 "ENM";
BA_ "SignalLongName" SG_ 1178 RmtStrtCoolStCstAvlFlg1 "Remote Start Cooled Seat Customization Availability Flag 1";
BA_ "SignalType" SG_ 1178 RmtSnrfOpCstAvlFlg7 "ENM";
BA_ "SignalLongName" SG_ 1178 RmtSnrfOpCstAvlFlg7 "Remote Sunroof Operation Customization Availability Flag 7";
BA_ "SignalType" SG_ 1178 RmtSnrfOpCstAvlFlg6 "ENM";
BA_ "SignalLongName" SG_ 1178 RmtSnrfOpCstAvlFlg6 "Remote Sunroof Operation Customization Availability Flag 6";
BA_ "SignalType" SG_ 1178 RmtSnrfOpCstAvlFlg5 "ENM";
BA_ "SignalLongName" SG_ 1178 RmtSnrfOpCstAvlFlg5 "Remote Sunroof Operation Customization Availability Flag 5";
BA_ "SignalType" SG_ 1178 RmtSnrfOpCstAvlFlg4 "ENM";
BA_ "SignalLongName" SG_ 1178 RmtSnrfOpCstAvlFlg4 "Remote Sunroof Operation Customization Availability Flag 4";
BA_ "SignalType" SG_ 1178 RmtSnrfOpCstAvlFlg3 "ENM";
BA_ "SignalLongName" SG_ 1178 RmtSnrfOpCstAvlFlg3 "Remote Sunroof Operation Customization Availability Flag 3";
BA_ "SignalType" SG_ 1178 RmtStrtHtdStCstAvlFlg4 "ENM";
BA_ "SignalLongName" SG_ 1178 RmtStrtHtdStCstAvlFlg4 "Remote Start Heated Seat Customization Availability Flag 4";
BA_ "SignalType" SG_ 1178 RmtStrtHtdStCstAvlFlg3 "ENM";
BA_ "SignalLongName" SG_ 1178 RmtStrtHtdStCstAvlFlg3 "Remote Start Heated Seat Customization Availability Flag 3";
BA_ "SignalType" SG_ 1178 RmtStrtHtdStCstAvlFlg2 "ENM";
BA_ "SignalLongName" SG_ 1178 RmtStrtHtdStCstAvlFlg2 "Remote Start Heated Seat Customization Availability Flag 2";
BA_ "SignalType" SG_ 1178 RmtStrtHtdStCstAvlFlg1 "ENM";
BA_ "SignalLongName" SG_ 1178 RmtStrtHtdStCstAvlFlg1 "Remote Start Heated Seat Customization Availability Flag 1";
BA_ "SignalType" SG_ 1178 RmtStrtCoolStCstAvlFlg7 "ENM";
BA_ "SignalLongName" SG_ 1178 RmtStrtCoolStCstAvlFlg7 "Remote Start Cooled Seat Customization Availability Flag 7";
BA_ "SignalType" SG_ 1178 RmtStrtCoolStCstAvlFlg6 "ENM";
BA_ "SignalLongName" SG_ 1178 RmtStrtCoolStCstAvlFlg6 "Remote Start Cooled Seat Customization Availability Flag 6";
BA_ "SignalType" SG_ 1178 RmtStrtCoolStCstAvlFlg5 "ENM";
BA_ "SignalLongName" SG_ 1178 RmtStrtCoolStCstAvlFlg5 "Remote Start Cooled Seat Customization Availability Flag 5";
BA_ "SignalType" SG_ 1178 RmtStrtCoolStCstAvlFlg4 "ENM";
BA_ "SignalLongName" SG_ 1178 RmtStrtCoolStCstAvlFlg4 "Remote Start Cooled Seat Customization Availability Flag 4";
BA_ "SignalType" SG_ 1178 RnSnsCstAvlFlg5 "ENM";
BA_ "SignalLongName" SG_ 1178 RnSnsCstAvlFlg5 "RainSenseCustomizationAvailabilityFlag5";
BA_ "SignalType" SG_ 1178 RnSnsCstAvlFlg4 "ENM";
BA_ "SignalLongName" SG_ 1178 RnSnsCstAvlFlg4 "RainSenseCustomizationAvailabilityFlag4";
BA_ "SignalType" SG_ 1178 RnSnsCstAvlFlg3 "ENM";
BA_ "SignalLongName" SG_ 1178 RnSnsCstAvlFlg3 "RainSenseCustomizationAvailabilityFlag3";
BA_ "SignalType" SG_ 1178 RnSnsCstAvlFlg2 "ENM";
BA_ "SignalLongName" SG_ 1178 RnSnsCstAvlFlg2 "RainSenseCustomizationAvailabilityFlag2";
BA_ "SignalType" SG_ 1178 RnSnsCstAvlFlg1 "ENM";
BA_ "SignalLongName" SG_ 1178 RnSnsCstAvlFlg1 "RainSenseCustomizationAvailabilityFlag1";
BA_ "SignalType" SG_ 1178 RmtStrtHtdStCstAvlFlg7 "ENM";
BA_ "SignalLongName" SG_ 1178 RmtStrtHtdStCstAvlFlg7 "Remote Start Heated Seat Customization Availability Flag 7";
BA_ "SignalType" SG_ 1178 RmtStrtHtdStCstAvlFlg6 "ENM";
BA_ "SignalLongName" SG_ 1178 RmtStrtHtdStCstAvlFlg6 "Remote Start Heated Seat Customization Availability Flag 6";
BA_ "SignalType" SG_ 1178 RmtStrtHtdStCstAvlFlg5 "ENM";
BA_ "SignalLongName" SG_ 1178 RmtStrtHtdStCstAvlFlg5 "Remote Start Heated Seat Customization Availability Flag 5";
BA_ "SignalType" SG_ 1178 RrDfgStUpCstAvlFlg6 "ENM";
BA_ "SignalLongName" SG_ 1178 RrDfgStUpCstAvlFlg6 "Rear Defog Startup Customization Availability Flag 6";
BA_ "SignalType" SG_ 1178 RrDfgStUpCstAvlFlg5 "ENM";
BA_ "SignalLongName" SG_ 1178 RrDfgStUpCstAvlFlg5 "Rear Defog Startup Customization Availability Flag 5";
BA_ "SignalType" SG_ 1178 RrDfgStUpCstAvlFlg4 "ENM";
BA_ "SignalLongName" SG_ 1178 RrDfgStUpCstAvlFlg4 "Rear Defog Startup Customization Availability Flag 4";
BA_ "SignalType" SG_ 1178 RrDfgStUpCstAvlFlg3 "ENM";
BA_ "SignalLongName" SG_ 1178 RrDfgStUpCstAvlFlg3 "Rear Defog Startup Customization Availability Flag 3";
BA_ "SignalType" SG_ 1178 RrDfgStUpCstAvlFlg2 "ENM";
BA_ "SignalLongName" SG_ 1178 RrDfgStUpCstAvlFlg2 "Rear Defog Startup Customization Availability Flag 2";
BA_ "SignalType" SG_ 1178 RrDfgStUpCstAvlFlg1 "ENM";
BA_ "SignalLongName" SG_ 1178 RrDfgStUpCstAvlFlg1 "Rear Defog Startup Customization Availability Flag 1";
BA_ "SignalType" SG_ 1178 RnSnsCstAvlFlg7 "ENM";
BA_ "SignalLongName" SG_ 1178 RnSnsCstAvlFlg7 "RainSenseCustomizationAvailabilityFlag7";
BA_ "SignalType" SG_ 1178 RnSnsCstAvlFlg6 "ENM";
BA_ "SignalLongName" SG_ 1178 RnSnsCstAvlFlg6 "RainSenseCustomizationAvailabilityFlag6";
BA_ "SignalType" SG_ 1178 RrStRmndrEnblDsblCstAvlFlg7 "ENM";
BA_ "SignalLongName" SG_ 1178 RrStRmndrEnblDsblCstAvlFlg7 "Rear Seat Reminder Enable Disable Customization Availability Flag 7";
BA_ "SignalType" SG_ 1178 RrStRmndrEnblDsblCstAvlFlg6 "ENM";
BA_ "SignalLongName" SG_ 1178 RrStRmndrEnblDsblCstAvlFlg6 "Rear Seat Reminder Enable Disable Customization Availability Flag 6";
BA_ "SignalType" SG_ 1178 RrStRmndrEnblDsblCstAvlFlg5 "ENM";
BA_ "SignalLongName" SG_ 1178 RrStRmndrEnblDsblCstAvlFlg5 "Rear Seat Reminder Enable Disable Customization Availability Flag 5";
BA_ "SignalType" SG_ 1178 RrStRmndrEnblDsblCstAvlFlg4 "ENM";
BA_ "SignalLongName" SG_ 1178 RrStRmndrEnblDsblCstAvlFlg4 "Rear Seat Reminder Enable Disable Customization Availability Flag 4";
BA_ "SignalType" SG_ 1178 RrStRmndrEnblDsblCstAvlFlg3 "ENM";
BA_ "SignalLongName" SG_ 1178 RrStRmndrEnblDsblCstAvlFlg3 "Rear Seat Reminder Enable Disable Customization Availability Flag 3";
BA_ "SignalType" SG_ 1178 RrStRmndrEnblDsblCstAvlFlg2 "ENM";
BA_ "SignalLongName" SG_ 1178 RrStRmndrEnblDsblCstAvlFlg2 "Rear Seat Reminder Enable Disable Customization Availability Flag 2";
BA_ "SignalType" SG_ 1178 RrStRmndrEnblDsblCstAvlFlg1 "ENM";
BA_ "SignalLongName" SG_ 1178 RrStRmndrEnblDsblCstAvlFlg1 "Rear Seat Reminder Enable Disable Customization Availability Flag 1";
BA_ "SignalType" SG_ 1178 RrDfgStUpCstAvlFlg7 "ENM";
BA_ "SignalLongName" SG_ 1178 RrDfgStUpCstAvlFlg7 "Rear Defog Startup Customization Availability Flag 7";
BA_ "SignalType" SG_ 1178 RrZnStUpCstAvlFlg7 "ENM";
BA_ "SignalLongName" SG_ 1178 RrZnStUpCstAvlFlg7 "Rear Zone Startup Customization Availability Flag 7";
BA_ "SignalType" SG_ 1178 RrZnStUpCstAvlFlg6 "ENM";
BA_ "SignalLongName" SG_ 1178 RrZnStUpCstAvlFlg6 "Rear Zone Startup Customization Availability Flag 6";
BA_ "SignalType" SG_ 1178 RrZnStUpCstAvlFlg5 "ENM";
BA_ "SignalLongName" SG_ 1178 RrZnStUpCstAvlFlg5 "Rear Zone Startup Customization Availability Flag 5";
BA_ "SignalType" SG_ 1178 RrZnStUpCstAvlFlg4 "ENM";
BA_ "SignalLongName" SG_ 1178 RrZnStUpCstAvlFlg4 "Rear Zone Startup Customization Availability Flag 4";
BA_ "SignalType" SG_ 1178 RrZnStUpCstAvlFlg3 "ENM";
BA_ "SignalLongName" SG_ 1178 RrZnStUpCstAvlFlg3 "Rear Zone Startup Customization Availability Flag 3";
BA_ "SignalType" SG_ 1178 RrZnStUpCstAvlFlg2 "ENM";
BA_ "SignalLongName" SG_ 1178 RrZnStUpCstAvlFlg2 "Rear Zone Startup Customization Availability Flag 2";
BA_ "SignalType" SG_ 1178 RrZnStUpCstAvlFlg1 "ENM";
BA_ "SignalLongName" SG_ 1178 RrZnStUpCstAvlFlg1 "Rear Zone Startup Customization Availability Flag 1";
BA_ "SignalLongName" SG_ 1179 BatSOCStrtUp "RVC 12V Battery State of Charge at Start Up";
BA_ "SignalType" SG_ 1179 RemLftVehRmndrCstAvlFlg6 "ENM";
BA_ "SignalLongName" SG_ 1179 RemLftVehRmndrCstAvlFlg6 "RemoteLeftVehicleReminderCustomizationAvailabilityFlag6";
BA_ "SignalType" SG_ 1179 RemLftVehRmndrCstAvlFlg5 "ENM";
BA_ "SignalLongName" SG_ 1179 RemLftVehRmndrCstAvlFlg5 "RemoteLeftVehicleReminderCustomizationAvailabilityFlag5";
BA_ "SignalType" SG_ 1179 RemLftVehRmndrCstAvlFlg4 "ENM";
BA_ "SignalLongName" SG_ 1179 RemLftVehRmndrCstAvlFlg4 "RemoteLeftVehicleReminderCustomizationAvailabilityFlag4";
BA_ "SignalType" SG_ 1179 RemLftVehRmndrCstAvlFlg3 "ENM";
BA_ "SignalLongName" SG_ 1179 RemLftVehRmndrCstAvlFlg3 "RemoteLeftVehicleReminderCustomizationAvailabilityFlag3";
BA_ "SignalType" SG_ 1179 RemLftVehRmndrCstAvlFlg2 "ENM";
BA_ "SignalLongName" SG_ 1179 RemLftVehRmndrCstAvlFlg2 "RemoteLeftVehicleReminderCustomizationAvailabilityFlag2";
BA_ "SignalType" SG_ 1179 RemLftVehRmndrCstAvlFlg1 "ENM";
BA_ "SignalLongName" SG_ 1179 RemLftVehRmndrCstAvlFlg1 "RemoteLeftVehicleReminderCustomizationAvailabilityFlag1";
BA_ "SignalType" SG_ 1179 RVCBatSOCOver "ENM";
BA_ "SignalLongName" SG_ 1179 RVCBatSOCOver "RVC State of Charge Override";
BA_ "SignalType" SG_ 1179 RevTltMirCstAvlFlg7 "ENM";
BA_ "SignalLongName" SG_ 1179 RevTltMirCstAvlFlg7 "ReverseTiltMirrorCustomizationAvailabilityFlag7";
BA_ "SignalType" SG_ 1179 RevTltMirCstAvlFlg6 "ENM";
BA_ "SignalLongName" SG_ 1179 RevTltMirCstAvlFlg6 "ReverseTiltMirrorCustomizationAvailabilityFlag6";
BA_ "SignalType" SG_ 1179 RevTltMirCstAvlFlg5 "ENM";
BA_ "SignalLongName" SG_ 1179 RevTltMirCstAvlFlg5 "ReverseTiltMirrorCustomizationAvailabilityFlag5";
BA_ "SignalType" SG_ 1179 RevTltMirCstAvlFlg4 "ENM";
BA_ "SignalLongName" SG_ 1179 RevTltMirCstAvlFlg4 "ReverseTiltMirrorCustomizationAvailabilityFlag4";
BA_ "SignalType" SG_ 1179 RevTltMirCstAvlFlg3 "ENM";
BA_ "SignalLongName" SG_ 1179 RevTltMirCstAvlFlg3 "ReverseTiltMirrorCustomizationAvailabilityFlag3";
BA_ "SignalType" SG_ 1179 RevTltMirCstAvlFlg2 "ENM";
BA_ "SignalLongName" SG_ 1179 RevTltMirCstAvlFlg2 "ReverseTiltMirrorCustomizationAvailabilityFlag2";
BA_ "SignalType" SG_ 1179 RevTltMirCstAvlFlg1 "ENM";
BA_ "SignalLongName" SG_ 1179 RevTltMirCstAvlFlg1 "ReverseTiltMirrorCustomizationAvailabilityFlag1";
BA_ "SignalType" SG_ 1179 RemLftVehRmndrCstAvlFlg7 "ENM";
BA_ "SignalLongName" SG_ 1179 RemLftVehRmndrCstAvlFlg7 "RemoteLeftVehicleReminderCustomizationAvailabilityFlag7";
BA_ "SignalType" SG_ 1179 RtLkFdbkCstAvlFlg1 "ENM";
BA_ "SignalLongName" SG_ 1179 RtLkFdbkCstAvlFlg1 "RemoteLockingFeedbackCustomizationAvailabilityFlag1";
BA_ "SignalType" SG_ 1179 RmtWndOpCstAvlFlg7 "ENM";
BA_ "SignalLongName" SG_ 1179 RmtWndOpCstAvlFlg7 "RemoteWindowOperationCustomizationAvailabilityFlag7";
BA_ "SignalType" SG_ 1179 RmtWndOpCstAvlFlg6 "ENM";
BA_ "SignalLongName" SG_ 1179 RmtWndOpCstAvlFlg6 "RemoteWindowOperationCustomizationAvailabilityFlag6";
BA_ "SignalType" SG_ 1179 RmtWndOpCstAvlFlg5 "ENM";
BA_ "SignalLongName" SG_ 1179 RmtWndOpCstAvlFlg5 "RemoteWindowOperationCustomizationAvailabilityFlag5";
BA_ "SignalType" SG_ 1179 RmtWndOpCstAvlFlg4 "ENM";
BA_ "SignalLongName" SG_ 1179 RmtWndOpCstAvlFlg4 "RemoteWindowOperationCustomizationAvailabilityFlag4";
BA_ "SignalType" SG_ 1179 RmtWndOpCstAvlFlg3 "ENM";
BA_ "SignalLongName" SG_ 1179 RmtWndOpCstAvlFlg3 "RemoteWindowOperationCustomizationAvailabilityFlag3";
BA_ "SignalType" SG_ 1179 RmtWndOpCstAvlFlg2 "ENM";
BA_ "SignalLongName" SG_ 1179 RmtWndOpCstAvlFlg2 "RemoteWindowOperationCustomizationAvailabilityFlag2";
BA_ "SignalType" SG_ 1179 RmtWndOpCstAvlFlg1 "ENM";
BA_ "SignalLongName" SG_ 1179 RmtWndOpCstAvlFlg1 "RemoteWindowOperationCustomizationAvailabilityFlag1";
BA_ "SignalType" SG_ 1179 RtUlkLtFbCstAvlFlg2 "ENM";
BA_ "SignalLongName" SG_ 1179 RtUlkLtFbCstAvlFlg2 "RemoteUnlockLightingFeedbackCustomizationAvailabilityFlag2";
BA_ "SignalType" SG_ 1179 RtUlkLtFbCstAvlFlg1 "ENM";
BA_ "SignalLongName" SG_ 1179 RtUlkLtFbCstAvlFlg1 "RemoteUnlockLightingFeedbackCustomizationAvailabilityFlag1";
BA_ "SignalType" SG_ 1179 RtLkFdbkCstAvlFlg7 "ENM";
BA_ "SignalLongName" SG_ 1179 RtLkFdbkCstAvlFlg7 "RemoteLockingFeedbackCustomizationAvailabilityFlag7";
BA_ "SignalType" SG_ 1179 RtLkFdbkCstAvlFlg6 "ENM";
BA_ "SignalLongName" SG_ 1179 RtLkFdbkCstAvlFlg6 "RemoteLockingFeedbackCustomizationAvailabilityFlag6";
BA_ "SignalType" SG_ 1179 RtLkFdbkCstAvlFlg5 "ENM";
BA_ "SignalLongName" SG_ 1179 RtLkFdbkCstAvlFlg5 "RemoteLockingFeedbackCustomizationAvailabilityFlag5";
BA_ "SignalType" SG_ 1179 RtLkFdbkCstAvlFlg4 "ENM";
BA_ "SignalLongName" SG_ 1179 RtLkFdbkCstAvlFlg4 "RemoteLockingFeedbackCustomizationAvailabilityFlag4";
BA_ "SignalType" SG_ 1179 RtLkFdbkCstAvlFlg3 "ENM";
BA_ "SignalLongName" SG_ 1179 RtLkFdbkCstAvlFlg3 "RemoteLockingFeedbackCustomizationAvailabilityFlag3";
BA_ "SignalType" SG_ 1179 RtLkFdbkCstAvlFlg2 "ENM";
BA_ "SignalLongName" SG_ 1179 RtLkFdbkCstAvlFlg2 "RemoteLockingFeedbackCustomizationAvailabilityFlag2";
BA_ "SignalType" SG_ 1179 SelUlkCstAvlFlg3 "ENM";
BA_ "SignalLongName" SG_ 1179 SelUlkCstAvlFlg3 "SelectiveUnlockingCustomizationAvailabilityFlag3";
BA_ "SignalType" SG_ 1179 SelUlkCstAvlFlg2 "ENM";
BA_ "SignalLongName" SG_ 1179 SelUlkCstAvlFlg2 "SelectiveUnlockingCustomizationAvailabilityFlag2";
BA_ "SignalType" SG_ 1179 SelUlkCstAvlFlg1 "ENM";
BA_ "SignalLongName" SG_ 1179 SelUlkCstAvlFlg1 "SelectiveUnlockingCustomizationAvailabilityFlag1";
BA_ "SignalType" SG_ 1179 RtUlkLtFbCstAvlFlg7 "ENM";
BA_ "SignalLongName" SG_ 1179 RtUlkLtFbCstAvlFlg7 "RemoteUnlockLightingFeedbackCustomizationAvailabilityFlag7";
BA_ "SignalType" SG_ 1179 RtUlkLtFbCstAvlFlg6 "ENM";
BA_ "SignalLongName" SG_ 1179 RtUlkLtFbCstAvlFlg6 "RemoteUnlockLightingFeedbackCustomizationAvailabilityFlag6";
BA_ "SignalType" SG_ 1179 RtUlkLtFbCstAvlFlg5 "ENM";
BA_ "SignalLongName" SG_ 1179 RtUlkLtFbCstAvlFlg5 "RemoteUnlockLightingFeedbackCustomizationAvailabilityFlag5";
BA_ "SignalType" SG_ 1179 RtUlkLtFbCstAvlFlg4 "ENM";
BA_ "SignalLongName" SG_ 1179 RtUlkLtFbCstAvlFlg4 "RemoteUnlockLightingFeedbackCustomizationAvailabilityFlag4";
BA_ "SignalType" SG_ 1179 RtUlkLtFbCstAvlFlg3 "ENM";
BA_ "SignalLongName" SG_ 1179 RtUlkLtFbCstAvlFlg3 "RemoteUnlockLightingFeedbackCustomizationAvailabilityFlag3";
BA_ "SignalType" SG_ 1179 SelUlkCstAvlFlg7 "ENM";
BA_ "SignalLongName" SG_ 1179 SelUlkCstAvlFlg7 "SelectiveUnlockingCustomizationAvailabilityFlag7";
BA_ "SignalType" SG_ 1179 SelUlkCstAvlFlg6 "ENM";
BA_ "SignalLongName" SG_ 1179 SelUlkCstAvlFlg6 "SelectiveUnlockingCustomizationAvailabilityFlag6";
BA_ "SignalType" SG_ 1179 SelUlkCstAvlFlg5 "ENM";
BA_ "SignalLongName" SG_ 1179 SelUlkCstAvlFlg5 "SelectiveUnlockingCustomizationAvailabilityFlag5";
BA_ "SignalType" SG_ 1179 SelUlkCstAvlFlg4 "ENM";
BA_ "SignalLongName" SG_ 1179 SelUlkCstAvlFlg4 "SelectiveUnlockingCustomizationAvailabilityFlag4";
BA_ "SignalType" SG_ 1180 IDCTA_ClrTyp20Avl "ENM";
BA_ "SignalLongName" SG_ 1180 IDCTA_ClrTyp20Avl "Interior Dimming Color Type Available : Color Type 20 Available";
BA_ "SignalType" SG_ 1180 IDCTA_ClrTyp28Avl "ENM";
BA_ "SignalLongName" SG_ 1180 IDCTA_ClrTyp28Avl "Interior Dimming Color Type Available : Color Type 28 Available";
BA_ "SignalType" SG_ 1180 IDCTA_ClrTyp15Avl "ENM";
BA_ "SignalLongName" SG_ 1180 IDCTA_ClrTyp15Avl "Interior Dimming Color Type Available : Color Type 15 Available";
BA_ "SignalType" SG_ 1180 IDCTA_ClrTyp30Avl "ENM";
BA_ "SignalLongName" SG_ 1180 IDCTA_ClrTyp30Avl "Interior Dimming Color Type Available : Color Type 30 Available";
BA_ "SignalType" SG_ 1180 IDCTA_ClrTyp13Avl "ENM";
BA_ "SignalLongName" SG_ 1180 IDCTA_ClrTyp13Avl "Interior Dimming Color Type Available : Color Type 13 Available";
BA_ "SignalType" SG_ 1180 IDCTA_ClrTyp22Avl "ENM";
BA_ "SignalLongName" SG_ 1180 IDCTA_ClrTyp22Avl "Interior Dimming Color Type Available : Color Type 22 Available";
BA_ "SignalType" SG_ 1180 IDCTA_ClrTyp17Avl "ENM";
BA_ "SignalLongName" SG_ 1180 IDCTA_ClrTyp17Avl "Interior Dimming Color Type Available : Color Type 17 Available";
BA_ "SignalType" SG_ 1180 IDCTA_OffAvl "ENM";
BA_ "SignalLongName" SG_ 1180 IDCTA_OffAvl "Interior Dimming Color Type Available : Off Available";
BA_ "SignalType" SG_ 1180 IDCTA_ClrTyp29Avl "ENM";
BA_ "SignalLongName" SG_ 1180 IDCTA_ClrTyp29Avl "Interior Dimming Color Type Available : Color Type 29 Available";
BA_ "SignalType" SG_ 1180 IDCTA_ClrTyp8Avl "ENM";
BA_ "SignalLongName" SG_ 1180 IDCTA_ClrTyp8Avl "Interior Dimming Color Type Available : Color Type 8 Available";
BA_ "SignalType" SG_ 1180 IDCTA_ClrTyp27Avl "ENM";
BA_ "SignalLongName" SG_ 1180 IDCTA_ClrTyp27Avl "Interior Dimming Color Type Available : Color Type 27 Available";
BA_ "SignalType" SG_ 1180 IDCTA_ClrTyp1Avl "ENM";
BA_ "SignalLongName" SG_ 1180 IDCTA_ClrTyp1Avl "Interior Dimming Color Type Available : Color Type 1 Available";
BA_ "SignalType" SG_ 1180 IDCTA_ClrTyp14Avl "ENM";
BA_ "SignalLongName" SG_ 1180 IDCTA_ClrTyp14Avl "Interior Dimming Color Type Available : Color Type 14 Available";
BA_ "SignalType" SG_ 1180 IDCTA_ClrTyp25Avl "ENM";
BA_ "SignalLongName" SG_ 1180 IDCTA_ClrTyp25Avl "Interior Dimming Color Type Available : Color Type 25 Available";
BA_ "SignalType" SG_ 1180 IDCTA_ClrTyp3Avl "ENM";
BA_ "SignalLongName" SG_ 1180 IDCTA_ClrTyp3Avl "Interior Dimming Color Type Available : Color Type 3 Available";
BA_ "SignalType" SG_ 1180 IDCTA_ClrTyp12Avl "ENM";
BA_ "SignalLongName" SG_ 1180 IDCTA_ClrTyp12Avl "Interior Dimming Color Type Available : Color Type 12 Available";
BA_ "SignalType" SG_ 1180 IDCTA_ClrTyp18Avl "ENM";
BA_ "SignalLongName" SG_ 1180 IDCTA_ClrTyp18Avl "Interior Dimming Color Type Available : Color Type 18 Available";
BA_ "SignalType" SG_ 1180 IDCTA_ClrTyp9Avl "ENM";
BA_ "SignalLongName" SG_ 1180 IDCTA_ClrTyp9Avl "Interior Dimming Color Type Available : Color Type 9 Available";
BA_ "SignalType" SG_ 1180 IDCTA_ClrTyp16Avl "ENM";
BA_ "SignalLongName" SG_ 1180 IDCTA_ClrTyp16Avl "Interior Dimming Color Type Available : Color Type 16 Available";
BA_ "SignalType" SG_ 1180 IDCTA_ClrTyp21Avl "ENM";
BA_ "SignalLongName" SG_ 1180 IDCTA_ClrTyp21Avl "Interior Dimming Color Type Available : Color Type 21 Available";
BA_ "SignalType" SG_ 1180 IDCTA_ClrTyp11Avl "ENM";
BA_ "SignalLongName" SG_ 1180 IDCTA_ClrTyp11Avl "Interior Dimming Color Type Available : Color Type 11 Available";
BA_ "SignalType" SG_ 1180 IDCTA_ClrTyp5Avl "ENM";
BA_ "SignalLongName" SG_ 1180 IDCTA_ClrTyp5Avl "Interior Dimming Color Type Available : Color Type 5 Available";
BA_ "SignalType" SG_ 1180 IDCTA_ClrTyp24Avl "ENM";
BA_ "SignalLongName" SG_ 1180 IDCTA_ClrTyp24Avl "Interior Dimming Color Type Available : Color Type 24 Available";
BA_ "SignalType" SG_ 1180 IDCTA_ClrTyp7Avl "ENM";
BA_ "SignalLongName" SG_ 1180 IDCTA_ClrTyp7Avl "Interior Dimming Color Type Available : Color Type 7 Available";
BA_ "SignalType" SG_ 1180 IDATA_AnmTyp10Avl "ENM";
BA_ "SignalLongName" SG_ 1180 IDATA_AnmTyp10Avl "Interior Dimming Animation Type Available : Animation Type 10 Available";
BA_ "SignalType" SG_ 1180 IDCTA_ClrTyp23Avl "ENM";
BA_ "SignalLongName" SG_ 1180 IDCTA_ClrTyp23Avl "Interior Dimming Color Type Available : Color Type 23 Available";
BA_ "SignalType" SG_ 1180 IDCTA_ClrTyp19Avl "ENM";
BA_ "SignalLongName" SG_ 1180 IDCTA_ClrTyp19Avl "Interior Dimming Color Type Available : Color Type 19 Available";
BA_ "SignalType" SG_ 1180 IDCTA_ClrTyp26Avl "ENM";
BA_ "SignalLongName" SG_ 1180 IDCTA_ClrTyp26Avl "Interior Dimming Color Type Available : Color Type 26 Available";
BA_ "SignalType" SG_ 1180 IDCTA_ClrTyp2Avl "ENM";
BA_ "SignalLongName" SG_ 1180 IDCTA_ClrTyp2Avl "Interior Dimming Color Type Available : Color Type 2 Available";
BA_ "SignalType" SG_ 1180 IDCTA_ClrTyp6Avl "ENM";
BA_ "SignalLongName" SG_ 1180 IDCTA_ClrTyp6Avl "Interior Dimming Color Type Available : Color Type 6 Available";
BA_ "SignalType" SG_ 1180 IDCTA_ClrTyp4Avl "ENM";
BA_ "SignalLongName" SG_ 1180 IDCTA_ClrTyp4Avl "Interior Dimming Color Type Available : Color Type 4 Available";
BA_ "SignalType" SG_ 1180 IDCTA_ClrTyp10Avl "ENM";
BA_ "SignalLongName" SG_ 1180 IDCTA_ClrTyp10Avl "Interior Dimming Color Type Available : Color Type 10 Available";
BA_ "SignalType" SG_ 1180 IDATA_AnmTyp7Avl "ENM";
BA_ "SignalLongName" SG_ 1180 IDATA_AnmTyp7Avl "Interior Dimming Animation Type Available : Animation Type 7 Available";
BA_ "SignalType" SG_ 1180 IDATA_AnmTyp9Avl "ENM";
BA_ "SignalLongName" SG_ 1180 IDATA_AnmTyp9Avl "Interior Dimming Animation Type Available : Animation Type 9 Available";
BA_ "SignalType" SG_ 1180 IDATA_AnmTyp3Avl "ENM";
BA_ "SignalLongName" SG_ 1180 IDATA_AnmTyp3Avl "Interior Dimming Animation Type Available : Animation Type 3 Available";
BA_ "SignalType" SG_ 1180 IDATA_AnmTyp14Avl "ENM";
BA_ "SignalLongName" SG_ 1180 IDATA_AnmTyp14Avl "Interior Dimming Animation Type Available : Animation Type 14 Available";
BA_ "SignalType" SG_ 1180 IDATA_AnmTyp12Avl "ENM";
BA_ "SignalLongName" SG_ 1180 IDATA_AnmTyp12Avl "Interior Dimming Animation Type Available : Animation Type 12 Available";
BA_ "SignalType" SG_ 1180 IDATA_OffAvl "ENM";
BA_ "SignalLongName" SG_ 1180 IDATA_OffAvl "Interior Dimming Animation Type Available : Off Available";
BA_ "SignalType" SG_ 1180 IDATA_AnmTyp8Avl "ENM";
BA_ "SignalLongName" SG_ 1180 IDATA_AnmTyp8Avl "Interior Dimming Animation Type Available : Animation Type 8 Available";
BA_ "SignalType" SG_ 1180 IDATA_AnmTyp13Avl "ENM";
BA_ "SignalLongName" SG_ 1180 IDATA_AnmTyp13Avl "Interior Dimming Animation Type Available : Animation Type 13 Available";
BA_ "SignalType" SG_ 1180 WlkAwyLckCstAvlFlg2 "ENM";
BA_ "SignalLongName" SG_ 1180 WlkAwyLckCstAvlFlg2 "WalkAwayLockingCustomizationAvailabilityFlag2";
BA_ "SignalType" SG_ 1180 WlkAwyLckCstAvlFlg1 "ENM";
BA_ "SignalLongName" SG_ 1180 WlkAwyLckCstAvlFlg1 "WalkAwayLockingCustomizationAvailabilityFlag1";
BA_ "SignalType" SG_ 1180 IDATA_AnmTyp2Avl "ENM";
BA_ "SignalLongName" SG_ 1180 IDATA_AnmTyp2Avl "Interior Dimming Animation Type Available : Animation Type 2 Available";
BA_ "SignalType" SG_ 1180 IDATA_AnmTyp4Avl "ENM";
BA_ "SignalLongName" SG_ 1180 IDATA_AnmTyp4Avl "Interior Dimming Animation Type Available : Animation Type 4 Available";
BA_ "SignalType" SG_ 1180 IDATA_AnmTyp5Avl "ENM";
BA_ "SignalLongName" SG_ 1180 IDATA_AnmTyp5Avl "Interior Dimming Animation Type Available : Animation Type 5 Available";
BA_ "SignalType" SG_ 1180 IDATA_AnmTyp1Avl "ENM";
BA_ "SignalLongName" SG_ 1180 IDATA_AnmTyp1Avl "Interior Dimming Animation Type Available : Animation Type 1 Available";
BA_ "SignalType" SG_ 1180 IDATA_AnmTyp6Avl "ENM";
BA_ "SignalLongName" SG_ 1180 IDATA_AnmTyp6Avl "Interior Dimming Animation Type Available : Animation Type 6 Available";
BA_ "SignalType" SG_ 1180 IDATA_AnmTyp11Avl "ENM";
BA_ "SignalLongName" SG_ 1180 IDATA_AnmTyp11Avl "Interior Dimming Animation Type Available : Animation Type 11 Available";
BA_ "SignalType" SG_ 1180 WlkAwyLckCstAvlFlg7 "ENM";
BA_ "SignalLongName" SG_ 1180 WlkAwyLckCstAvlFlg7 "WalkAwayLockingCustomizationAvailabilityFlag7";
BA_ "SignalType" SG_ 1180 WlkAwyLckCstAvlFlg6 "ENM";
BA_ "SignalLongName" SG_ 1180 WlkAwyLckCstAvlFlg6 "WalkAwayLockingCustomizationAvailabilityFlag6";
BA_ "SignalType" SG_ 1180 WlkAwyLckCstAvlFlg5 "ENM";
BA_ "SignalLongName" SG_ 1180 WlkAwyLckCstAvlFlg5 "WalkAwayLockingCustomizationAvailabilityFlag5";
BA_ "SignalType" SG_ 1180 WlkAwyLckCstAvlFlg4 "ENM";
BA_ "SignalLongName" SG_ 1180 WlkAwyLckCstAvlFlg4 "WalkAwayLockingCustomizationAvailabilityFlag4";
BA_ "SignalType" SG_ 1180 WlkAwyLckCstAvlFlg3 "ENM";
BA_ "SignalLongName" SG_ 1180 WlkAwyLckCstAvlFlg3 "WalkAwayLockingCustomizationAvailabilityFlag3";
BA_ "SignalLongName" SG_ 1181 TrlrTireRRSnsrID "Trailer Tire Right Rear Sensor Identifier";
BA_ "SignalLongName" SG_ 1181 TrlrTireRRPres "Trailer Tire Right Rear Pressure";
BA_ "SignalType" SG_ 1181 TrlrTireRRPres_Inv "ENM";
BA_ "SignalLongName" SG_ 1181 TrlrTireRRPres_Inv "Trailer Tire Right Rear Pressure Invalid";
BA_ "SignalLongName" SG_ 1181 TrlrTireRRTemp "Trailer Tire Right Rear Temperature";
BA_ "SignalType" SG_ 1181 TrlrTireRRTemp_Inv "ENM";
BA_ "SignalLongName" SG_ 1181 TrlrTireRRTemp_Inv "Trailer Tire Right Rear Temperature Invalid";
BA_ "SignalType" SG_ 1181 VehLctrLghtsCstAvlFlg2 "ENM";
BA_ "SignalLongName" SG_ 1181 VehLctrLghtsCstAvlFlg2 "VehicleLocatorLightsCustomizationAvailabilityFlag2";
BA_ "SignalType" SG_ 1181 VehLctrLghtsCstAvlFlg1 "ENM";
BA_ "SignalLongName" SG_ 1181 VehLctrLghtsCstAvlFlg1 "VehicleLocatorLightsCustomizationAvailabilityFlag1";
BA_ "SignalType" SG_ 1181 TrlrTireRRPresSts "ENM";
BA_ "SignalLongName" SG_ 1181 TrlrTireRRPresSts "Trailer Tire Right Rear Pressure Status";
BA_ "SignalType" SG_ 1181 TrlrTireRRPresSts_Inv "ENM";
BA_ "SignalLongName" SG_ 1181 TrlrTireRRPresSts_Inv "Trailer Tire Right Rear Pressure Status Invalid";
BA_ "SignalType" SG_ 1181 VehLctrLghtsCstAvlFlg7 "ENM";
BA_ "SignalLongName" SG_ 1181 VehLctrLghtsCstAvlFlg7 "VehicleLocatorLightsCustomizationAvailabilityFlag7";
BA_ "SignalType" SG_ 1181 VehLctrLghtsCstAvlFlg6 "ENM";
BA_ "SignalLongName" SG_ 1181 VehLctrLghtsCstAvlFlg6 "VehicleLocatorLightsCustomizationAvailabilityFlag6";
BA_ "SignalType" SG_ 1181 VehLctrLghtsCstAvlFlg5 "ENM";
BA_ "SignalLongName" SG_ 1181 VehLctrLghtsCstAvlFlg5 "VehicleLocatorLightsCustomizationAvailabilityFlag5";
BA_ "SignalType" SG_ 1181 VehLctrLghtsCstAvlFlg4 "ENM";
BA_ "SignalLongName" SG_ 1181 VehLctrLghtsCstAvlFlg4 "VehicleLocatorLightsCustomizationAvailabilityFlag4";
BA_ "SignalType" SG_ 1181 VehLctrLghtsCstAvlFlg3 "ENM";
BA_ "SignalLongName" SG_ 1181 VehLctrLghtsCstAvlFlg3 "VehicleLocatorLightsCustomizationAvailabilityFlag3";
VAL_ 1208 TkModeDrvlineVisDispVal 0 "Setting_Unknown" 1 "Custom_Mode_1" 2 "Custom_Mode_2" 3 "Custom_Mode_3" 4 "Custom_Mode_4" 5 "Custom_Mode_5" 6 "Custom_Mode_6" 7 "Custom_Mode_7" ;
VAL_ 1208 TkModeBrkPedVisDispVal 0 "Setting_Unknown" 1 "Custom_Mode_1" 2 "Custom_Mode_2" 3 "Custom_Mode_3" 4 "Custom_Mode_4" 5 "Custom_Mode_5" 6 "Custom_Mode_6" 7 "Custom_Mode_7" ;
VAL_ 1208 TkModeActvAeroVisDispVal 0 "Setting_Unknown" 1 "Custom_Mode_1" 2 "Custom_Mode_2" 3 "Custom_Mode_3" 4 "Custom_Mode_4" 5 "Custom_Mode_5" 6 "Custom_Mode_6" 7 "Custom_Mode_7" ;
VAL_ 1208 TkModeRideHghtVisDispVal 0 "Setting_Unknown" 1 "Custom_Mode_1" 2 "Custom_Mode_2" 3 "Custom_Mode_3" 4 "Custom_Mode_4" 5 "Custom_Mode_5" 6 "Custom_Mode_6" 7 "Custom_Mode_7" ;
VAL_ 1208 TkModePwrtrnVisDispVal 0 "Setting_Unknown" 1 "Custom_Mode_1" 2 "Custom_Mode_2" 3 "Custom_Mode_3" 4 "Custom_Mode_4" 5 "Custom_Mode_5" 6 "Custom_Mode_6" 7 "Custom_Mode_7" ;
VAL_ 1208 TkModeESCVisDispVal 0 "Setting_Unknown" 1 "Custom_Mode_1" 2 "Custom_Mode_2" 3 "Custom_Mode_3" 4 "Custom_Mode_4" 5 "Custom_Mode_5" 6 "Custom_Mode_6" 7 "Custom_Mode_7" ;
VAL_ 1208 TkModeSpnsnVisDispVal 0 "Setting_Unknown" 1 "Custom_Mode_1" 2 "Custom_Mode_2" 3 "Custom_Mode_3" 4 "Custom_Mode_4" 5 "Custom_Mode_5" 6 "Custom_Mode_6" 7 "Custom_Mode_7" ;
VAL_ 1208 TkModeSndVisDispVal 0 "Setting_Unknown" 1 "Custom_Mode_1" 2 "Custom_Mode_2" 3 "Custom_Mode_3" 4 "Custom_Mode_4" 5 "Custom_Mode_5" 6 "Custom_Mode_6" 7 "Custom_Mode_7" ;
VAL_ 1208 WthrSnwModeBrkPedVisDispVal 0 "Setting_Unknown" 1 "Custom_Mode_1" 2 "Custom_Mode_2" 3 "Custom_Mode_3" 4 "Custom_Mode_4" 5 "Custom_Mode_5" 6 "Custom_Mode_6" 7 "Custom_Mode_7" ;
VAL_ 1208 WthrSnwModeActvAeroVisDispVal 0 "Setting_Unknown" 1 "Custom_Mode_1" 2 "Custom_Mode_2" 3 "Custom_Mode_3" 4 "Custom_Mode_4" 5 "Custom_Mode_5" 6 "Custom_Mode_6" 7 "Custom_Mode_7" ;
VAL_ 1208 TkModeStrgVisDispVal 0 "Setting_Unknown" 1 "Custom_Mode_1" 2 "Custom_Mode_2" 3 "Custom_Mode_3" 4 "Custom_Mode_4" 5 "Custom_Mode_5" 6 "Custom_Mode_6" 7 "Custom_Mode_7" ;
VAL_ 1208 WthrSnwModePwrtrnVisDispVal 0 "Setting_Unknown" 1 "Custom_Mode_1" 2 "Custom_Mode_2" 3 "Custom_Mode_3" 4 "Custom_Mode_4" 5 "Custom_Mode_5" 6 "Custom_Mode_6" 7 "Custom_Mode_7" ;
VAL_ 1208 WthrSnwModeESCVisDispVal 0 "Setting_Unknown" 1 "Custom_Mode_1" 2 "Custom_Mode_2" 3 "Custom_Mode_3" 4 "Custom_Mode_4" 5 "Custom_Mode_5" 6 "Custom_Mode_6" 7 "Custom_Mode_7" ;
VAL_ 1208 WthrSnwModeDrvlineVisDispVal 0 "Setting_Unknown" 1 "Custom_Mode_1" 2 "Custom_Mode_2" 3 "Custom_Mode_3" 4 "Custom_Mode_4" 5 "Custom_Mode_5" 6 "Custom_Mode_6" 7 "Custom_Mode_7" ;
VAL_ 1208 WthrSnwModeSndVisDispVal 0 "Setting_Unknown" 1 "Custom_Mode_1" 2 "Custom_Mode_2" 3 "Custom_Mode_3" 4 "Custom_Mode_4" 5 "Custom_Mode_5" 6 "Custom_Mode_6" 7 "Custom_Mode_7" ;
VAL_ 1208 WthrSnwModeRideHghtVisDispVal 0 "Setting_Unknown" 1 "Custom_Mode_1" 2 "Custom_Mode_2" 3 "Custom_Mode_3" 4 "Custom_Mode_4" 5 "Custom_Mode_5" 6 "Custom_Mode_6" 7 "Custom_Mode_7" ;
VAL_ 1208 TrcStbScrConfig 0 "None" 1 "TCS Only" 2 "TCS and ESC" 3 "TCS ESC and Comp" ;
VAL_ 1208 WthrSnwModeStrgVisDispVal 0 "Setting_Unknown" 1 "Custom_Mode_1" 2 "Custom_Mode_2" 3 "Custom_Mode_3" 4 "Custom_Mode_4" 5 "Custom_Mode_5" 6 "Custom_Mode_6" 7 "Custom_Mode_7" ;
VAL_ 1208 WthrSnwModeSpnsnVisDispVal 0 "Setting_Unknown" 1 "Custom_Mode_1" 2 "Custom_Mode_2" 3 "Custom_Mode_3" 4 "Custom_Mode_4" 5 "Custom_Mode_5" 6 "Custom_Mode_6" 7 "Custom_Mode_7" ;
VAL_ 1208 TrcCntrlSysTmpDisReqIO 0 "FALSE" 1 "TRUE" ;
VAL_ 1208 TrcCntrlOnIO 0 "FALSE" 1 "TRUE" ;
VAL_ 1208 TrcCntrlOffIO 0 "FALSE" 1 "TRUE" ;
VAL_ 1208 TCSCustAv 0 "FALSE" 1 "TRUE" ;
VAL_ 1208 TCSCurStat 0 "On" 1 "Off" ;
VAL_ 1209 SprtModeBrkPedVisDispVal 0 "Setting_Unknown" 1 "Custom_Mode_1" 2 "Custom_Mode_2" 3 "Custom_Mode_3" 4 "Custom_Mode_4" 5 "Custom_Mode_5" 6 "Custom_Mode_6" 7 "Custom_Mode_7" ;
VAL_ 1209 SprtModeActvAeroVisDispVal 0 "Setting_Unknown" 1 "Custom_Mode_1" 2 "Custom_Mode_2" 3 "Custom_Mode_3" 4 "Custom_Mode_4" 5 "Custom_Mode_5" 6 "Custom_Mode_6" 7 "Custom_Mode_7" ;
VAL_ 1209 PerfTracMgmtMode 0 "Disabled" 1 "Wet" 2 "Dry" 3 "Sport 1" 4 "Sport 2/Race 1" 5 "Race" 6 "Inactive" ;
VAL_ 1209 SprtModePwrtrnVisDispVal 0 "Setting_Unknown" 1 "Custom_Mode_1" 2 "Custom_Mode_2" 3 "Custom_Mode_3" 4 "Custom_Mode_4" 5 "Custom_Mode_5" 6 "Custom_Mode_6" 7 "Custom_Mode_7" ;
VAL_ 1209 SprtModeESCVisDispVal 0 "Setting_Unknown" 1 "Custom_Mode_1" 2 "Custom_Mode_2" 3 "Custom_Mode_3" 4 "Custom_Mode_4" 5 "Custom_Mode_5" 6 "Custom_Mode_6" 7 "Custom_Mode_7" ;
VAL_ 1209 SprtModeDrvlineVisDispVal 0 "Setting_Unknown" 1 "Custom_Mode_1" 2 "Custom_Mode_2" 3 "Custom_Mode_3" 4 "Custom_Mode_4" 5 "Custom_Mode_5" 6 "Custom_Mode_6" 7 "Custom_Mode_7" ;
VAL_ 1209 SprtModeSndVisDispVal 0 "Setting_Unknown" 1 "Custom_Mode_1" 2 "Custom_Mode_2" 3 "Custom_Mode_3" 4 "Custom_Mode_4" 5 "Custom_Mode_5" 6 "Custom_Mode_6" 7 "Custom_Mode_7" ;
VAL_ 1209 SprtModeRideHghtVisDispVal 0 "Setting_Unknown" 1 "Custom_Mode_1" 2 "Custom_Mode_2" 3 "Custom_Mode_3" 4 "Custom_Mode_4" 5 "Custom_Mode_5" 6 "Custom_Mode_6" 7 "Custom_Mode_7" ;
VAL_ 1209 TireTrdTempSts 0 "Unknown" 1 "Cold" 2 "Cool" 3 "Normal" 4 "Warm" 5 "Hot" ;
VAL_ 1209 SprtModeStrgVisDispVal 0 "Setting_Unknown" 1 "Custom_Mode_1" 2 "Custom_Mode_2" 3 "Custom_Mode_3" 4 "Custom_Mode_4" 5 "Custom_Mode_5" 6 "Custom_Mode_6" 7 "Custom_Mode_7" ;
VAL_ 1209 SprtModeSpnsnVisDispVal 0 "Setting_Unknown" 1 "Custom_Mode_1" 2 "Custom_Mode_2" 3 "Custom_Mode_3" 4 "Custom_Mode_4" 5 "Custom_Mode_5" 6 "Custom_Mode_6" 7 "Custom_Mode_7" ;
VAL_ 1209 TourModeDrvlineVisDispVal 0 "Setting_Unknown" 1 "Custom_Mode_1" 2 "Custom_Mode_2" 3 "Custom_Mode_3" 4 "Custom_Mode_4" 5 "Custom_Mode_5" 6 "Custom_Mode_6" 7 "Custom_Mode_7" ;
VAL_ 1209 TourModeBrkPedVisDispVal 0 "Setting_Unknown" 1 "Custom_Mode_1" 2 "Custom_Mode_2" 3 "Custom_Mode_3" 4 "Custom_Mode_4" 5 "Custom_Mode_5" 6 "Custom_Mode_6" 7 "Custom_Mode_7" ;
VAL_ 1209 TourModeActvAeroVisDispVal 0 "Setting_Unknown" 1 "Custom_Mode_1" 2 "Custom_Mode_2" 3 "Custom_Mode_3" 4 "Custom_Mode_4" 5 "Custom_Mode_5" 6 "Custom_Mode_6" 7 "Custom_Mode_7" ;
VAL_ 1209 TourModePwrtrnVisDispVal 0 "Setting_Unknown" 1 "Custom_Mode_1" 2 "Custom_Mode_2" 3 "Custom_Mode_3" 4 "Custom_Mode_4" 5 "Custom_Mode_5" 6 "Custom_Mode_6" 7 "Custom_Mode_7" ;
VAL_ 1209 TourModeESCVisDispVal 0 "Setting_Unknown" 1 "Custom_Mode_1" 2 "Custom_Mode_2" 3 "Custom_Mode_3" 4 "Custom_Mode_4" 5 "Custom_Mode_5" 6 "Custom_Mode_6" 7 "Custom_Mode_7" ;
VAL_ 1209 TourModeSpnsnVisDispVal 0 "Setting_Unknown" 1 "Custom_Mode_1" 2 "Custom_Mode_2" 3 "Custom_Mode_3" 4 "Custom_Mode_4" 5 "Custom_Mode_5" 6 "Custom_Mode_6" 7 "Custom_Mode_7" ;
VAL_ 1209 TourModeSndVisDispVal 0 "Setting_Unknown" 1 "Custom_Mode_1" 2 "Custom_Mode_2" 3 "Custom_Mode_3" 4 "Custom_Mode_4" 5 "Custom_Mode_5" 6 "Custom_Mode_6" 7 "Custom_Mode_7" ;
VAL_ 1209 TourModeRideHghtVisDispVal 0 "Setting_Unknown" 1 "Custom_Mode_1" 2 "Custom_Mode_2" 3 "Custom_Mode_3" 4 "Custom_Mode_4" 5 "Custom_Mode_5" 6 "Custom_Mode_6" 7 "Custom_Mode_7" ;
VAL_ 1209 TnDrvTrCtrlOffUnvIndOn 0 "FALSE" 1 "TRUE" ;
VAL_ 1209 SrBkLwBkFlDrVisMsgRqOn 0 "FALSE" 1 "TRUE" ;
VAL_ 1209 ShfToPrkBfrExtIndOn 0 "FALSE" 1 "TRUE" ;
VAL_ 1209 TourModeStrgVisDispVal 0 "Setting_Unknown" 1 "Custom_Mode_1" 2 "Custom_Mode_2" 3 "Custom_Mode_3" 4 "Custom_Mode_4" 5 "Custom_Mode_5" 6 "Custom_Mode_6" 7 "Custom_Mode_7" ;
VAL_ 1210 HillDscntCtlSysSts 0 "Unknown" 1 "Normal" 2 "Enabled" 3 "Active" 4 "Failed" ;
VAL_ 1210 EngSndPerfModeReq 0 "No Action" 1 "Tour" 2 "Sport" 3 "Track" 4 "Stealth" 5 "Performance Mode 5" 6 "Performance Mode 6" 7 "Performance Mode 7" ;
VAL_ 1210 DrvModeVisScreenSts 0 "No_Action" 1 "Custom" 2 "Personal" 3 "Sport" 4 "Snow_Ice" 5 "Weather" 6 "Tour" 7 "Track" 8 "Offroad" 9 "TowHaul" 10 "PerformanceSportPlus" ;
VAL_ 1210 BrksOvrht 0 "FALSE" 1 "TRUE" ;
VAL_ 1210 BrkSysHillStrtAsstAvl 0 "FALSE" 1 "TRUE" ;
VAL_ 1210 BrkPadLifeRrCnfrmRplcmtIndOn 0 "FALSE" 1 "TRUE" ;
VAL_ 1210 BrkPadLifeFrtCnfrmRplcmtIndOn 0 "FALSE" 1 "TRUE" ;
VAL_ 1210 BrkPadLifeRrDistWrnIndReq 0 "No Action" 1 "Low" 2 "Display Distance" ;
VAL_ 1210 HillDscntCtlRdcVehSpdIndOn 0 "FALSE" 1 "TRUE" ;
VAL_ 1210 CustmStbCtlRdctReqIndOn 0 "FALSE" 1 "TRUE" ;
VAL_ 1236 AutMirFldCstCurSetVal 0 "SETTING_UNKNOWN" 1 "Off" 2 "On" 3 "RESERVED_3" 4 "RESERVED_4" 5 "RESERVED_5" 6 "RESERVED_6" 7 "RESERVED_7" ;
VAL_ 1236 AutDrvLckCstCurSetVal 0 "SETTING_UNKNOWN" 1 "OFF" 2 "ON" 3 "RESERVED_3" 4 "RESERVED_4" 5 "RESERVED_5" 6 "RESERVED_6" 7 "RESERVED_7" ;
VAL_ 1236 AirQltySnsCstCrStVal 0 "SETTING_UNKNOWN" 1 "OFF" 2 "LOW_SENSITIVITY" 3 "HI_SENSITIVITY" 4 "RESERVED_1" 5 "RESERVED_2" 6 "RESERVED_3" 7 "RESERVED_4" ;
VAL_ 1236 AutoCoolStCstCrStVal 0 "SETTING_UNKNOWN" 1 "OFF" 2 "ON" 3 "RESERVED_1" 4 "RESERVED_2" 5 "RESERVED_3" 6 "RESERVED_4" 7 "RESERVED_5" ;
VAL_ 1236 AutoAirDstCstCrStVal 0 "SETTING_UNKNOWN" 1 "DIFFUSE_AIRFLOW" 2 "NORMAL" 3 "DIRECT_AIRFLOW" 4 "OSCILLATING_AIRFLOW" 5 "RESERVED_1" 6 "RESERVED_2" 7 "RESERVED_3" ;
VAL_ 1236 AutUnlckCstCurSetVal 0 "NO_ACTION" 1 "OFF" 2 "ALL_DOORS" 3 "DRIVER_DOOR" 4 "RESERVED_4" 5 "RESERVED_5" 6 "RESERVED_6" 7 "RESERVED_7" ;
VAL_ 1236 AutoFanCstCrStVal 0 "SETTING_UNKNOWN" 1 "LOW" 2 "NORMAL" 3 "HIGH" 4 "RESERVED_1" 5 "RESERVED_2" 6 "RESERVED_3" 7 "RESERVED_4" ;
VAL_ 1236 AutoDfgCstCrStVal 0 "SETTING_UNKNOWN" 1 "OFF" 2 "ON" 3 "RESERVED_1" 4 "RESERVED_2" 5 "RESERVED_3" 6 "RESERVED_4" 7 "RESERVED_5" ;
VAL_ 1236 DaytimeTlLghtsCstCurSetVal 0 "SETTING_UNKNOWN" 1 "OFF" 2 "ON" 3 "RESERVED_3" 4 "RESERVED_4" 5 "RESERVED_5" 6 "RESERVED_6" 7 "RESERVED_7" ;
VAL_ 1236 AutoRrWpCstCurSetVal 0 "SETTING_UNKNOWN" 1 "OFF" 2 "ON" 3 "RESERVED_3" 4 "RESERVED_4" 5 "RESERVED_5" 6 "RESERVED_6" 7 "RESERVED_7" ;
VAL_ 1236 AutoHtdStCstCrStVal 0 "SETTING_UNKNOWN" 1 "OFF" 2 "ON" 3 "RESERVED_1" 4 "RESERVED_2" 5 "RESERVED_3" 6 "RESERVED_4" 7 "RESERVED_5" ;
VAL_ 1236 AutoAirDstCstStAvl 0 "FALSE" 1 "TRUE" ;
VAL_ 1236 AutUnlckCstStAvl 0 "FALSE" 1 "TRUE" ;
VAL_ 1236 AutMirFldCstStAvl 0 "FALSE" 1 "TRUE" ;
VAL_ 1236 AutDrvLckCstStAvl 0 "FALSE" 1 "TRUE" ;
VAL_ 1236 AirQltySnsCstStAvl 0 "FALSE" 1 "TRUE" ;
VAL_ 1236 CurbVwFtrActvReq 0 "On" 1 "Off" 2 "Failed" ;
VAL_ 1236 DM1Unavailable 0 "FALSE" 1 "TRUE" ;
VAL_ 1236 DM1Pending 0 "FALSE" 1 "TRUE" ;
VAL_ 1236 CrsCntCncRq 0 "Do Not Cancel" 1 "Cancel" ;
VAL_ 1236 AutoRrWpCstStAvl 0 "FALSE" 1 "TRUE" ;
VAL_ 1236 AutoHtdStCstStAvl 0 "FALSE" 1 "TRUE" ;
VAL_ 1236 AutoFanCstStAvl 0 "FALSE" 1 "TRUE" ;
VAL_ 1236 AutoDfgCstStAvl 0 "FALSE" 1 "TRUE" ;
VAL_ 1236 AutoCoolStCstStAvl 0 "FALSE" 1 "TRUE" ;
VAL_ 1236 DM5Unavailable 0 "FALSE" 1 "TRUE" ;
VAL_ 1236 DM5Pending 0 "FALSE" 1 "TRUE" ;
VAL_ 1236 DM4Unavailable 0 "FALSE" 1 "TRUE" ;
VAL_ 1236 DM4Pending 0 "FALSE" 1 "TRUE" ;
VAL_ 1236 DM3Unavailable 0 "FALSE" 1 "TRUE" ;
VAL_ 1236 DM3Pending 0 "FALSE" 1 "TRUE" ;
VAL_ 1236 DM2Unavailable 0 "FALSE" 1 "TRUE" ;
VAL_ 1236 DM2Pending 0 "FALSE" 1 "TRUE" ;
VAL_ 1236 DaytimeTlLghtsCstStAvl 0 "FALSE" 1 "TRUE" ;
VAL_ 1236 DM8Unavailable 0 "FALSE" 1 "TRUE" ;
VAL_ 1236 DM8Pending 0 "FALSE" 1 "TRUE" ;
VAL_ 1236 DM7Unavailable 0 "FALSE" 1 "TRUE" ;
VAL_ 1236 DM7Pending 0 "FALSE" 1 "TRUE" ;
VAL_ 1236 DM6Unavailable 0 "FALSE" 1 "TRUE" ;
VAL_ 1236 DM6Pending 0 "FALSE" 1 "TRUE" ;
VAL_ 1237 IntDimSeldAnmTypStVal 0 "No Action" 1 "Off" 2 "Animation Type 1" 3 "Animation Type 2" 4 "Animation Type 3" 5 "Animation Type 4" 6 "Animation Type 5" 7 "Animation Type 6" 8 "Animation Type 7" 9 "Animation Type 8" 10 "Animation Type 9" 11 "Animation Type 10" 12 "Animation Type 11" 13 "Animation Type 12" 14 "Animation Type 13" 15 "Animation Type 14" ;
VAL_ 1237 IntDimSeldClrTypStVal 0 "No Action" 1 "Off" 2 "Color Type 1" 3 "Color Type 2" 4 "Color Type 3" 5 "Color Type 4" 6 "Color Type 5" 7 "Color Type 6" 8 "Color Type 7" 9 "Color Type 8" 10 "Color Type 9" 11 "Color Type 10" 12 "Color Type 11" 13 "Color Type 12" 14 "Color Type 13" 15 "Color Type 14" 16 "Color Type 15" 17 "Color Type 16" 18 "Color Type 17" 19 "Color Type 18" 20 "Color Type 19" 21 "Color Type 20" 22 "Color Type 21" 23 "Color Type 22" 24 "Color Type 23" 25 "Color Type 24" 26 "Color Type 25" 27 "Color Type 26" 28 "Color Type 27" 29 "Color Type 28" 30 "Color Type 29" 31 "Color Type 30" ;
VAL_ 1237 IonzrCtrlCstCrStVal 0 "SETTING_UNKNOWN" 1 "OFF" 2 "ON" 3 "RESERVED_1" 4 "RESERVED_2" 5 "RESERVED_3" 6 "RESERVED_4" 7 "RESERVED_5" ;
VAL_ 1237 HFRCCstCurSetVal 0 "SETTING_UNKNOWN" 1 "OFF" 2 "OPEN_AND_CLOSE" 3 "OPEN_ONLY" 4 "RESERVED_4" 5 "RESERVED_5" 6 "RESERVED_6" 7 "RESERVED_7" ;
VAL_ 1237 ExtLghtCstCurSetVal 0 "SETTING_UNKNOWN" 1 "OFF" 2 "THIRTY_SECONDS_DEFAULT" 3 "ONE_MINUTE" 4 "TWO_MINUTES" 5 "RESERVED_5" 6 "RESERVED_6" 7 "RESERVED_7" ;
VAL_ 1237 OpDrAtLOCstCurSetVal 0 "SETTING_UNKNOWN" 1 "OFF" 2 "ON" 3 "RESERVED_3" 4 "RESERVED_4" 5 "RESERVED_5" 6 "RESERVED_6" 7 "RESERVED_7" ;
VAL_ 1237 LDCLCstCurSetVal 0 "SETTING_UNKNOWN" 1 "OFF" 2 "ON" 3 "RESERVED_3" 4 "RESERVED_4" 5 "RESERVED_5" 6 "RESERVED_6" 7 "RESERVED_7" ;
VAL_ 1237 RlkRtUlkDrCstCrSetVal 0 "SETTING_UNKNOWN" 1 "OFF" 2 "ON" 3 "RESERVED_3" 4 "RESERVED_4" 5 "RESERVED_5" 6 "RESERVED_6" 7 "RESERVED_7" ;
VAL_ 1237 PsvUnlckCstCurSetVal 0 "SETTING_UNKNOWN" 1 "DRIVER_DOOR" 2 "ALL_DOORS" 3 "OFF" 4 "RESERVED_4" 5 "RESERVED_5" 6 "RESERVED_6" 7 "RESERVED_7" ;
VAL_ 1237 PlltnCtrlCstCrStVal 0 "SETTING_UNKNOWN" 1 "OFF" 2 "ON" 3 "RESERVED_1" 4 "RESERVED_2" 5 "RESERVED_3" 6 "RESERVED_4" 7 "RESERVED_5" ;
VAL_ 1237 RrStRmndrEnblDsblCstCurrSetVal 0 "Setting_Unknown" 1 "Off" 2 "On" 3 "(Reserved_3" 4 "Reserved_4" 5 "Reserved_5" 6 "Reserved_6" 7 "Reserved_7)" ;
VAL_ 1237 RrDfgStUpCstCrStVal 0 "SETTING_UNKNOWN" 1 "MANUAL" 2 "AUTOMATIC" 3 "RESERVED_1" 4 "RESERVED_2" 5 "RESERVED_3" 6 "RESERVED_4" 7 "RESERVED_5" ;
VAL_ 1237 RnSnsCstCurSetVal 0 "SETTING_UNKNOWN" 1 "OFF" 2 "ON" 3 "RESERVED_3" 4 "RESERVED_4" 5 "RESERVED_5" 6 "RESERVED_6" 7 "RESERVED_7" ;
VAL_ 1237 ExtLghtCstStAvl 0 "FALSE" 1 "TRUE" ;
VAL_ 1237 RrAirHandlingDrActrPwrReq 0 "No Action" 1 "Power Off" 2 "Power On" ;
VAL_ 1237 RrZnStUpCstCrStVal 0 "SETTING_UNKNOWN" 1 "REAR_OFF" 2 "REAR_MIMIC_FRONT" 3 "REAR_LAST_KNOWN" 4 "RESERVED_1" 5 "RESERVED_2" 6 "RESERVED_3" 7 "RESERVED_4" ;
VAL_ 1237 RnSnsCstStAvl 0 "FALSE" 1 "TRUE" ;
VAL_ 1237 RlkRtUlkDrCstStAvl 0 "FALSE" 1 "TRUE" ;
VAL_ 1237 PsvUnlckCstStAvl 0 "FALSE" 1 "TRUE" ;
VAL_ 1237 PlltnCtrlCstStAvl 0 "FALSE" 1 "TRUE" ;
VAL_ 1237 OpDrAtLOCstStAvl 0 "FALSE" 1 "TRUE" ;
VAL_ 1237 LDCLCstStAvl 0 "FALSE" 1 "TRUE" ;
VAL_ 1237 IonzrCtrlCstStAvl 0 "FALSE" 1 "TRUE" ;
VAL_ 1237 HFRCCstStAvl 0 "FALSE" 1 "TRUE" ;
VAL_ 1237 RrZnStUpCstStAvl 0 "FALSE" 1 "TRUE" ;
VAL_ 1237 RrStRmndrEnblDsblCstSetAval 0 "FALSE" 1 "TRUE" ;
VAL_ 1237 RrDfgStUpCstStAvl 0 "FALSE" 1 "TRUE" ;
VAL_ 1238 RevTltMirCstCurSetVal 0 "SETTING_UNKNOWN" 1 "OFF" 2 "DRIVER" 3 "PASSENGER" 4 "DRIVER_AND_PASSENGER" 5 "RESERVED_5" 6 "RESERVED_6" 7 "RESERVED_7" ;
VAL_ 1238 RemLftVehRmndrCstCurSetVal 0 "SETTING_UNKNOWN" 1 "OFF" 2 "ON" 3 "RESERVED_3" 4 "RESERVED_4" 5 "RESERVED_5" 6 "RESERVED_6" 7 "RESERVED_7" ;
VAL_ 1238 RemInVehRmndrCstCurSetVal 0 "SETTING_UNKNOWN" 1 "OFF" 2 "ON" 3 "RESERVED_3" 4 "RESERVED_4" 5 "RESERVED_5" 6 "RESERVED_6" 7 "RESERVED_7" ;
VAL_ 1238 RmtStrtHtdStCstCrStVal 0 "SETTING_UNKNOWN" 1 "OFF" 2 "ON" 3 "RESERVED_1" 4 "RESERVED_2" 5 "RESERVED_3" 6 "RESERVED_4" 7 "RESERVED_5" ;
VAL_ 1238 RmtStrtCoolStCstCrStVal 0 "SETTING_UNKNOWN" 1 "OFF" 2 "ON" 3 "RESERVED_1" 4 "RESERVED_2" 5 "RESERVED_3" 6 "RESERVED_4" 7 "RESERVED_5" ;
VAL_ 1238 RmtSnrfOpCstCurrSetVal 0 "Setting_Unknown" 1 "Off" 2 "On" 3 "Reserved_3" 4 "Reserved_4" 5 "Reserved_5" 6 "Reserved_6" 7 "Reserved_7" ;
VAL_ 1238 RtLkFdbkCstCurSetVal 0 "SETTING_UNKNOWN" 1 "HORN_AND_LIGHTS_OFF" 2 "HORN_AND_LIGHTS_ON" 3 "FLASH_LIGHTS_ONLY" 4 "HORN_CHIRP_ONLY" 5 "RESERVED_5" 6 "RESERVED_6" 7 "RESERVED_7" ;
VAL_ 1238 RmtWndOpCstCurSetVal 0 "SETTING_UNKNOWN" 1 "OFF" 2 "ON" 3 "RESERVED_3" 4 "RESERVED_4" 5 "RESERVED_5" 6 "RESERVED_6" 7 "RESERVED_7" ;
VAL_ 1238 VehLctrLghtsCstCurSetVal 0 "SETTING_UNKNOWN" 1 "OFF" 2 "ON" 3 "RESERVED_3" 4 "RESERVED_4" 5 "RESERVED_5" 6 "RESERVED_6" 7 "RESERVED_7" ;
VAL_ 1238 SelUlkCstCurSetVal 0 "SETTING_UNKNOWN" 1 "DRIVER_DOOR_ONLY" 2 "ALL_DOORS" 3 "RESERVED_3" 4 "RESERVED_4" 5 "RESERVED_5" 6 "RESERVED_6" 7 "RESERVED_7" ;
VAL_ 1238 RtUlkLtFbCstCurSetVal 0 "SETTING_UNKNOWN" 1 "OFF" 2 "FLASH_LIGHTS_ON" 3 "RESERVED_3" 4 "RESERVED_4" 5 "RESERVED_5" 6 "RESERVED_6" 7 "RESERVED_7" ;
VAL_ 1238 RemLftVehRmndrCstStAvl 0 "FALSE" 1 "TRUE" ;
VAL_ 1238 RemInVehRmndrCstStAvl 0 "FALSE" 1 "TRUE" ;
VAL_ 1238 TrnSwAct 0 "NO_ACTIVATION" 1 "LEFT" 2 "RIGHT" ;
VAL_ 1238 WlkAwyLckCstCurSetVal 0 "SETTING_UNKNOWN" 1 "OFF" 2 "ON" 3 "ON_WITH_CHIRP" 4 "RESERVED_4" 5 "RESERVED_5" 6 "RESERVED_6" 7 "RESERVED_7" ;
VAL_ 1238 SelUlkCstStAvl 0 "FALSE" 1 "TRUE" ;
VAL_ 1238 RtUlkLtFbCstStAvl 0 "FALSE" 1 "TRUE" ;
VAL_ 1238 RtLkFdbkCstStAvl 0 "FALSE" 1 "TRUE" ;
VAL_ 1238 RmtWndOpCstStAvl 0 "FALSE" 1 "TRUE" ;
VAL_ 1238 RmtStrtHtdStCstStAvl 0 "FALSE" 1 "TRUE" ;
VAL_ 1238 RmtStrtCoolStCstStAvl 0 "FALSE" 1 "TRUE" ;
VAL_ 1238 RmtSnrfOpCstSetAval 0 "FALSE" 1 "TRUE" ;
VAL_ 1238 RevTltMirCstStAvl 0 "FALSE" 1 "TRUE" ;
VAL_ 1238 WprFrActFltdStat 0 "FALSE" 1 "TRUE" ;
VAL_ 1238 WlkAwyLckCstStAvl 0 "FALSE" 1 "TRUE" ;
VAL_ 1238 VehLctrLghtsCstStAvl 0 "FALSE" 1 "TRUE" ;
VAL_ 1238 TnDrvSpdLmtCstStAvl 0 "FALSE" 1 "TRUE" ;
VAL_ 1238 TnDrvOvSpdWrnCstStAvl 0 "FALSE" 1 "TRUE" ;
VAL_ 1239 IHVSLF_HtdBckLvl1 0 "FALSE" 1 "TRUE" ;
VAL_ 1239 IHVSLF_HtdCushBckMd 0 "FALSE" 1 "TRUE" ;
VAL_ 1239 IHVSLF_HtdBckLvl3 0 "FALSE" 1 "TRUE" ;
VAL_ 1239 IHVSLF_HtdCushBckLvl3 0 "FALSE" 1 "TRUE" ;
VAL_ 1239 IHVSLF_HtdCushBckAuto 0 "FALSE" 1 "TRUE" ;
VAL_ 1239 IHVSLF_VntLvl1 0 "FALSE" 1 "TRUE" ;
VAL_ 1239 IHVSLF_HtdBckAuto 0 "FALSE" 1 "TRUE" ;
VAL_ 1239 IHVSLF_VntLvl2 0 "FALSE" 1 "TRUE" ;
VAL_ 1239 IHVSRF_HtdBckMd 0 "FALSE" 1 "TRUE" ;
VAL_ 1239 IHVSLF_VntLvl3 0 "FALSE" 1 "TRUE" ;
VAL_ 1239 IHVSLF_HtdBckLvl2 0 "FALSE" 1 "TRUE" ;
VAL_ 1239 IHVSLF_HtdBckMd 0 "FALSE" 1 "TRUE" ;
VAL_ 1239 IHVSLF_HtdCushBckLvl1 0 "FALSE" 1 "TRUE" ;
VAL_ 1239 IHVSLF_VntAuto 0 "FALSE" 1 "TRUE" ;
VAL_ 1239 IHVSLF_HtdCushBckLvl2 0 "FALSE" 1 "TRUE" ;
VAL_ 1239 IHVSLF_VntMd 0 "FALSE" 1 "TRUE" ;
VAL_ 1239 IHVSRF_VntLvl2 0 "FALSE" 1 "TRUE" ;
VAL_ 1239 IHVSRF_HtdCushBckMd 0 "FALSE" 1 "TRUE" ;
VAL_ 1239 IHVSRF_HtdBckLvl3 0 "FALSE" 1 "TRUE" ;
VAL_ 1239 IHVSRF_HtdCushBckAuto 0 "FALSE" 1 "TRUE" ;
VAL_ 1239 IHVSRF_HtdCushBckLvl3 0 "FALSE" 1 "TRUE" ;
VAL_ 1239 IHVSRF_HtdBckAuto 0 "FALSE" 1 "TRUE" ;
VAL_ 1239 IHVSRF_HtdCushBckLvl1 0 "FALSE" 1 "TRUE" ;
VAL_ 1239 IHVSRF_VntLvl1 0 "FALSE" 1 "TRUE" ;
VAL_ 1239 TDOSWCCSV_CrSetVal 0 "SETTING_UNKNOWN" 1 "OFF" 2 "ON" 3 "RESERVED_3" 4 "RESERVED_4" 5 "RESERVED_5" 6 "RESERVED_6" 7 "RESERVED_7" ;
VAL_ 1239 IHVSRF_VntAuto 0 "FALSE" 1 "TRUE" ;
VAL_ 1239 IHVSRF_HtdBckLvl1 0 "FALSE" 1 "TRUE" ;
VAL_ 1239 IHVSRF_HtdBckLvl2 0 "FALSE" 1 "TRUE" ;
VAL_ 1239 IHVSRF_VntLvl3 0 "FALSE" 1 "TRUE" ;
VAL_ 1239 IHVSRF_HtdCushBckLvl2 0 "FALSE" 1 "TRUE" ;
VAL_ 1239 IHVSRF_VntMd 0 "FALSE" 1 "TRUE" ;
VAL_ 1239 TDSLCCSV_CrSetVal 0 "SETTING_UNKNOWN" 1 "OFF" 2 "ON" 3 "RESERVED_3" 4 "RESERVED_4" 5 "RESERVED_5" 6 "RESERVED_6" 7 "RESERVED_7" ;
VAL_ 1211 AmbtLgtMnMenuTyp 0 "Off" 1 "RGB Lighting" 2 "Ambient Brightness Only" 3 "Reserved 1" 4 "Reserved 2" 5 "Reserved 3" 6 "Reserved 4" 7 "Reserved 5" ;
VAL_ 1211 ConThftAlrmTrg 0 "NO_DATA" 1 "DRIVER DOOR AJAR" 2 "CODRIVER DOOR AJAR" 3 "LEFT REAR DOOR AJAR" 4 "RIGHT REAR DOOR AJAR" 5 "GLASS BREAKAGE" 6 "HOOD AJAR" 7 "INTRUSION" 8 "INCLINATION" 9 "REAR CLOSURE AJAR" 10 "LIFTGLASS AJAR" 11 "TARGA AJAR" 12 "TONNEAU AJAR" 13 "VEHICLE POWER MODE" 14 "CHARGE CORD ALERT" 15 "WHEEL TAMPER" 16 "PANIC ALARM" 17 "MODULE RESET" 18 "ENHANCED SERVICES ALARM" 19 "Trailer Theft" ;
VAL_ 1211 BattVltIRq 0 "Battery Voltage OK" 1 "Battery Voltage Low" 2 "Battery Voltage High" 3 "Battery Voltage Very Low" ;
VAL_ 1211 AlrmClckMgrAlrmCmdFtr6 0 "InActive" 1 "Active" 2 "Expired" ;
VAL_ 1211 BdyCtlTopSpdLimSrc 0 "None" 1 "Teen" 2 "Valet" 3 "HoodOpen" 4 "Reserved" 5 "Reserved" 6 "Reserved" 7 "Reserved" ;
VAL_ 1211 BdyCtlTopSpdLimIndOn 0 "FALSE" 1 "TRUE" ;
VAL_ 1211 BdyCtlAccelLimIndOn 0 "FALSE" 1 "TRUE" ;
VAL_ 1211 BatLoStrtVehIndOn 0 "FALSE" 1 "TRUE" ;
VAL_ 1211 AutoLgtsInActvIndOn 0 "FALSE" 1 "TRUE" ;
VAL_ 1211 AutoLgtsActvIndOn 0 "FALSE" 1 "TRUE" ;
VAL_ 1211 ACCmpsrOprtng 0 "FALSE" 1 "TRUE" ;
VAL_ 1211 HtdFrntWSSt 0 "UNKNOWN" 1 "OFF" 2 "ON" ;
VAL_ 1211 ConThftAttmpdIO 0 "FALSE" 1 "TRUE" ;
VAL_ 1211 CnvtBkWndNotNormzIO 0 "FALSE" 1 "TRUE" ;
VAL_ 1211 CmpSftTopMotBfrOpTrnkIO 0 "FALSE" 1 "TRUE" ;
VAL_ 1211 CmbdDrHndlActvRF 0 "INACTIVE" 1 "ACTIVE" ;
VAL_ 1211 CmbdDrHndlActvLF 0 "INACTIVE" 1 "ACTIVE" ;
VAL_ 1211 ClmSysDfgRdcdIndOn 0 "FALSE" 1 "TRUE" ;
VAL_ 1211 ClmSysDfgActvIndOn 0 "FALSE" 1 "TRUE" ;
VAL_ 1211 ClmCtlBatSvrIndOn 0 "FALSE" 1 "TRUE" ;
VAL_ 1211 FobProgMdStatCmplt 0 "FALSE" 1 "TRUE" ;
VAL_ 1211 FobPrevLrndIndOn 0 "FALSE" 1 "TRUE" ;
VAL_ 1211 FobPogLimRchdIndOn 0 "FALSE" 1 "TRUE" ;
VAL_ 1211 EntrFobProgIndOn 0 "FALSE" 1 "TRUE" ;
VAL_ 1211 DlydAccTmrActv 0 "FALSE" 1 "TRUE" ;
VAL_ 1211 CrgLghtEnbldIO 0 "FALSE" 1 "TRUE" ;
VAL_ 1211 CrgLghtDsbldIO 0 "FALSE" 1 "TRUE" ;
VAL_ 1211 ConThftSrvcIO 0 "FALSE" 1 "TRUE" ;
VAL_ 1211 HiVltgHtrFaildIndOn 0 "FALSE" 1 "TRUE" ;
VAL_ 1211 HiBmIO 0 "FALSE" 1 "TRUE" ;
VAL_ 1211 HazSwAtvIO 0 "FALSE" 1 "TRUE" ;
VAL_ 1211 HVAC_StngsCtrlAvlbl 0 "FALSE" 1 "TRUE" ;
VAL_ 1211 FrtSnshdNormzRqrdIO 0 "FALSE" 1 "TRUE" ;
VAL_ 1211 FrtCmptServIndOn 0 "FALSE" 1 "TRUE" ;
VAL_ 1211 FrtClmAppFltDtnActv 0 "FALSE" 1 "TRUE" ;
VAL_ 1211 FuelOprtdHtrOprtgMode 0 "Unknown" 1 "Off" 2 "Parkheater" 3 "auxiliary mode" 4 "ventilation" ;
VAL_ 1211 HtdFrtWshldUnvIndOn 0 "FALSE" 1 "TRUE" ;
VAL_ 1211 HiVltgHtrOvrTempIndOn 0 "FALSE" 1 "TRUE" ;
VAL_ 1212 IAQI_IntrAirQltyGasStat 0 "NoDisplay" 1 "AQIstate1" 2 "AQIstate2" 3 "AQIstate3" 4 "AQIstate4" 5 "AQIstate5" 6 "AQIstate6" 7 "NoDataAvailable" 8 "ServiceSensor" 9 "Unknown" ;
VAL_ 1212 IAQI_IntrAirQltyOvrallStat 0 "NoDisplay" 1 "AQIstate1" 2 "AQIstate2" 3 "AQIstate3" 4 "AQIstate4" 5 "AQIstate5" 6 "AQIstate6" 7 "NoDataAvailable" 8 "ServiceSensor" 9 "Unknown" ;
VAL_ 1212 IAQI_IntrAirQltyPrtclteStat 0 "NoDisplay" 1 "AQIstate1" 2 "AQIstate2" 3 "AQIstate3" 4 "AQIstate4" 5 "AQIstate5" 6 "AQIstate6" 7 "NoDataAvailable" 8 "ServiceSensor" 9 "Unknown" ;
VAL_ 1213 TDRCADD_WOTEvnts 0 "FALSE" 1 "TRUE" ;
VAL_ 1213 TDRCADD_StCtrlEvnts 0 "FALSE" 1 "TRUE" ;
VAL_ 1213 TDRCADD_OvrSpdDistDrvn 0 "FALSE" 1 "TRUE" ;
VAL_ 1213 TDRCADD_ABSAtvEvt 0 "FALSE" 1 "TRUE" ;
VAL_ 1213 TDRCADD_DistDrvn 0 "FALSE" 1 "TRUE" ;
VAL_ 1213 TDRCADD_FCHdwyAlrt 0 "FALSE" 1 "TRUE" ;
VAL_ 1213 TDRCADD_LKAstAlrtsEvnts 0 "FALSE" 1 "TRUE" ;
VAL_ 1213 TDRCADD_MaxSpd 0 "FALSE" 1 "TRUE" ;
VAL_ 1213 TDRCADD_TrCtrlEvnts 0 "FALSE" 1 "TRUE" ;
VAL_ 1213 TDRCADD_FCMBrEvts 0 "FALSE" 1 "TRUE" ;
VAL_ 1213 TDRCADD_LDWEvnts 0 "FALSE" 1 "TRUE" ;
VAL_ 1213 TDRCADD_RCMBrEvts 0 "FALSE" 1 "TRUE" ;
VAL_ 1213 TDRCADD_OvSpdEvnt 0 "FALSE" 1 "TRUE" ;
VAL_ 1213 TDRCADD_DrwDrvAlrt 0 "FALSE" 1 "TRUE" ;
VAL_ 1213 TDRCADD_FCImntAlrts 0 "FALSE" 1 "TRUE" ;
VAL_ 1213 TDRCADD_UnbckldDistDrvn 0 "FALSE" 1 "TRUE" ;
VAL_ 1213 WndNormzRR 0 "FALSE" 1 "TRUE" ;
VAL_ 1213 WndNormzRF 0 "FALSE" 1 "TRUE" ;
VAL_ 1213 WndNormzLR 0 "FALSE" 1 "TRUE" ;
VAL_ 1213 WndNormzLF 0 "FALSE" 1 "TRUE" ;
VAL_ 1213 VTDDrvMsgIO 0 "FALSE" 1 "TRUE" ;
VAL_ 1213 VTDDrvIndReq 0 "OFF" 1 "ON" 2 "0.5_Hz" 3 "1_Hz" 4 "2_Hz" 5 "4_Hz" 6 "RESERVED" ;
VAL_ 1213 WndNtNrmzdIORR 0 "FALSE" 1 "TRUE" ;
VAL_ 1213 WndNtNrmzdIOLR 0 "FALSE" 1 "TRUE" ;
VAL_ 1213 WndNtNrmzdIODrv 0 "FALSE" 1 "TRUE" ;
VAL_ 1213 WndNtNrmzdIOCoDrv 0 "FALSE" 1 "TRUE" ;
VAL_ 1214 TirePrsStatLR 0 "Unknown" 1 "Nominal" 2 "Low - Service Now" 3 "Low" 4 "Low - Extended Mobility" 5 "High" ;
VAL_ 1214 TirePrsStatLR_Inv 0 "FALSE" 1 "TRUE" ;
VAL_ 1214 TirePrsStatLF 0 "Unknown" 1 "Nominal" 2 "Low - Service Now" 3 "Low" 4 "Low - Extended Mobility" 5 "High" ;
VAL_ 1214 TirePrsStatLF_Inv 0 "FALSE" 1 "TRUE" ;
VAL_ 1214 TirePrsStatRR 0 "Unknown" 1 "Nominal" 2 "Low - Service Now" 3 "Low" 4 "Low - Extended Mobility" 5 "High" ;
VAL_ 1214 TirePrsStatRR_Inv 0 "FALSE" 1 "TRUE" ;
VAL_ 1214 TirePrsStatRF 0 "Unknown" 1 "Nominal" 2 "Low - Service Now" 3 "Low" 4 "Low - Extended Mobility" 5 "High" ;
VAL_ 1214 TirePrsStatRF_Inv 0 "FALSE" 1 "TRUE" ;
VAL_ 1214 TrPrsMntrTrLdStat 0 "Unkown" 1 "Light Load" 2 "Best Economy Load" 3 "Max Load" ;
VAL_ 1214 TrlrLtngSeqStat 0 "Sequence_Off" 1 "Sequence_On" ;
VAL_ 1214 TrPrsMntrSysFld 0 "FALSE" 1 "TRUE" ;
VAL_ 1214 TlmtcsImmbAtv 0 "FALSE" 1 "TRUE" ;
VAL_ 1214 TirePrsLrnActIO 0 "FALSE" 1 "TRUE" ;
VAL_ 1214 TireLocatnWarnEn 0 "FALSE" 1 "TRUE" ;
VAL_ 1214 TPMTrLrnMdCmplt 0 "FALSE" 1 "TRUE" ;
VAL_ 1214 ValetMdResponse 0 "No Action" 1 "Valet Active - PIN Updated" 2 "Valet Active - PIN Invalid" 3 "Valet Inactive - PIN Valid" ;
VAL_ 1214 XmtrSecurConfRqrdIO 0 "FALSE" 1 "TRUE" ;
VAL_ 1214 VehLoBatIndOn 0 "FALSE" 1 "TRUE" ;
VAL_ 1214 UIDInStatusSD 0 "Not Present" 1 "Present" ;
VAL_ 1214 TxLrnFldIO 0 "FALSE" 1 "TRUE" ;
VAL_ 1214 TxBkUpLctIO 0 "FALSE" 1 "TRUE" ;
VAL_ 1214 TurnWprIntIO 0 "FALSE" 1 "TRUE" ;
VAL_ 1214 TrnstStrgLogisticsMdActivation 0 "FALSE" 1 "TRUE" ;
VAL_ 1215 TeenDrvRsp 0 "No_Action" 1 "Teen PIN Verified" 2 "Teen PIN Updated" 3 "Teen PIN Mismatch" 4 "Teen Key Set Complete" 5 "Teen Key Clear Complete" 6 "Key Not Present" 7 "Key Detected As Teen Key" 8 "Key Detected As NOT Teen Key" 9 "PIN Locked" ;
VAL_ 1215 TnDrvRptCrdAval 0 "FALSE" 1 "TRUE" ;
VAL_ 1215 TnDrvPINStrd 0 "FALSE" 1 "TRUE" ;
VAL_ 1215 TnDrvOvrSpdIO 0 "FALSE" 1 "TRUE" ;
VAL_ 1217 RemCtrlFobNumForProg 0 "No Fob" 1 "Remote Control Fob #1" 2 "Remote Control Fob #2" 3 "Remote Control Fob #3" 4 "Remote Control Fob #4" 5 "Remote Control Fob #5" 6 "Remote Control Fob #6" 7 "Remote Control Fob #7" 8 "Remote Control Fob #8" 9 "Reserved_1" 10 "Reserved_2" 11 "Reserved_3" 12 "Reserved_4" 13 "Reserved_5" 14 "Reserved_6" 15 "Reserved_7" ;
VAL_ 1217 DrExtHndlActnStatRR 0 "INACTIVE" 1 "ACTIVE" ;
VAL_ 1217 DrExtHndlActnStatRF 0 "INACTIVE" 1 "ACTIVE" ;
VAL_ 1217 SnrfPstnSts 0 "Fully Closed" 1 "Vent" 2 "Partially Open" 3 "Fully Open" 4 "Comfort Open" ;
VAL_ 1217 ServPwrLftgtIndOn 0 "FALSE" 1 "TRUE" ;
VAL_ 1217 ServKylsStSysIO 0 "FALSE" 1 "TRUE" ;
VAL_ 1217 ServHtdStrgWhlIndOn 0 "FALSE" 1 "TRUE" ;
VAL_ 1217 ServDrLtchSysIO 0 "FALSE" 1 "TRUE" ;
VAL_ 1217 ServBatChrgSysIndOn 0 "FALSE" 1 "TRUE" ;
VAL_ 1217 RmtCtlFobBatLoIndOn 0 "FALSE" 1 "TRUE" ;
VAL_ 1217 DrIntHndlActnStatRR 0 "INACTIVE" 1 "ACTIVE" ;
VAL_ 1217 DrIntHndlActnStatRF 0 "INACTIVE" 1 "ACTIVE" ;
VAL_ 1217 TnDrvDRLOffUnbIO 0 "FALSE" 1 "TRUE" ;
VAL_ 1217 TnDrvALCOffUnbIO 0 "FALSE" 1 "TRUE" ;
VAL_ 1217 TeenDrvFtrAvl 0 "FALSE" 1 "TRUE" ;
VAL_ 1217 StlthModeActv 0 "FALSE" 1 "TRUE" ;
VAL_ 1217 StNtLtchdThrdRowIO 0 "FALSE" 1 "TRUE" ;
VAL_ 1217 SnrfNormzRqrdIO 0 "FALSE" 1 "TRUE" ;
VAL_ 1217 ShftoNeutIndOn 0 "FALSE" 1 "TRUE" ;
VAL_ 1218 DrExtHndlActnStatLF 0 "INACTIVE" 1 "ACTIVE" ;
VAL_ 1218 LstKyFbFnctnReq 0 "No Request" 1 "Remote Door Unlock Request" 2 "Remote Door Lock Request" 3 "Remote Start Request" 4 "Remote Stop Request" 5 "Remote Rear Closure Release Request" 6 "Remote Power Rear Closure Start Request" 7 "Remote Power Rear Closure Stop Request" 8 "Remote Fuel Operated Heater Request Off" 9 "RFA Mirror Unfold Request" 10 "RFA Mirror Fold Request" 11 "RFA Window Open Request" 12 "RFA Windows Close Request" 13 "Remote Fuel Operated Heater Request On" 14 "Remote Power Top Open" 15 "Remote Power Top Close" 16 "Remote Power Top Pause" 17 "Remote Power Top Stop" 18 "Remote Panic Alarm" 19 "Remote Locator Alarm" 20 "Remote Front Closure Release Request" ;
VAL_ 1218 IndLowSpdPlltnTkngRecircActMsg 0 "FALSE" 1 "TRUE" ;
VAL_ 1218 IndIntrAirQltyDispActv 0 "FALSE" 1 "TRUE" ;
VAL_ 1218 IndFogPrtcTkngFrshAirActMsg 0 "FALSE" 1 "TRUE" ;
VAL_ 1218 IndAirQltSysTkngRecircActMsg 0 "FALSE" 1 "TRUE" ;
VAL_ 1218 IndAC_OnBatCoolMsg 0 "FALSE" 1 "TRUE" ;
VAL_ 1218 DrIntHndlActnStatLR 0 "INACTIVE" 1 "ACTIVE" ;
VAL_ 1218 DrIntHndlActnStatLF 0 "INACTIVE" 1 "ACTIVE" ;
VAL_ 1218 DrExtHndlActnStatLR 0 "INACTIVE" 1 "ACTIVE" ;
VAL_ 1218 PwrLftgtOffIndOn 0 "FALSE" 1 "TRUE" ;
VAL_ 1218 PrkLmpIO 0 "FALSE" 1 "TRUE" ;
VAL_ 1218 NghtSchmAtv 0 "FALSE" 1 "TRUE" ;
VAL_ 1218 LdShedRdcdFtrsIndOn 0 "FALSE" 1 "TRUE" ;
VAL_ 1218 KyIdDevNotPrIO 0 "FALSE" 1 "TRUE" ;
VAL_ 1218 KeyInWrnIO 0 "FALSE" 1 "TRUE" ;
VAL_ 1218 IntrSnsDsbld 0 "FALSE" 1 "TRUE" ;
VAL_ 1218 IndTmpUnts 0 "Celcius" 1 "Fahrenheit" ;
VAL_ 1218 IndInzrStat 0 "OFF" 1 "Ionizer ON" 2 "Ionizer OFF" 3 "Ionizer LO" 4 "Ionizer HI" ;
VAL_ 1218 RrStRmndrIndOn 0 "FALSE" 1 "TRUE" ;
VAL_ 1218 RrSnshdNormzRqrdIO 0 "FALSE" 1 "TRUE" ;
VAL_ 1218 RrDrUnlckIO 0 "FALSE" 1 "TRUE" ;
VAL_ 1218 RnSnsOffIO 0 "FALSE" 1 "TRUE" ;
VAL_ 1218 RnSnsActIO 0 "FALSE" 1 "TRUE" ;
VAL_ 1218 PwrLftgtUnvIndOn 0 "FALSE" 1 "TRUE" ;
VAL_ 1175 AutDrvLckCstAvlFlg1 0 "FALSE" 1 "TRUE" ;
VAL_ 1175 AirQltySnsCstAvlFlg7 0 "FALSE" 1 "TRUE" ;
VAL_ 1175 AirQltySnsCstAvlFlg6 0 "FALSE" 1 "TRUE" ;
VAL_ 1175 AirQltySnsCstAvlFlg5 0 "FALSE" 1 "TRUE" ;
VAL_ 1175 AirQltySnsCstAvlFlg4 0 "FALSE" 1 "TRUE" ;
VAL_ 1175 AirQltySnsCstAvlFlg3 0 "FALSE" 1 "TRUE" ;
VAL_ 1175 AirQltySnsCstAvlFlg2 0 "FALSE" 1 "TRUE" ;
VAL_ 1175 AirQltySnsCstAvlFlg1 0 "FALSE" 1 "TRUE" ;
VAL_ 1175 AutMirFldCstAvlFlg2 0 "FALSE" 1 "TRUE" ;
VAL_ 1175 AutMirFldCstAvlFlg1 0 "FALSE" 1 "TRUE" ;
VAL_ 1175 AutDrvLckCstAvlFlg7 0 "FALSE" 1 "TRUE" ;
VAL_ 1175 AutDrvLckCstAvlFlg6 0 "FALSE" 1 "TRUE" ;
VAL_ 1175 AutDrvLckCstAvlFlg5 0 "FALSE" 1 "TRUE" ;
VAL_ 1175 AutDrvLckCstAvlFlg4 0 "FALSE" 1 "TRUE" ;
VAL_ 1175 AutDrvLckCstAvlFlg3 0 "FALSE" 1 "TRUE" ;
VAL_ 1175 AutDrvLckCstAvlFlg2 0 "FALSE" 1 "TRUE" ;
VAL_ 1175 AutUnlckCstAvlFlg3 0 "FALSE" 1 "TRUE" ;
VAL_ 1175 AutUnlckCstAvlFlg2 0 "FALSE" 1 "TRUE" ;
VAL_ 1175 AutUnlckCstAvlFlg1 0 "FALSE" 1 "TRUE" ;
VAL_ 1175 AutMirFldCstAvlFlg7 0 "FALSE" 1 "TRUE" ;
VAL_ 1175 AutMirFldCstAvlFlg6 0 "FALSE" 1 "TRUE" ;
VAL_ 1175 AutMirFldCstAvlFlg5 0 "FALSE" 1 "TRUE" ;
VAL_ 1175 AutMirFldCstAvlFlg4 0 "FALSE" 1 "TRUE" ;
VAL_ 1175 AutMirFldCstAvlFlg3 0 "FALSE" 1 "TRUE" ;
VAL_ 1175 AutoAirDstCstAvlFlg4 0 "FALSE" 1 "TRUE" ;
VAL_ 1175 AutoAirDstCstAvlFlg3 0 "FALSE" 1 "TRUE" ;
VAL_ 1175 AutoAirDstCstAvlFlg2 0 "FALSE" 1 "TRUE" ;
VAL_ 1175 AutoAirDstCstAvlFlg1 0 "FALSE" 1 "TRUE" ;
VAL_ 1175 AutUnlckCstAvlFlg7 0 "FALSE" 1 "TRUE" ;
VAL_ 1175 AutUnlckCstAvlFlg6 0 "FALSE" 1 "TRUE" ;
VAL_ 1175 AutUnlckCstAvlFlg5 0 "FALSE" 1 "TRUE" ;
VAL_ 1175 AutUnlckCstAvlFlg4 0 "FALSE" 1 "TRUE" ;
VAL_ 1175 AutoCoolStCstAvlFlg5 0 "FALSE" 1 "TRUE" ;
VAL_ 1175 AutoCoolStCstAvlFlg4 0 "FALSE" 1 "TRUE" ;
VAL_ 1175 AutoCoolStCstAvlFlg3 0 "FALSE" 1 "TRUE" ;
VAL_ 1175 AutoCoolStCstAvlFlg2 0 "FALSE" 1 "TRUE" ;
VAL_ 1175 AutoCoolStCstAvlFlg1 0 "FALSE" 1 "TRUE" ;
VAL_ 1175 AutoAirDstCstAvlFlg7 0 "FALSE" 1 "TRUE" ;
VAL_ 1175 AutoAirDstCstAvlFlg6 0 "FALSE" 1 "TRUE" ;
VAL_ 1175 AutoAirDstCstAvlFlg5 0 "FALSE" 1 "TRUE" ;
VAL_ 1175 AutoDfgCstAvlFlg6 0 "FALSE" 1 "TRUE" ;
VAL_ 1175 AutoDfgCstAvlFlg5 0 "FALSE" 1 "TRUE" ;
VAL_ 1175 AutoDfgCstAvlFlg4 0 "FALSE" 1 "TRUE" ;
VAL_ 1175 AutoDfgCstAvlFlg3 0 "FALSE" 1 "TRUE" ;
VAL_ 1175 AutoDfgCstAvlFlg2 0 "FALSE" 1 "TRUE" ;
VAL_ 1175 AutoDfgCstAvlFlg1 0 "FALSE" 1 "TRUE" ;
VAL_ 1175 AutoCoolStCstAvlFlg7 0 "FALSE" 1 "TRUE" ;
VAL_ 1175 AutoCoolStCstAvlFlg6 0 "FALSE" 1 "TRUE" ;
VAL_ 1175 AutoFanCstAvlFlg7 0 "FALSE" 1 "TRUE" ;
VAL_ 1175 AutoFanCstAvlFlg6 0 "FALSE" 1 "TRUE" ;
VAL_ 1175 AutoFanCstAvlFlg5 0 "FALSE" 1 "TRUE" ;
VAL_ 1175 AutoFanCstAvlFlg4 0 "FALSE" 1 "TRUE" ;
VAL_ 1175 AutoFanCstAvlFlg3 0 "FALSE" 1 "TRUE" ;
VAL_ 1175 AutoFanCstAvlFlg2 0 "FALSE" 1 "TRUE" ;
VAL_ 1175 AutoFanCstAvlFlg1 0 "FALSE" 1 "TRUE" ;
VAL_ 1175 AutoDfgCstAvlFlg7 0 "FALSE" 1 "TRUE" ;
VAL_ 1175 AutoHtdStCstAvlFlg7 0 "FALSE" 1 "TRUE" ;
VAL_ 1175 AutoHtdStCstAvlFlg6 0 "FALSE" 1 "TRUE" ;
VAL_ 1175 AutoHtdStCstAvlFlg5 0 "FALSE" 1 "TRUE" ;
VAL_ 1175 AutoHtdStCstAvlFlg4 0 "FALSE" 1 "TRUE" ;
VAL_ 1175 AutoHtdStCstAvlFlg3 0 "FALSE" 1 "TRUE" ;
VAL_ 1175 AutoHtdStCstAvlFlg2 0 "FALSE" 1 "TRUE" ;
VAL_ 1175 AutoHtdStCstAvlFlg1 0 "FALSE" 1 "TRUE" ;
VAL_ 1176 AutoRrWpCstAvlFlg7 0 "FALSE" 1 "TRUE" ;
VAL_ 1176 AutoRrWpCstAvlFlg6 0 "FALSE" 1 "TRUE" ;
VAL_ 1176 AutoRrWpCstAvlFlg5 0 "FALSE" 1 "TRUE" ;
VAL_ 1176 AutoRrWpCstAvlFlg4 0 "FALSE" 1 "TRUE" ;
VAL_ 1176 AutoRrWpCstAvlFlg3 0 "FALSE" 1 "TRUE" ;
VAL_ 1176 AutoRrWpCstAvlFlg2 0 "FALSE" 1 "TRUE" ;
VAL_ 1176 AutoRrWpCstAvlFlg1 0 "FALSE" 1 "TRUE" ;
VAL_ 1176 ExtLghtCstAvlFlg1 0 "FALSE" 1 "TRUE" ;
VAL_ 1176 DaytimeTlLghtsCstAvlFlg7 0 "FALSE" 1 "TRUE" ;
VAL_ 1176 DaytimeTlLghtsCstAvlFlg6 0 "FALSE" 1 "TRUE" ;
VAL_ 1176 DaytimeTlLghtsCstAvlFlg5 0 "FALSE" 1 "TRUE" ;
VAL_ 1176 DaytimeTlLghtsCstAvlFlg4 0 "FALSE" 1 "TRUE" ;
VAL_ 1176 DaytimeTlLghtsCstAvlFlg3 0 "FALSE" 1 "TRUE" ;
VAL_ 1176 DaytimeTlLghtsCstAvlFlg2 0 "FALSE" 1 "TRUE" ;
VAL_ 1176 DaytimeTlLghtsCstAvlFlg1 0 "FALSE" 1 "TRUE" ;
VAL_ 1176 HFRCCstAvlFlg2 0 "FALSE" 1 "TRUE" ;
VAL_ 1176 HFRCCstAvlFlg1 0 "FALSE" 1 "TRUE" ;
VAL_ 1176 ExtLghtCstAvlFlg7 0 "FALSE" 1 "TRUE" ;
VAL_ 1176 ExtLghtCstAvlFlg6 0 "FALSE" 1 "TRUE" ;
VAL_ 1176 ExtLghtCstAvlFlg5 0 "FALSE" 1 "TRUE" ;
VAL_ 1176 ExtLghtCstAvlFlg4 0 "FALSE" 1 "TRUE" ;
VAL_ 1176 ExtLghtCstAvlFlg3 0 "FALSE" 1 "TRUE" ;
VAL_ 1176 ExtLghtCstAvlFlg2 0 "FALSE" 1 "TRUE" ;
VAL_ 1176 HFRCCstAvlFlg7 0 "FALSE" 1 "TRUE" ;
VAL_ 1176 HFRCCstAvlFlg6 0 "FALSE" 1 "TRUE" ;
VAL_ 1176 HFRCCstAvlFlg5 0 "FALSE" 1 "TRUE" ;
VAL_ 1176 HFRCCstAvlFlg4 0 "FALSE" 1 "TRUE" ;
VAL_ 1176 HFRCCstAvlFlg3 0 "FALSE" 1 "TRUE" ;
VAL_ 1177 IonzrCtrlCstAvlFlg4 0 "FALSE" 1 "TRUE" ;
VAL_ 1177 IonzrCtrlCstAvlFlg3 0 "FALSE" 1 "TRUE" ;
VAL_ 1177 IonzrCtrlCstAvlFlg2 0 "FALSE" 1 "TRUE" ;
VAL_ 1177 IonzrCtrlCstAvlFlg1 0 "FALSE" 1 "TRUE" ;
VAL_ 1177 LDCLCstAvlFlg5 0 "FALSE" 1 "TRUE" ;
VAL_ 1177 LDCLCstAvlFlg4 0 "FALSE" 1 "TRUE" ;
VAL_ 1177 LDCLCstAvlFlg3 0 "FALSE" 1 "TRUE" ;
VAL_ 1177 LDCLCstAvlFlg2 0 "FALSE" 1 "TRUE" ;
VAL_ 1177 LDCLCstAvlFlg1 0 "FALSE" 1 "TRUE" ;
VAL_ 1177 IonzrCtrlCstAvlFlg7 0 "FALSE" 1 "TRUE" ;
VAL_ 1177 IonzrCtrlCstAvlFlg6 0 "FALSE" 1 "TRUE" ;
VAL_ 1177 IonzrCtrlCstAvlFlg5 0 "FALSE" 1 "TRUE" ;
VAL_ 1177 OpDrAtLOCstAvlFlg6 0 "FALSE" 1 "TRUE" ;
VAL_ 1177 OpDrAtLOCstAvlFlg5 0 "FALSE" 1 "TRUE" ;
VAL_ 1177 OpDrAtLOCstAvlFlg4 0 "FALSE" 1 "TRUE" ;
VAL_ 1177 OpDrAtLOCstAvlFlg3 0 "FALSE" 1 "TRUE" ;
VAL_ 1177 OpDrAtLOCstAvlFlg2 0 "FALSE" 1 "TRUE" ;
VAL_ 1177 OpDrAtLOCstAvlFlg1 0 "FALSE" 1 "TRUE" ;
VAL_ 1177 LDCLCstAvlFlg7 0 "FALSE" 1 "TRUE" ;
VAL_ 1177 LDCLCstAvlFlg6 0 "FALSE" 1 "TRUE" ;
VAL_ 1177 PlltnCtrlCstAvlFlg7 0 "FALSE" 1 "TRUE" ;
VAL_ 1177 PlltnCtrlCstAvlFlg6 0 "FALSE" 1 "TRUE" ;
VAL_ 1177 PlltnCtrlCstAvlFlg5 0 "FALSE" 1 "TRUE" ;
VAL_ 1177 PlltnCtrlCstAvlFlg4 0 "FALSE" 1 "TRUE" ;
VAL_ 1177 PlltnCtrlCstAvlFlg3 0 "FALSE" 1 "TRUE" ;
VAL_ 1177 PlltnCtrlCstAvlFlg2 0 "FALSE" 1 "TRUE" ;
VAL_ 1177 PlltnCtrlCstAvlFlg1 0 "FALSE" 1 "TRUE" ;
VAL_ 1177 OpDrAtLOCstAvlFlg7 0 "FALSE" 1 "TRUE" ;
VAL_ 1177 PsvUnlckCstAvlFlg7 0 "FALSE" 1 "TRUE" ;
VAL_ 1177 PsvUnlckCstAvlFlg6 0 "FALSE" 1 "TRUE" ;
VAL_ 1177 PsvUnlckCstAvlFlg5 0 "FALSE" 1 "TRUE" ;
VAL_ 1177 PsvUnlckCstAvlFlg4 0 "FALSE" 1 "TRUE" ;
VAL_ 1177 PsvUnlckCstAvlFlg3 0 "FALSE" 1 "TRUE" ;
VAL_ 1177 PsvUnlckCstAvlFlg2 0 "FALSE" 1 "TRUE" ;
VAL_ 1177 PsvUnlckCstAvlFlg1 0 "FALSE" 1 "TRUE" ;
VAL_ 1178 RlkRtUlkDrCstAvlFlg1 0 "FALSE" 1 "TRUE" ;
VAL_ 1178 RemInVehRmndrCstAvlFlg7 0 "FALSE" 1 "TRUE" ;
VAL_ 1178 RemInVehRmndrCstAvlFlg6 0 "FALSE" 1 "TRUE" ;
VAL_ 1178 RemInVehRmndrCstAvlFlg5 0 "FALSE" 1 "TRUE" ;
VAL_ 1178 RemInVehRmndrCstAvlFlg4 0 "FALSE" 1 "TRUE" ;
VAL_ 1178 RemInVehRmndrCstAvlFlg3 0 "FALSE" 1 "TRUE" ;
VAL_ 1178 RemInVehRmndrCstAvlFlg2 0 "FALSE" 1 "TRUE" ;
VAL_ 1178 RemInVehRmndrCstAvlFlg1 0 "FALSE" 1 "TRUE" ;
VAL_ 1178 RmtSnrfOpCstAvlFlg2 0 "FALSE" 1 "TRUE" ;
VAL_ 1178 RmtSnrfOpCstAvlFlg1 0 "FALSE" 1 "TRUE" ;
VAL_ 1178 RlkRtUlkDrCstAvlFlg7 0 "FALSE" 1 "TRUE" ;
VAL_ 1178 RlkRtUlkDrCstAvlFlg6 0 "FALSE" 1 "TRUE" ;
VAL_ 1178 RlkRtUlkDrCstAvlFlg5 0 "FALSE" 1 "TRUE" ;
VAL_ 1178 RlkRtUlkDrCstAvlFlg4 0 "FALSE" 1 "TRUE" ;
VAL_ 1178 RlkRtUlkDrCstAvlFlg3 0 "FALSE" 1 "TRUE" ;
VAL_ 1178 RlkRtUlkDrCstAvlFlg2 0 "FALSE" 1 "TRUE" ;
VAL_ 1178 RmtStrtCoolStCstAvlFlg3 0 "FALSE" 1 "TRUE" ;
VAL_ 1178 RmtStrtCoolStCstAvlFlg2 0 "FALSE" 1 "TRUE" ;
VAL_ 1178 RmtStrtCoolStCstAvlFlg1 0 "FALSE" 1 "TRUE" ;
VAL_ 1178 RmtSnrfOpCstAvlFlg7 0 "FALSE" 1 "TRUE" ;
VAL_ 1178 RmtSnrfOpCstAvlFlg6 0 "FALSE" 1 "TRUE" ;
VAL_ 1178 RmtSnrfOpCstAvlFlg5 0 "FALSE" 1 "TRUE" ;
VAL_ 1178 RmtSnrfOpCstAvlFlg4 0 "FALSE" 1 "TRUE" ;
VAL_ 1178 RmtSnrfOpCstAvlFlg3 0 "FALSE" 1 "TRUE" ;
VAL_ 1178 RmtStrtHtdStCstAvlFlg4 0 "FALSE" 1 "TRUE" ;
VAL_ 1178 RmtStrtHtdStCstAvlFlg3 0 "FALSE" 1 "TRUE" ;
VAL_ 1178 RmtStrtHtdStCstAvlFlg2 0 "FALSE" 1 "TRUE" ;
VAL_ 1178 RmtStrtHtdStCstAvlFlg1 0 "FALSE" 1 "TRUE" ;
VAL_ 1178 RmtStrtCoolStCstAvlFlg7 0 "FALSE" 1 "TRUE" ;
VAL_ 1178 RmtStrtCoolStCstAvlFlg6 0 "FALSE" 1 "TRUE" ;
VAL_ 1178 RmtStrtCoolStCstAvlFlg5 0 "FALSE" 1 "TRUE" ;
VAL_ 1178 RmtStrtCoolStCstAvlFlg4 0 "FALSE" 1 "TRUE" ;
VAL_ 1178 RnSnsCstAvlFlg5 0 "FALSE" 1 "TRUE" ;
VAL_ 1178 RnSnsCstAvlFlg4 0 "FALSE" 1 "TRUE" ;
VAL_ 1178 RnSnsCstAvlFlg3 0 "FALSE" 1 "TRUE" ;
VAL_ 1178 RnSnsCstAvlFlg2 0 "FALSE" 1 "TRUE" ;
VAL_ 1178 RnSnsCstAvlFlg1 0 "FALSE" 1 "TRUE" ;
VAL_ 1178 RmtStrtHtdStCstAvlFlg7 0 "FALSE" 1 "TRUE" ;
VAL_ 1178 RmtStrtHtdStCstAvlFlg6 0 "FALSE" 1 "TRUE" ;
VAL_ 1178 RmtStrtHtdStCstAvlFlg5 0 "FALSE" 1 "TRUE" ;
VAL_ 1178 RrDfgStUpCstAvlFlg6 0 "FALSE" 1 "TRUE" ;
VAL_ 1178 RrDfgStUpCstAvlFlg5 0 "FALSE" 1 "TRUE" ;
VAL_ 1178 RrDfgStUpCstAvlFlg4 0 "FALSE" 1 "TRUE" ;
VAL_ 1178 RrDfgStUpCstAvlFlg3 0 "FALSE" 1 "TRUE" ;
VAL_ 1178 RrDfgStUpCstAvlFlg2 0 "FALSE" 1 "TRUE" ;
VAL_ 1178 RrDfgStUpCstAvlFlg1 0 "FALSE" 1 "TRUE" ;
VAL_ 1178 RnSnsCstAvlFlg7 0 "FALSE" 1 "TRUE" ;
VAL_ 1178 RnSnsCstAvlFlg6 0 "FALSE" 1 "TRUE" ;
VAL_ 1178 RrStRmndrEnblDsblCstAvlFlg7 0 "FALSE" 1 "TRUE" ;
VAL_ 1178 RrStRmndrEnblDsblCstAvlFlg6 0 "FALSE" 1 "TRUE" ;
VAL_ 1178 RrStRmndrEnblDsblCstAvlFlg5 0 "FALSE" 1 "TRUE" ;
VAL_ 1178 RrStRmndrEnblDsblCstAvlFlg4 0 "FALSE" 1 "TRUE" ;
VAL_ 1178 RrStRmndrEnblDsblCstAvlFlg3 0 "FALSE" 1 "TRUE" ;
VAL_ 1178 RrStRmndrEnblDsblCstAvlFlg2 0 "FALSE" 1 "TRUE" ;
VAL_ 1178 RrStRmndrEnblDsblCstAvlFlg1 0 "FALSE" 1 "TRUE" ;
VAL_ 1178 RrDfgStUpCstAvlFlg7 0 "FALSE" 1 "TRUE" ;
VAL_ 1178 RrZnStUpCstAvlFlg7 0 "FALSE" 1 "TRUE" ;
VAL_ 1178 RrZnStUpCstAvlFlg6 0 "FALSE" 1 "TRUE" ;
VAL_ 1178 RrZnStUpCstAvlFlg5 0 "FALSE" 1 "TRUE" ;
VAL_ 1178 RrZnStUpCstAvlFlg4 0 "FALSE" 1 "TRUE" ;
VAL_ 1178 RrZnStUpCstAvlFlg3 0 "FALSE" 1 "TRUE" ;
VAL_ 1178 RrZnStUpCstAvlFlg2 0 "FALSE" 1 "TRUE" ;
VAL_ 1178 RrZnStUpCstAvlFlg1 0 "FALSE" 1 "TRUE" ;
VAL_ 1179 RemLftVehRmndrCstAvlFlg6 0 "FALSE" 1 "TRUE" ;
VAL_ 1179 RemLftVehRmndrCstAvlFlg5 0 "FALSE" 1 "TRUE" ;
VAL_ 1179 RemLftVehRmndrCstAvlFlg4 0 "FALSE" 1 "TRUE" ;
VAL_ 1179 RemLftVehRmndrCstAvlFlg3 0 "FALSE" 1 "TRUE" ;
VAL_ 1179 RemLftVehRmndrCstAvlFlg2 0 "FALSE" 1 "TRUE" ;
VAL_ 1179 RemLftVehRmndrCstAvlFlg1 0 "FALSE" 1 "TRUE" ;
VAL_ 1179 RVCBatSOCOver 0 "None" 1 "Plant Assembly Mode" 2 "Charge Recovery Mode" 3 "Default Mode" ;
VAL_ 1179 RevTltMirCstAvlFlg7 0 "FALSE" 1 "TRUE" ;
VAL_ 1179 RevTltMirCstAvlFlg6 0 "FALSE" 1 "TRUE" ;
VAL_ 1179 RevTltMirCstAvlFlg5 0 "FALSE" 1 "TRUE" ;
VAL_ 1179 RevTltMirCstAvlFlg4 0 "FALSE" 1 "TRUE" ;
VAL_ 1179 RevTltMirCstAvlFlg3 0 "FALSE" 1 "TRUE" ;
VAL_ 1179 RevTltMirCstAvlFlg2 0 "FALSE" 1 "TRUE" ;
VAL_ 1179 RevTltMirCstAvlFlg1 0 "FALSE" 1 "TRUE" ;
VAL_ 1179 RemLftVehRmndrCstAvlFlg7 0 "FALSE" 1 "TRUE" ;
VAL_ 1179 RtLkFdbkCstAvlFlg1 0 "FALSE" 1 "TRUE" ;
VAL_ 1179 RmtWndOpCstAvlFlg7 0 "FALSE" 1 "TRUE" ;
VAL_ 1179 RmtWndOpCstAvlFlg6 0 "FALSE" 1 "TRUE" ;
VAL_ 1179 RmtWndOpCstAvlFlg5 0 "FALSE" 1 "TRUE" ;
VAL_ 1179 RmtWndOpCstAvlFlg4 0 "FALSE" 1 "TRUE" ;
VAL_ 1179 RmtWndOpCstAvlFlg3 0 "FALSE" 1 "TRUE" ;
VAL_ 1179 RmtWndOpCstAvlFlg2 0 "FALSE" 1 "TRUE" ;
VAL_ 1179 RmtWndOpCstAvlFlg1 0 "FALSE" 1 "TRUE" ;
VAL_ 1179 RtUlkLtFbCstAvlFlg2 0 "FALSE" 1 "TRUE" ;
VAL_ 1179 RtUlkLtFbCstAvlFlg1 0 "FALSE" 1 "TRUE" ;
VAL_ 1179 RtLkFdbkCstAvlFlg7 0 "FALSE" 1 "TRUE" ;
VAL_ 1179 RtLkFdbkCstAvlFlg6 0 "FALSE" 1 "TRUE" ;
VAL_ 1179 RtLkFdbkCstAvlFlg5 0 "FALSE" 1 "TRUE" ;
VAL_ 1179 RtLkFdbkCstAvlFlg4 0 "FALSE" 1 "TRUE" ;
VAL_ 1179 RtLkFdbkCstAvlFlg3 0 "FALSE" 1 "TRUE" ;
VAL_ 1179 RtLkFdbkCstAvlFlg2 0 "FALSE" 1 "TRUE" ;
VAL_ 1179 SelUlkCstAvlFlg3 0 "FALSE" 1 "TRUE" ;
VAL_ 1179 SelUlkCstAvlFlg2 0 "FALSE" 1 "TRUE" ;
VAL_ 1179 SelUlkCstAvlFlg1 0 "FALSE" 1 "TRUE" ;
VAL_ 1179 RtUlkLtFbCstAvlFlg7 0 "FALSE" 1 "TRUE" ;
VAL_ 1179 RtUlkLtFbCstAvlFlg6 0 "FALSE" 1 "TRUE" ;
VAL_ 1179 RtUlkLtFbCstAvlFlg5 0 "FALSE" 1 "TRUE" ;
VAL_ 1179 RtUlkLtFbCstAvlFlg4 0 "FALSE" 1 "TRUE" ;
VAL_ 1179 RtUlkLtFbCstAvlFlg3 0 "FALSE" 1 "TRUE" ;
VAL_ 1179 SelUlkCstAvlFlg7 0 "FALSE" 1 "TRUE" ;
VAL_ 1179 SelUlkCstAvlFlg6 0 "FALSE" 1 "TRUE" ;
VAL_ 1179 SelUlkCstAvlFlg5 0 "FALSE" 1 "TRUE" ;
VAL_ 1179 SelUlkCstAvlFlg4 0 "FALSE" 1 "TRUE" ;
VAL_ 1180 IDCTA_ClrTyp20Avl 0 "FALSE" 1 "TRUE" ;
VAL_ 1180 IDCTA_ClrTyp28Avl 0 "FALSE" 1 "TRUE" ;
VAL_ 1180 IDCTA_ClrTyp15Avl 0 "FALSE" 1 "TRUE" ;
VAL_ 1180 IDCTA_ClrTyp30Avl 0 "FALSE" 1 "TRUE" ;
VAL_ 1180 IDCTA_ClrTyp13Avl 0 "FALSE" 1 "TRUE" ;
VAL_ 1180 IDCTA_ClrTyp22Avl 0 "FALSE" 1 "TRUE" ;
VAL_ 1180 IDCTA_ClrTyp17Avl 0 "FALSE" 1 "TRUE" ;
VAL_ 1180 IDCTA_OffAvl 0 "FALSE" 1 "TRUE" ;
VAL_ 1180 IDCTA_ClrTyp29Avl 0 "FALSE" 1 "TRUE" ;
VAL_ 1180 IDCTA_ClrTyp8Avl 0 "FALSE" 1 "TRUE" ;
VAL_ 1180 IDCTA_ClrTyp27Avl 0 "FALSE" 1 "TRUE" ;
VAL_ 1180 IDCTA_ClrTyp1Avl 0 "FALSE" 1 "TRUE" ;
VAL_ 1180 IDCTA_ClrTyp14Avl 0 "FALSE" 1 "TRUE" ;
VAL_ 1180 IDCTA_ClrTyp25Avl 0 "FALSE" 1 "TRUE" ;
VAL_ 1180 IDCTA_ClrTyp3Avl 0 "FALSE" 1 "TRUE" ;
VAL_ 1180 IDCTA_ClrTyp12Avl 0 "FALSE" 1 "TRUE" ;
VAL_ 1180 IDCTA_ClrTyp18Avl 0 "FALSE" 1 "TRUE" ;
VAL_ 1180 IDCTA_ClrTyp9Avl 0 "FALSE" 1 "TRUE" ;
VAL_ 1180 IDCTA_ClrTyp16Avl 0 "FALSE" 1 "TRUE" ;
VAL_ 1180 IDCTA_ClrTyp21Avl 0 "FALSE" 1 "TRUE" ;
VAL_ 1180 IDCTA_ClrTyp11Avl 0 "FALSE" 1 "TRUE" ;
VAL_ 1180 IDCTA_ClrTyp5Avl 0 "FALSE" 1 "TRUE" ;
VAL_ 1180 IDCTA_ClrTyp24Avl 0 "FALSE" 1 "TRUE" ;
VAL_ 1180 IDCTA_ClrTyp7Avl 0 "FALSE" 1 "TRUE" ;
VAL_ 1180 IDATA_AnmTyp10Avl 0 "FALSE" 1 "TRUE" ;
VAL_ 1180 IDCTA_ClrTyp23Avl 0 "FALSE" 1 "TRUE" ;
VAL_ 1180 IDCTA_ClrTyp19Avl 0 "FALSE" 1 "TRUE" ;
VAL_ 1180 IDCTA_ClrTyp26Avl 0 "FALSE" 1 "TRUE" ;
VAL_ 1180 IDCTA_ClrTyp2Avl 0 "FALSE" 1 "TRUE" ;
VAL_ 1180 IDCTA_ClrTyp6Avl 0 "FALSE" 1 "TRUE" ;
VAL_ 1180 IDCTA_ClrTyp4Avl 0 "FALSE" 1 "TRUE" ;
VAL_ 1180 IDCTA_ClrTyp10Avl 0 "FALSE" 1 "TRUE" ;
VAL_ 1180 IDATA_AnmTyp7Avl 0 "FALSE" 1 "TRUE" ;
VAL_ 1180 IDATA_AnmTyp9Avl 0 "FALSE" 1 "TRUE" ;
VAL_ 1180 IDATA_AnmTyp3Avl 0 "FALSE" 1 "TRUE" ;
VAL_ 1180 IDATA_AnmTyp14Avl 0 "FALSE" 1 "TRUE" ;
VAL_ 1180 IDATA_AnmTyp12Avl 0 "FALSE" 1 "TRUE" ;
VAL_ 1180 IDATA_OffAvl 0 "FALSE" 1 "TRUE" ;
VAL_ 1180 IDATA_AnmTyp8Avl 0 "FALSE" 1 "TRUE" ;
VAL_ 1180 IDATA_AnmTyp13Avl 0 "FALSE" 1 "TRUE" ;
VAL_ 1180 WlkAwyLckCstAvlFlg2 0 "FALSE" 1 "TRUE" ;
VAL_ 1180 WlkAwyLckCstAvlFlg1 0 "FALSE" 1 "TRUE" ;
VAL_ 1180 IDATA_AnmTyp2Avl 0 "FALSE" 1 "TRUE" ;
VAL_ 1180 IDATA_AnmTyp4Avl 0 "FALSE" 1 "TRUE" ;
VAL_ 1180 IDATA_AnmTyp5Avl 0 "FALSE" 1 "TRUE" ;
VAL_ 1180 IDATA_AnmTyp1Avl 0 "FALSE" 1 "TRUE" ;
VAL_ 1180 IDATA_AnmTyp6Avl 0 "FALSE" 1 "TRUE" ;
VAL_ 1180 IDATA_AnmTyp11Avl 0 "FALSE" 1 "TRUE" ;
VAL_ 1180 WlkAwyLckCstAvlFlg7 0 "FALSE" 1 "TRUE" ;
VAL_ 1180 WlkAwyLckCstAvlFlg6 0 "FALSE" 1 "TRUE" ;
VAL_ 1180 WlkAwyLckCstAvlFlg5 0 "FALSE" 1 "TRUE" ;
VAL_ 1180 WlkAwyLckCstAvlFlg4 0 "FALSE" 1 "TRUE" ;
VAL_ 1180 WlkAwyLckCstAvlFlg3 0 "FALSE" 1 "TRUE" ;
VAL_ 1181 TrlrTireRRPres_Inv 0 "FALSE" 1 "TRUE" ;
VAL_ 1181 TrlrTireRRTemp_Inv 0 "FALSE" 1 "TRUE" ;
VAL_ 1181 VehLctrLghtsCstAvlFlg2 0 "FALSE" 1 "TRUE" ;
VAL_ 1181 VehLctrLghtsCstAvlFlg1 0 "FALSE" 1 "TRUE" ;
VAL_ 1181 TrlrTireRRPresSts 0 "Unknown" 1 "Normal" 2 "Low Pressure" 3 "Malfunction" 4 "Learning in Progress" 5 "Learn Tire" 6 "Tire Learning Complete" 7 "High Pressure" 8 "High Temperature" ;
VAL_ 1181 TrlrTireRRPresSts_Inv 0 "FALSE" 1 "TRUE" ;
VAL_ 1181 VehLctrLghtsCstAvlFlg7 0 "FALSE" 1 "TRUE" ;
VAL_ 1181 VehLctrLghtsCstAvlFlg6 0 "FALSE" 1 "TRUE" ;
VAL_ 1181 VehLctrLghtsCstAvlFlg5 0 "FALSE" 1 "TRUE" ;
VAL_ 1181 VehLctrLghtsCstAvlFlg4 0 "FALSE" 1 "TRUE" ;
VAL_ 1181 VehLctrLghtsCstAvlFlg3 0 "FALSE" 1 "TRUE" ;
